VERSION ""

NS_ :

BS_:

BU_: ECM

BO_ 262 ENGINE_FD_2: 64 ECM
 SG_ TxAC_EMCC_rq_W : 189|1@0+ (1,0) [0|1] "-"  Vector__XXX
 SG_ TRANS_CLU_SLIP_MODE_W : 71|3@0+ (1,0) [0|7] "-"  Vector__XXX
 SG_ StartRelayBCMCmd_W : 187|1@0+ (1,0) [0|1] "-"  Vector__XXX
 SG_ PowertrainPrplsnActv : 181|1@0+ (1,0) [0|1] "" Vector__XXX
 SG_ MessageCounter_ENGINE2 : 435|4@0+ (1,0) [0|15] "-"  Vector__XXX
 SG_ LV12PwrFreeRq_W : 176|1@0+ (1,0) [0|1] "-"  Vector__XXX
 SG_ KickDownRequest_W : 182|1@0+ (1,0) [0|1] "-"  Vector__XXX
 SG_ IntakeAirTemperature_W : 151|8@0+ (1,-40) [-40|214] "C"  Vector__XXX
 SG_ GasPedalPositionFailSts_W : 169|1@0+ (1,0) [0|1] "-"  Vector__XXX
 SG_ GasPedalPosition_W : 143|8@0+ (0.392,0) [0|99.568] "%"  Vector__XXX
 SG_ GasPedalGradient_W : 159|8@0+ (0.195,-25) [-25|24.53] "% /10ms"  Vector__XXX
 SG_ FeedbackASR_ESCReq_W : 186|1@0+ (1,0) [0|1] "-"  Vector__XXX
 SG_ EVRDesiredSetpoint : 135|8@0+ (0.0625,0) [0|15.875] "V"  Vector__XXX
 SG_ ESS_RqShftPark_W : 115|1@0+ (1,0) [0|0] "-"  Vector__XXX
 SG_ ESS_ENG_ST_W : 175|4@0+ (1,0) [0|15] "-"  Vector__XXX
 SG_ EngTrq_Enbl_Rq_TCM_W : 178|1@0+ (1,0) [0|1] "-"  Vector__XXX
 SG_ EngRPM_Tach : 7|16@0+ (1,0) [0|65534] "rpm"  Vector__XXX
 SG_ EngineSts_W : 87|2@0+ (1,0) [0|3] "-"  Vector__XXX
 SG_ EngineSpeedFailSts_W : 168|1@0+ (1,0) [0|1] "-"  Vector__XXX
 SG_ EngineSpeed_W : 21|14@0+ (1,0) [0|16382] "1/min"  Vector__XXX
 SG_ EngineIdleRefSpeed : 35|12@0+ (1,0) [0|4094] "1/min"  Vector__XXX
 SG_ EngineFrictionTorque_W : 112|9@0+ (1,0) [0|510] "Nm"  Vector__XXX
 SG_ ECM_LHOM_W : 188|1@0+ (1,0) [0|1] "-"  Vector__XXX
 SG_ ECM_LHOM_Trans_W : 117|2@0+ (1,0) [0|3] "-"  Vector__XXX
 SG_ ECM_IMMO_STAT_CANC_W : 23|2@0+ (1,0) [0|0] "-"  Vector__XXX
 SG_ ECM_AllwEV_W : 170|1@0+ (1,0) [0|0] "-"  Vector__XXX
 SG_ CRC_ENGINE2 : 447|8@0+ (1,0) [0|255] "-"  Vector__XXX
 SG_ CrankHold_W : 179|1@0+ (1,0) [0|1] "-"  Vector__XXX
 SG_ AlternatorFail_W : 114|1@0+ (1,0) [0|1] "-"  Vector__XXX
 SG_ ECM_ParkSL_Status : 437|2@0+ (1,0) [0|2] "-"  Vector__XXX
 SG_ EngTrqTgt_SEM : 276|13@0+ (0.25,-500) [-500|1547.5] "Nm"  Vector__XXX
 SG_ ESS_EBOOST_BRKHLD_STATUS : 279|3@0+ (1,0) [0|6] "-"  Vector__XXX
 SG_ Engine_Stall_Detected : 197|1@0+ (1,0) [0|1] "-"  Vector__XXX
 SG_ FullOFC_Actv : 183|1@0+ (1,0) [0|1] "" Vector__XXX
 SG_ FuelConsumption_GAG_3 : 251|20@0+ (0.0022,0) [0|2306.865] "Liter / hour"  Vector__XXX
 SG_ EngFSO_TCM_Allw : 39|1@0+ (1,0) [0|1] "" Vector__XXX

BO_ 258 BRAKE_FD_2: 64 Vector__XXX
 SG_ VehicleSpeedVSOSig : 4|13@0+ (0.0625,0) [0|511.875] "Km/h"  ECM
 SG_ MessageCounter_BRAKE2 : 435|4@0+ (1,0) [0|15] "-"  ECM
 SG_ LongAccelerationFailSts_BSM : 69|1@0+ (1,0) [0|1] "-"  ECM
 SG_ LongAcceleration_BSM : 35|12@0+ (0.02,-40.96) [-40.96|40.92] "m/s^2"  ECM
 SG_ LatAccelerationFailSts_BSM : 68|1@0+ (1,0) [0|1] "-"  ECM
 SG_ LatAcceleration_BSM : 19|12@0+ (0.02,-40.96) [-40.96|40.92] "m/s^2"  ECM
 SG_ ImpendingSkid : 205|1@0+ (1,0) [0|1] "-"  ECM
 SG_ ESP_Sys_Stat : 71|2@0+ (1,0) [0|3] "-"  ECM
 SG_ CRC_BRAKE2 : 447|8@0+ (1,0) [0|255] "-"  ECM
 SG_ BrakePedalPressure : 386|11@0+ (0.1,0) [0|200] "bar"  ECM
 SG_ BrakeInterventionSts : 103|1@0+ (1,0) [0|1] "-"  ECM
 SG_ BrakeBoostPressure : 370|11@0+ (0.1,0) [0|200] "bar"  ECM
 SG_ Brk_Stat : 343|2@0+ (1,0) [0|2] "-"  ECM
 SG_ TotIntdTotalBrkTorq_FW : 173|14@0+ (0.32,0) [0|5242.24] "Nm"  ECM
 SG_ CmndTotBrkFrictTorq_FW : 253|14@0+ (0.32,0) [0|5242.24] "Nm"  ECM

BO_ 476 AGSM_FD_2: 32 Vector__XXX
 SG_ MessageCounter_AGSM2 : 179|4@0+ (1,0) [0|15] "-"  ECM
 SG_ CRC_AGSM2 : 191|8@0+ (1,0) [0|255] "-"  ECM
 SG_ ShiftLeverPositionReq : 95|4@0+ (1,0) [0|15] "-"  ECM

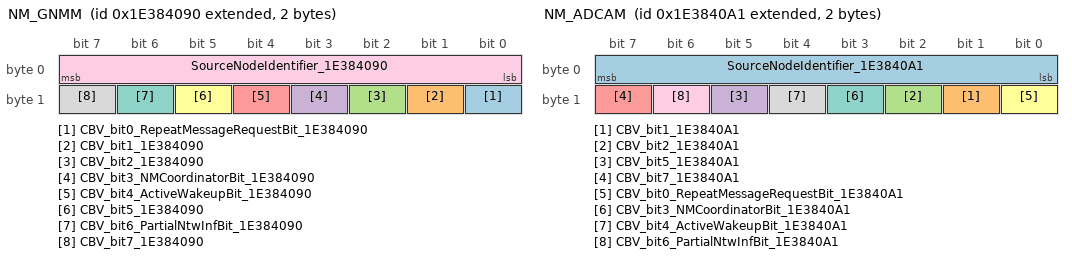
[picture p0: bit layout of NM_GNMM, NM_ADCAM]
BO_ 2654486672 NM_GNMM: 2 Vector__XXX
 SG_ CBV_bit0_RepeatMessageRequestBit_1E384090 : 8|1@0+ (1,0) [0|1] "" ECM
 SG_ CBV_bit1_1E384090 : 9|1@0+ (1,0) [0|1] "" ECM
 SG_ CBV_bit2_1E384090 : 10|1@0+ (1,0) [0|1] "" ECM
 SG_ CBV_bit3_NMCoordinatorBit_1E384090 : 11|1@0+ (1,0) [0|1] "" ECM
 SG_ CBV_bit4_ActiveWakeupBit_1E384090 : 12|1@0+ (1,0) [0|1] "" ECM
 SG_ CBV_bit5_1E384090 : 13|1@0+ (1,0) [0|1] "" ECM
 SG_ CBV_bit6_PartialNtwInfBit_1E384090 : 14|1@0+ (1,0) [0|1] "" ECM
 SG_ CBV_bit7_1E384090 : 15|1@0+ (1,0) [0|1] "" ECM
 SG_ SourceNodeIdentifier_1E384090 : 7|8@0+ (1,0) [0|255] "-"  ECM

BO_ 1460 FOTA_MASTER: 32 Vector__XXX
 SG_ FOTA_Status : 7|4@0+ (1,0) [0|15] "" ECM
 SG_ FOTA_Install_Type : 21|2@0+ (1,0) [0|3] "" ECM

BO_ 99 IMMO_SOP_REQUEST: 32 Vector__XXX
 SG_ IMMO_SOP_REQUEST : 7|1@0+ (1,0) [0|0] "-"  ECM

BO_ 2564486416 DIAGNOSTIC_RESPONSE_FOTA_ECM: 64 ECM
 SG_ N_PDU_18DAF510 : 7|64@0+ (1,0) [0|0] "" Vector__XXX

BO_ 2564428021 DIAGNOSTIC_REQUEST_FOTA_ECM: 64 Vector__XXX
 SG_ N_PDU_18DA10F5 : 7|64@0+ (1,0) [0|0] "" ECM

BO_ 280 ADAS_FD_INFO: 32 Vector__XXX
 SG_ MessageCounter_ADAS_FD_INFO : 179|4@0+ (1,0) [0|15] "-"  ECM
 SG_ CRC_ADAS_FD_INFO : 191|8@0+ (1,0) [0|255] "-"  ECM
 SG_ MRM_STATUS : 23|3@0+ (1,0) [0|6] "" ECM
 SG_ AEB_Systemsts : 99|2@0+ (1,0) [0|2] "-"  ECM
 SG_ ACC_Systemsts : 183|4@0+ (1,0) [0|14] "-"  ECM
 SG_ ACC_StopStart : 97|2@0+ (1,0) [0|2] "-"  ECM

BO_ 2564485597 DIAGNOSTIC_RESPONSE_ISCM: 8 ECM
 SG_ N_PDU_18DAF1DD : 7|64@0+ (1,0) [0|0] "" Vector__XXX

BO_ 2564480497 DIAGNOSTIC_REQUEST_ISCM: 8 Vector__XXX
 SG_ N_PDU_18DADDF1 : 7|64@0+ (1,0) [0|0] "" ECM

BO_ 834 GLIWA_T1_TX: 8 ECM
 SG_ N_PDU_342 : 7|64@0+ (1,0) [0|0] "" Vector__XXX

BO_ 835 GLIWA_T1_RX: 8 Vector__XXX
 SG_ N_PDU_343 : 7|64@0+ (1,0) [0|0] "" ECM

BO_ 2564554485 DIAGNOSTIC_REQUEST_FUNC_FOTA: 64 Vector__XXX
 SG_ N_PDU_18DBFEF5 : 7|64@0+ (1,0) [0|0] "" ECM

BO_ 205 BRAKE_FD_6: 64 Vector__XXX
 SG_ CRC_BRAKE_FD_6 : 447|8@0+ (1,0) [0|255] "-"  ECM
 SG_ MessageCounter_BRAKE_FD_6 : 435|4@0+ (1,0) [0|15] "-"  ECM
 SG_ TotalAxle_Min_Rq_BSM : 50|1@0+ (1,0) [0|1] "" ECM
 SG_ TotalAxle_Max_Rq_BSM : 51|1@0+ (1,0) [0|1] "" ECM
 SG_ DriverReq_AxleTrq_Enabled_BSM : 175|4@0+ (1,0) [0|15] "" ECM
 SG_ TotalAxle_Rq_BSM : 95|16@0+ (2,-65534) [-65534|65536] "Nm"  ECM
 SG_ DriverRequested_AxleTrq_BSM : 159|16@0+ (2,-65534) [-65534|65536] "Nm"  ECM
 SG_ Not_OK_To_Race : 239|3@0+ (1,0) [0|7] "" ECM

BO_ 204 AXLE_TORQUE_FD_1: 48 ECM
 SG_ MessageCounter_AXLE_TORQUE_FD_1 : 307|4@0+ (1,0) [0|15] "-"  Vector__XXX
 SG_ CRC_AXLE_TORQUE_FD_1 : 319|8@0+ (1,0) [0|255] "-"  Vector__XXX
 SG_ Rear_Axle_Regen_Capacity : 197|14@0+ (2,0) [0|32764] "Nm"  Vector__XXX
 SG_ Rear_Axle_Est_Regen_Torq : 181|14@0+ (2,0) [0|32764] "Nm"  Vector__XXX
 SG_ Front_Axle_Regen_Capacity : 165|14@0+ (2,0) [0|32764] "Nm"  Vector__XXX
 SG_ Front_Axle_Est_Regen_Torq : 149|14@0+ (2,0) [0|32764] "Nm"  Vector__XXX
 SG_ Total_AxleTorque_Min : 23|16@0+ (2,-65534) [-65534|65536] "Nm"  Vector__XXX
 SG_ Total_AxleTorque_Max : 7|16@0+ (2,-65534) [-65534|65536] "Nm"  Vector__XXX
 SG_ Axle_TorqueStatic_D_TTC : 39|16@0+ (2,-65534) [-65534|65536] "Nm"  Vector__XXX
 SG_ Axle_Torque_DrvReqMod : 55|16@0+ (2,-65534) [-65534|65536] "Nm"  Vector__XXX
 SG_ Rear_AxleTorque_Min : 119|16@0+ (2,-65534) [-65534|65536] "Nm"  Vector__XXX
 SG_ Rear_AxleTorque_Max : 103|16@0+ (2,-65534) [-65534|65536] "Nm"  Vector__XXX
 SG_ MaxRegen_Diff_Axle_Torq_Active : 135|1@0+ (1,0) [0|1] "" Vector__XXX
 SG_ MaxRegen_Diff_Axle_Torq : 134|15@0+ (2,0) [0|65532] "Nm"  Vector__XXX
 SG_ Front_AxleTorque_Min : 87|16@0+ (2,-65534) [-65534|65536] "Nm"  Vector__XXX
 SG_ Front_AxleTorque_Max : 71|16@0+ (2,-65534) [-65534|65536] "Nm"  Vector__XXX

BO_ 2654486689 NM_ADCAM: 2 Vector__XXX
 SG_ SourceNodeIdentifier_1E3840A1 : 7|8@0+ (1,0) [0|255] "-"  ECM
 SG_ CBV_bit1_1E3840A1 : 9|1@0+ (1,0) [0|1] "" ECM
 SG_ CBV_bit2_1E3840A1 : 10|1@0+ (1,0) [0|1] "" ECM
 SG_ CBV_bit5_1E3840A1 : 13|1@0+ (1,0) [0|1] "" ECM
 SG_ CBV_bit7_1E3840A1 : 15|1@0+ (1,0) [0|1] "" ECM
 SG_ CBV_bit0_RepeatMessageRequestBit_1E3840A1 : 8|1@0+ (1,0) [0|1] "-"  ECM
 SG_ CBV_bit3_NMCoordinatorBit_1E3840A1 : 11|1@0+ (1,0) [0|1] "-"  ECM
 SG_ CBV_bit4_ActiveWakeupBit_1E3840A1 : 12|1@0+ (1,0) [0|1] "-"  ECM
 SG_ CBV_bit6_PartialNtwInfBit_1E3840A1 : 14|1@0+ (1,0) [0|1] "-"  ECM

BO_ 2654339073 PDC_INFO_FD_ECM: 48 ECM
 SG_ GenericFailSts_FD03_ECM : 5|1@0+ (1,0) [0|1] "" Vector__XXX
 SG_ EOL_FD03_ECM : 7|1@0+ (1,0) [0|1] "-"  Vector__XXX
 SG_ CurrentFailSts_FD03_ECM : 6|1@0+ (1,0) [0|1] "" Vector__XXX
 SG_ WakeupSource_FD03_ECM : 23|8@0+ (1,0) [0|255] "" Vector__XXX
 SG_ PreviousCanNMState_FD03_ECM : 11|4@0+ (1,0) [0|15] "" Vector__XXX
 SG_ CurrentCanNMState_FD03_ECM : 15|4@0+ (1,0) [0|15] "" Vector__XXX
 SG_ StayActiveSource_FD03_ECM : 31|64@0+ (1,0) [0|18446744073709600000] "" Vector__XXX
 SG_ WakeupSource_FD16_ECM : 199|8@0+ (1,0) [0|255] "" Vector__XXX
 SG_ StayActiveSource_FD16_ECM : 207|64@0+ (1,0) [0|0] "" Vector__XXX
 SG_ PreviousCanNMState_FD16_ECM : 191|4@0+ (1,0) [0|15] "" Vector__XXX
 SG_ GenericFailSts_FD16_ECM : 184|1@0+ (1,0) [0|1] "" Vector__XXX
 SG_ EOL_FD16_ECM : 1|1@0+ (1,0) [0|1] "-"  Vector__XXX
 SG_ CurrentFailSts_FD16_ECM : 185|1@0+ (1,0) [0|1] "" Vector__XXX
 SG_ CurrentCanNMState_FD16_ECM : 179|4@0+ (1,0) [0|15] "" Vector__XXX
 SG_ DES_FD16_ECM : 187|2@0+ (1,0) [0|3] "" Vector__XXX
 SG_ DES_FD03_ECM : 4|2@0+ (1,0) [0|3] "" Vector__XXX

BO_ 263 PT_SYSTEM_FD_1: 64 Vector__XXX
 SG_ PowertrainPrplsnActv_PT : 146|1@0+ (1,0) [0|1] "" ECM
 SG_ GearEngagedForDisplay_PT : 12|5@0+ (1,0) [0|31] "" ECM
 SG_ MessageCounter_PT_SYSTEM_FD_1 : 435|4@0+ (1,0) [0|15] "-"  ECM
 SG_ CRC_PT_SYSTEM_FD_1 : 447|8@0+ (1,0) [0|255] "-"  ECM

BO_ 2564487440 DIAGNOSTIC_RESPONSE_FOTA_ECM_KWP: 8 ECM
 SG_ N_PDU_18DAF910 : 7|64@0+ (1,0) [0|0] "" Vector__XXX

BO_ 2564554489 DIAGNOSTIC_REQUEST_FUNC_FOTA_KWP: 8 Vector__XXX
 SG_ N_PDU_18DBFEF9 : 7|64@0+ (1,0) [0|0] "" ECM

BO_ 2564428025 DIAGNOSTIC_REQUEST_FOTA_ECM_KWP: 8 Vector__XXX
 SG_ N_PDU_18DA10F9 : 7|64@0+ (1,0) [0|0] "" ECM

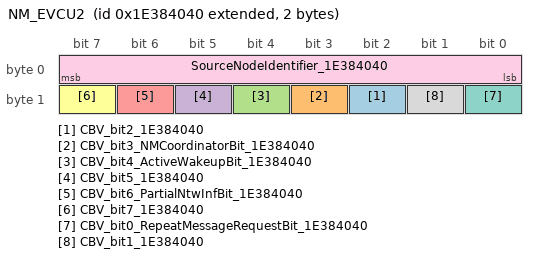
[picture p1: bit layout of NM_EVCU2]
BO_ 2654486592 NM_EVCU2: 2 Vector__XXX
 SG_ CBV_bit2_1E384040 : 10|1@0+ (1,0) [0|1] "" ECM
 SG_ CBV_bit3_NMCoordinatorBit_1E384040 : 11|1@0+ (1,0) [0|1] "" ECM
 SG_ CBV_bit4_ActiveWakeupBit_1E384040 : 12|1@0+ (1,0) [0|1] "" ECM
 SG_ CBV_bit5_1E384040 : 13|1@0+ (1,0) [0|1] "" ECM
 SG_ CBV_bit6_PartialNtwInfBit_1E384040 : 14|1@0+ (1,0) [0|1] "" ECM
 SG_ CBV_bit7_1E384040 : 15|1@0+ (1,0) [0|1] "" ECM
 SG_ CBV_bit0_RepeatMessageRequestBit_1E384040 : 8|1@0+ (1,0) [0|1] "" ECM
 SG_ CBV_bit1_1E384040 : 9|1@0+ (1,0) [0|1] "" ECM
 SG_ SourceNodeIdentifier_1E384040 : 7|8@0+ (1,0) [0|255] "-"  ECM

BO_ 577 SYNCHRO_DC_GLOBAL: 32 ECM
 SG_ QualifyDriveCycle : 7|1@0+ (1,0) [0|1] "" Vector__XXX

CM_ SG_ 263 CRC_PT_SYSTEM_FD_1 "CRC according to SAE J1850 standard at each frame transmission.";
CM_ SG_ 263 MessageCounter_PT_SYSTEM_FD_1 "This signal is a counter used for safety checks strategies. This counter is incremented of 1 (one) unit at each frame transmission.";
CM_ SG_ 263 GearEngagedForDisplay_PT "Transmission Gear Engaged signal for the instrument cluster display";
CM_ SG_ 263 PowertrainPrplsnActv_PT "Powertrain Propulsion System Status";
CM_ SG_ 2654486689 CBV_bit0_RepeatMessageRequestBit_1E3840A1 "Repeat Message Request Bit";
CM_ SG_ 2654486689 CBV_bit3_NMCoordinatorBit_1E3840A1 "NM Coordinator Sleep Bit";
CM_ SG_ 2654486689 CBV_bit4_ActiveWakeupBit_1E3840A1 "Active Wakeup Bit";
CM_ SG_ 2654486689 CBV_bit6_PartialNtwInfBit_1E3840A1 "Partial Network Information Bit (PNI)";
CM_ SG_ 2654486689 SourceNodeIdentifier_1E3840A1 "Source Node Identifier";
CM_ SG_ 835 N_PDU_343 "This signal is used for diagnostic purposes";
CM_ SG_ 2564480497 N_PDU_18DADDF1 "This signal is used for diagnostic purposes";
CM_ SG_ 834 N_PDU_342 "This signal is used for diagnostic purposes";
CM_ SG_ 2564485597 N_PDU_18DAF1DD "This signal is used for diagnostic purposes";
CM_ SG_ 2564428025 N_PDU_18DA10F9 "This signal is used for diagnostic purposes";
CM_ SG_ 2564554489 N_PDU_18DBFEF9 "This signal is used for diagnostic purposes";
CM_ SG_ 205 CRC_BRAKE_FD_6 "CRC according to SAE J1850 standard at each frame transmission.";
CM_ SG_ 205 MessageCounter_BRAKE_FD_6 "This signal is a counter used for safety checks strategies. This counter is incremented of 1 (one) unit at each frame transmission.";
CM_ SG_ 205 Not_OK_To_Race "Not ok to race";
CM_ SG_ 205 DriverRequested_AxleTrq_BSM "Virtual driver torque request from BSM";
CM_ SG_ 205 TotalAxle_Rq_BSM "Combined axle traction torque request";
CM_ SG_ 205 DriverReq_AxleTrq_Enabled_BSM "It indicates the request to enable virtual driver torque interface for BSM driver functions";
CM_ SG_ 205 TotalAxle_Max_Rq_BSM "Combined axle traction torque max limit flag. Active = [1]";
CM_ SG_ 205 TotalAxle_Min_Rq_BSM "Combined axle traction torque min limit flag. Active = [1]";
CM_ SG_ 2564554485 N_PDU_18DBFEF5 "This signal is used for diagnostic purposes";
CM_ SG_ 280 CRC_ADAS_FD_INFO "CRC according to SAE J1850 standard at each frame transmission.";
CM_ SG_ 280 ACC_Systemsts "ACC System Status";
CM_ SG_ 280 MessageCounter_ADAS_FD_INFO "This signal is a counter used for safety checks strategies. This counter is incremented of 1 (one) unit at each frame transmission.";
CM_ SG_ 280 AEB_Systemsts "AEB System Status";
CM_ SG_ 280 ACC_StopStart "Allows StopStart when ACC is engaged";
CM_ SG_ 280 MRM_STATUS "Status of the minimum risk maneuver to handle system faults or driver abuse as understood by primary controller";
CM_ SG_ 2564428021 N_PDU_18DA10F5 "This signal is used for diagnostic purposes";
CM_ SG_ 99 IMMO_SOP_REQUEST "Signals ECM to initiate Immobilizer handshake.";
CM_ SG_ 1460 FOTA_Install_Type "Type of FOTA Installation";
CM_ SG_ 1460 FOTA_Status "FOTA_Status";
CM_ SG_ 2654486672 CBV_bit0_RepeatMessageRequestBit_1E384090 "Repeat Message Request Bit";
CM_ SG_ 2654486672 CBV_bit3_NMCoordinatorBit_1E384090 "NM Coordinator Sleep Bit";
CM_ SG_ 2654486672 CBV_bit4_ActiveWakeupBit_1E384090 "Active Wakeup Bit";
CM_ SG_ 2654486672 CBV_bit6_PartialNtwInfBit_1E384090 "Partial Network Information Bit (PNI)";
CM_ SG_ 2654486672 SourceNodeIdentifier_1E384090 "Source Node Identifier";
CM_ SG_ 476 ShiftLeverPositionReq "This signal describes the shift lever position requested by the driver.";
CM_ SG_ 476 CRC_AGSM2 "CRC according to SAE J1850 standard at each frame transmission.";
CM_ SG_ 476 MessageCounter_AGSM2 "This signal is a counter used for safety checks strategies. This counter is incremented of 1 (one) unit at each frame transmission.";
CM_ SG_ 258 LongAccelerationFailSts_BSM "This signal indicates the status of Longitudinal acceleration signal";
CM_ SG_ 258 LatAccelerationFailSts_BSM "This signal indicates the status of Lateral Acceleration Signal";
CM_ SG_ 258 LongAcceleration_BSM "This signal indicates the Longitudinal Acceleration Value";
CM_ SG_ 258 LatAcceleration_BSM "This signal indicates the Lateral Acceleration Value";
CM_ SG_ 258 ESP_Sys_Stat "0";
CM_ SG_ 258 ImpendingSkid "Impending Skid; impending skid false = [0], impending skid true = [1]";
CM_ SG_ 258 MessageCounter_BRAKE2 "This signal is a counter used for safety checks strategies. This counter is incremented of 1 (one) unit at each frame transmission.";
CM_ SG_ 258 VehicleSpeedVSOSig "It is the average vehicle speed calculated.";
CM_ SG_ 258 Brk_Stat "Brake state";
CM_ SG_ 258 BrakeBoostPressure "Pressure Information from Brake Booster Pressure Sensor";
CM_ SG_ 258 BrakeInterventionSts "This signal is ?active? when the brake intervention is due to BSM events and ?not active? when the brake intervention is due to the driver";
CM_ SG_ 258 BrakePedalPressure "Pressure Information from Brake Pedal Simulator Pressure Sensor";
CM_ SG_ 258 CRC_BRAKE2 "CRC according to SAE J1850 standard at each frame transmission.";
CM_ SG_ 258 CmndTotBrkFrictTorq_FW "Commanded Total Brake Friction torque in Flywheel domain";
CM_ SG_ 258 TotIntdTotalBrkTorq_FW "Total Brake Torque in Flywheel domain";
CM_ SG_ 577 QualifyDriveCycle "Qualified Drive Cycle";
CM_ SG_ 2564487440 N_PDU_18DAF910 "This signal is used for diagnostic purposes";
CM_ SG_ 2654339073 PreviousCanNMState_FD16_ECM "Indicates the last CanNM state that the ECU existed in";
CM_ SG_ 2654339073 StayActiveSource_FD16_ECM "Indicates the source that requests the ECU to stay active";
CM_ SG_ 2654339073 WakeupSource_FD16_ECM "Indicates the reason the ECU was most recently awakened";
CM_ SG_ 2654339073 StayActiveSource_FD03_ECM "Indicates the source that requests the ECU to stay active";
CM_ SG_ 2654339073 CurrentCanNMState_FD03_ECM "Indicates that CanNM state the ECU is currently executing";
CM_ SG_ 2654339073 PreviousCanNMState_FD03_ECM "Indicates the last CanNM state that the ECU existed in";
CM_ SG_ 2654339073 DES_FD03_ECM "Indicates whether the ECU?s CAN cell is in either ErrorActive, or ErrorPassive state OR has just now recovered from a BusOff condition";
CM_ SG_ 2654339073 DES_FD16_ECM "Indicates whether the ECU?s CAN cell is in either ErrorActive, or ErrorPassive state OR has just now recovered from a BusOff condition";
CM_ SG_ 2654339073 CurrentCanNMState_FD16_ECM "Indicates that CanNM state the ECU is currently executing";
CM_ SG_ 2654339073 CurrentFailSts_FD16_ECM "Indicates the presence/absence of at least one DTC with DTCStatus = present in the System Memory";
CM_ SG_ 2654339073 EOL_FD16_ECM "Indicates if the ECU requires configuration data at the assembly plant End Of Line";
CM_ SG_ 2654339073 GenericFailSts_FD16_ECM "Indicates the presence/absent of at least one DTC in the System Memory";
CM_ SG_ 2654339073 WakeupSource_FD03_ECM "Indicates the reason the ECU was most recently awakened";
CM_ SG_ 2654339073 CurrentFailSts_FD03_ECM "Indicates the presence/absence of at least one DTC with DTCStatus = present in the System Memory";
CM_ SG_ 2654339073 EOL_FD03_ECM "Indicates if the ECU requires configuration data at the assembly plant End Of Line";
CM_ SG_ 2654339073 GenericFailSts_FD03_ECM "Indicates the presence/absent of at least one DTC in the System Memory";
CM_ SG_ 204 Rear_Axle_Regen_Capacity "Regenerative Braking rear Axle Torque Capability";
CM_ SG_ 204 Rear_Axle_Est_Regen_Torq "Estimated regen Braking Torque at the Rear axle";
CM_ SG_ 204 Front_Axle_Regen_Capacity "Regenerative Braking front Axle Torque Capability";
CM_ SG_ 204 Front_Axle_Est_Regen_Torq "Estimated regen Braking Torque at the Front axle";
CM_ SG_ 204 MaxRegen_Diff_Axle_Torq_Active "Max Regen torque request; Active = [1]";
CM_ SG_ 204 MaxRegen_Diff_Axle_Torq "Difference between Max Regen and normal coasting torques";
CM_ SG_ 204 Rear_AxleTorque_Min "Minimum rear Axle torque";
CM_ SG_ 204 Rear_AxleTorque_Max "Maximum rear Axle torque";
CM_ SG_ 204 Front_AxleTorque_Min "Minimum front Axle torque";
CM_ SG_ 204 Front_AxleTorque_Max "Maximum front Axle torque";
CM_ SG_ 204 Axle_Torque_DrvReqMod "Driver requested Axle torque raw (no torque shaping)";
CM_ SG_ 204 Axle_TorqueStatic_D_TTC "Driver requested Axle torque (filtered/ torque shaped)";
CM_ SG_ 204 Total_AxleTorque_Max "Maximum total Axle torque";
CM_ SG_ 204 Total_AxleTorque_Min "Minimum total Axle torque";
CM_ SG_ 204 CRC_AXLE_TORQUE_FD_1 "CRC according to SAE J1850 standard at each frame transmission.";
CM_ SG_ 204 MessageCounter_AXLE_TORQUE_FD_1 "This signal is a counter used for safety checks strategies. This counter is incremented of 1 (one) unit at each frame transmission.";
CM_ SG_ 2564486416 N_PDU_18DAF510 "This signal is used for diagnostic purposes";
CM_ SG_ 262 GasPedalPositionFailSts_W "-";
CM_ SG_ 262 KickDownRequest_W "It is set to KD_requested whenever the Kick-Down condition is detected by the ECM.";
CM_ SG_ 262 LV12PwrFreeRq_W "-";
CM_ SG_ 262 MessageCounter_ENGINE2 "This signal is a counter used for safety checks strategies. This counter is incremented of 1 (one) unit at each frame transmission.";
CM_ SG_ 262 PowertrainPrplsnActv "Powertrain Propulsion Status.";
CM_ SG_ 262 ESS_ENG_ST_W "ESS Engine State";
CM_ SG_ 262 ESS_RqShftPark_W "ESS Request shift to Park.  1 = True, 0 = False";
CM_ SG_ 262 EVRDesiredSetpoint "Electronic Voltage Regulator Desired Voltage Set-Point.";
CM_ SG_ 262 FeedbackASR_ESCReq_W "It is set to Not Valid, when the plausibility conditions about ASR / ESC torque request are not fulfilled . Nevertheless, it shall not be set to Not Valid, due to ValidData bits Not Valid transmitted from BSM.";
CM_ SG_ 262 GasPedalGradient_W "-";
CM_ SG_ 262 GasPedalPosition_W "-";
CM_ SG_ 262 EngineIdleRefSpeed "This signal represents target of engine speed for the idle control function, at the end of dynamic transient conditions. It takes into account changes of idle speed due to temperature and auxiliary loads. It is updated even when the engine is ou(...)";
CM_ SG_ 262 EngineSpeed_W "It gives information on C-CAN network about  engine speed";
CM_ SG_ 262 EngineSpeedFailSts_W "Used to indicate if a Fail is present for the engine speed";
CM_ SG_ 262 EngineSts_W "-";
CM_ SG_ 262 EngRPM_Tach "Engine revolutions per minute for indication";
CM_ SG_ 262 EngTrq_Enbl_Rq_TCM_W "Allow TRANS torque request";
CM_ SG_ 262 CRC_ENGINE2 "CRC according to SAE J1850 standard at each frame transmission.";
CM_ SG_ 262 ECM_AllwEV_W "ECM allow EV mode";
CM_ SG_ 262 ECM_IMMO_STAT_CANC_W "ECM immobilizer status";
CM_ SG_ 262 ECM_LHOM_Trans_W "Indicates to the transmission the Limp Home Status of ECM and Torque Accuracy";
CM_ SG_ 262 ECM_LHOM_W "-";
CM_ SG_ 262 EngineFrictionTorque_W "-";
CM_ SG_ 262 FuelConsumption_GAG_3 "Fuel consumption";
CM_ SG_ 262 FullOFC_Actv "Cylinder cut-out";
CM_ SG_ 262 Engine_Stall_Detected "Engine stall detected flag";
CM_ SG_ 262 ECM_ParkSL_Status "ECM command to park pawl hold solenoid (Energize/De-energize).";
CM_ SG_ 262 AlternatorFail_W "Indicates if the alternator is in fail condition";
CM_ SG_ 262 CrankHold_W "Used by ECM to command an action to the BCM cranking relay during cranking phase";
CM_ SG_ 262 EngFSO_TCM_Allw "Engine Fuel Shut Off Allowed";
CM_ SG_ 262 StartRelayBCMCmd_W "Used by ECM to command an action to the BCM cranking relay.";
CM_ SG_ 262 TRANS_CLU_SLIP_MODE_W "-";
CM_ SG_ 262 TxAC_EMCC_rq_W "-";
CM_ SG_ 262 ESS_EBOOST_BRKHLD_STATUS "ESS brake hold release status";
CM_ SG_ 262 EngTrqTgt_SEM "Final Target  torque produced by  combustion engine without Shift Intervention torque requests";
BA_DEF_ SG_ "GenSigTimeoutTime_ADCAM" INT 0 65535;
BA_DEF_ SG_ "GenSigTimeoutTime_EVCU2" INT 0 65535;
BA_DEF_ SG_ "GenSigTimeoutTime_VDCM" INT 0 65535;
BA_DEF_ SG_ "GenSigStartValue" INT 0 2147483647;
BA_DEF_ SG_ "GenSigInactiveValue" INT 0 2147483647;
BA_DEF_ SG_ "GenSigSendType" ENUM "NotUsed","OnWrite","OnWriteWithRepetition","OnChange","OnChangeWithRepetition","IfActive","IfActiveWithRepetition","NoSigSendType";
BA_DEF_ SG_ "SystemSignalLongSymbol" STRING ;
BA_DEF_ SG_ "GenSigTimeoutTime_AGSM" INT 0 65535;
BA_DEF_ SG_ "GenSigTimeoutTime_ASBS" INT 0 65535;
BA_DEF_ SG_ "GenSigTimeoutTime_BCM" INT 0 65535;
BA_DEF_ SG_ "GenSigTimeoutTime_BSM" INT 0 65535;
BA_DEF_ SG_ "GenSigTimeoutTime_CADM" INT 0 65535;
BA_DEF_ SG_ "GenSigTimeoutTime_DMSM" INT 0 65535;
BA_DEF_ SG_ "GenSigTimeoutTime_DTCM" INT 0 65535;
BA_DEF_ SG_ "GenSigTimeoutTime_ECM" INT 0 65535;
BA_DEF_ SG_ "GenSigTimeoutTime_ELSDM" INT 0 65535;
BA_DEF_ SG_ "GenSigTimeoutTime_ESL" INT 0 65535;
BA_DEF_ SG_ "GenSigTimeoutTime_GNMM" INT 0 65535;
BA_DEF_ SG_ "GenSigTimeoutTime_HCP" INT 0 65535;
BA_DEF_ SG_ "GenSigTimeoutTime_IPC" INT 0 65535;
BA_DEF_ SG_ "GenSigTimeoutTime_RFHM" INT 0 65535;
BA_DEF_ SG_ "GenSigTimeoutTime_SGW" INT 0 65535;
BA_DEF_ SG_ "GenSigTimeoutTime_TCM" INT 0 65535;
BA_DEF_ BO_ "DiagRequest" ENUM "No","Yes";
BA_DEF_ BO_ "Type" ENUM "P","C","PE","COC","PE_Cntrl","E","E_Cntrl","OC","S","BAF","DC","EM","MM","ISO-TP","-";
BA_DEF_ BO_ "DiagResponse" ENUM "No","Yes";
BA_DEF_ BO_ "NmMessage" ENUM "No","Yes";
BA_DEF_ BO_ "GenMsgSendType" ENUM "Cyclic","NotUsed","NotUsed","NotUsed","NotUsed","NotUsed","NotUsed","NotUsed","NoMsgSendType";
BA_DEF_ BO_ "GenMsgNrOfRepetition" INT 0 255;
BA_DEF_ BO_ "GenMsgILSupport" ENUM "No","Yes";
BA_DEF_ BO_ "GenMsgStartDelayTime" INT 0 65535;
BA_DEF_ BO_ "GenMsgCycleTimeFast" INT 0 65535;
BA_DEF_ BO_ "GenMsgCycleTime" INT 0 65535;
BA_DEF_ BO_ "GenMsgDelayTime" INT 0 65535;
BA_DEF_ BO_ "NmAsrMessage" ENUM "No","Yes";
BA_DEF_ BO_ "DiagState" ENUM "No","Yes";
BA_DEF_ BO_ "DiagConnection" HEX 0 65535;
BA_DEF_ BO_ "VFrameFormat" ENUM "StandardCAN","ExtendedCAN","reserved","reserved","reserved","reserved","reserved","reserved","reserved","reserved","reserved","reserved","reserved","reserved","StandardCAN_FD","ExtendedCAN_FD";
BA_DEF_ BO_ "CANFD_BRS" ENUM "0","1";
BA_DEF_DEF_ "GenSigTimeoutTime_ADCAM" 2500;
BA_DEF_DEF_ "GenSigTimeoutTime_EVCU2" 2500;
BA_DEF_DEF_ "GenSigTimeoutTime_VDCM" 2500;
BA_DEF_DEF_ "GenSigStartValue" 0;
BA_DEF_DEF_ "GenSigInactiveValue" 0;
BA_DEF_DEF_ "GenSigSendType" "NoSigSendType";
BA_DEF_DEF_ "SystemSignalLongSymbol" "";
BA_DEF_DEF_ "GenSigTimeoutTime_AGSM" 2500;
BA_DEF_DEF_ "GenSigTimeoutTime_ASBS" 2500;
BA_DEF_DEF_ "GenSigTimeoutTime_BCM" 2500;
BA_DEF_DEF_ "GenSigTimeoutTime_BSM" 2500;
BA_DEF_DEF_ "GenSigTimeoutTime_CADM" 2500;
BA_DEF_DEF_ "GenSigTimeoutTime_DMSM" 2500;
BA_DEF_DEF_ "GenSigTimeoutTime_DTCM" 2500;
BA_DEF_DEF_ "GenSigTimeoutTime_ECM" 2500;
BA_DEF_DEF_ "GenSigTimeoutTime_ELSDM" 2500;
BA_DEF_DEF_ "GenSigTimeoutTime_ESL" 2500;
BA_DEF_DEF_ "GenSigTimeoutTime_GNMM" 2500;
BA_DEF_DEF_ "GenSigTimeoutTime_HCP" 2500;
BA_DEF_DEF_ "GenSigTimeoutTime_IPC" 2500;
BA_DEF_DEF_ "GenSigTimeoutTime_RFHM" 2500;
BA_DEF_DEF_ "GenSigTimeoutTime_SGW" 2500;
BA_DEF_DEF_ "GenSigTimeoutTime_TCM" 2500;
BA_DEF_DEF_ "DiagRequest" "No";
BA_DEF_DEF_ "Type" "-";
BA_DEF_DEF_ "DiagResponse" "No";
BA_DEF_DEF_ "NmMessage" "No";
BA_DEF_DEF_ "GenMsgSendType" "NoMsgSendType";
BA_DEF_DEF_ "GenMsgNrOfRepetition" 0;
BA_DEF_DEF_ "GenMsgILSupport" "No";
BA_DEF_DEF_ "GenMsgStartDelayTime" 0;
BA_DEF_DEF_ "GenMsgCycleTimeFast" 0;
BA_DEF_DEF_ "GenMsgCycleTime" 0;
BA_DEF_DEF_ "GenMsgDelayTime" 0;
BA_DEF_DEF_ "NmAsrMessage" "No";
BA_DEF_DEF_ "DiagState" "No";
BA_DEF_DEF_ "DiagConnection" 0;
BA_DEF_DEF_ "VFrameFormat" "StandardCAN_FD";
BA_DEF_DEF_ "CANFD_BRS" "0";
BA_ "Type" BO_ 577 3;
BA_ "GenMsgSendType" BO_ 577 0;
BA_ "GenMsgILSupport" BO_ 577 1;
BA_ "GenMsgCycleTime" BO_ 577 1000;
BA_ "GenMsgDelayTime" BO_ 577 20;
BA_ "CANFD_BRS" BO_ 577 1;
BA_ "Type" BO_ 2564487440 8;
BA_ "DiagResponse" BO_ 2564487440 1;
BA_ "DiagConnection" BO_ 2564487440 63760;
BA_ "VFrameFormat" BO_ 2564487440 1;
BA_ "Type" BO_ 2654339073 1;
BA_ "GenMsgSendType" BO_ 2654339073 0;
BA_ "GenMsgILSupport" BO_ 2654339073 1;
BA_ "GenMsgStartDelayTime" BO_ 2654339073 385;
BA_ "Type" BO_ 2654486592 8;
BA_ "NmMessage" BO_ 2654486592 1;
BA_ "NmAsrMessage" BO_ 2654486592 1;
BA_ "VFrameFormat" BO_ 2654486592 15;
BA_ "CANFD_BRS" BO_ 2654486592 1;
BA_ "Type" BO_ 263 1;
BA_ "GenMsgSendType" BO_ 263 0;
BA_ "GenMsgILSupport" BO_ 263 1;
BA_ "GenMsgStartDelayTime" BO_ 263 45;
BA_ "GenMsgCycleTime" BO_ 263 10;
BA_ "CANFD_BRS" BO_ 263 1;
BA_ "Type" BO_ 2654486689 8;
BA_ "NmMessage" BO_ 2654486689 1;
BA_ "NmAsrMessage" BO_ 2654486689 1;
BA_ "VFrameFormat" BO_ 2654486689 15;
BA_ "CANFD_BRS" BO_ 2654486689 1;
BA_ "Type" BO_ 835 8;
BA_ "GenMsgILSupport" BO_ 835 1;
BA_ "CANFD_BRS" BO_ 835 1;
BA_ "DiagRequest" BO_ 2564480497 1;
BA_ "Type" BO_ 2564480497 8;
BA_ "DiagConnection" BO_ 2564480497 61917;
BA_ "VFrameFormat" BO_ 2564480497 1;
BA_ "Type" BO_ 834 8;
BA_ "GenMsgILSupport" BO_ 834 1;
BA_ "CANFD_BRS" BO_ 834 1;
BA_ "Type" BO_ 2564485597 8;
BA_ "DiagResponse" BO_ 2564485597 1;
BA_ "DiagConnection" BO_ 2564485597 61917;
BA_ "VFrameFormat" BO_ 2564485597 1;
BA_ "DiagRequest" BO_ 2564428025 1;
BA_ "Type" BO_ 2564428025 8;
BA_ "DiagConnection" BO_ 2564428025 63760;
BA_ "VFrameFormat" BO_ 2564428025 1;
BA_ "Type" BO_ 2564554489 8;
BA_ "DiagState" BO_ 2564554489 1;
BA_ "DiagConnection" BO_ 2564554489 63998;
BA_ "VFrameFormat" BO_ 2564554489 1;
BA_ "Type" BO_ 205 1;
BA_ "GenMsgSendType" BO_ 205 0;
BA_ "GenMsgILSupport" BO_ 205 1;
BA_ "GenMsgCycleTime" BO_ 205 10;
BA_ "CANFD_BRS" BO_ 205 1;
BA_ "Type" BO_ 2564554485 8;
BA_ "DiagState" BO_ 2564554485 1;
BA_ "DiagConnection" BO_ 2564554485 62974;
BA_ "VFrameFormat" BO_ 2564554485 15;
BA_ "CANFD_BRS" BO_ 2564554485 1;
BA_ "Type" BO_ 280 1;
BA_ "GenMsgSendType" BO_ 280 0;
BA_ "GenMsgILSupport" BO_ 280 1;
BA_ "GenMsgCycleTime" BO_ 280 10;
BA_ "CANFD_BRS" BO_ 280 1;
BA_ "DiagRequest" BO_ 2564428021 1;
BA_ "Type" BO_ 2564428021 8;
BA_ "DiagConnection" BO_ 2564428021 62736;
BA_ "VFrameFormat" BO_ 2564428021 15;
BA_ "CANFD_BRS" BO_ 2564428021 1;
BA_ "Type" BO_ 99 8;
BA_ "GenMsgNrOfRepetition" BO_ 99 2;
BA_ "GenMsgILSupport" BO_ 99 1;
BA_ "GenMsgCycleTimeFast" BO_ 99 20;
BA_ "GenMsgDelayTime" BO_ 99 20;
BA_ "CANFD_BRS" BO_ 99 1;
BA_ "Type" BO_ 1460 3;
BA_ "GenMsgSendType" BO_ 1460 0;
BA_ "GenMsgILSupport" BO_ 1460 1;
BA_ "GenMsgStartDelayTime" BO_ 1460 155;
BA_ "GenMsgCycleTime" BO_ 1460 1000;
BA_ "GenMsgDelayTime" BO_ 1460 20;
BA_ "CANFD_BRS" BO_ 1460 1;
BA_ "Type" BO_ 2654486672 8;
BA_ "NmMessage" BO_ 2654486672 1;
BA_ "NmAsrMessage" BO_ 2654486672 1;
BA_ "VFrameFormat" BO_ 2654486672 15;
BA_ "CANFD_BRS" BO_ 2654486672 1;
BA_ "Type" BO_ 476 3;
BA_ "GenMsgSendType" BO_ 476 0;
BA_ "GenMsgNrOfRepetition" BO_ 476 2;
BA_ "GenMsgILSupport" BO_ 476 1;
BA_ "GenMsgCycleTimeFast" BO_ 476 20;
BA_ "GenMsgCycleTime" BO_ 476 20;
BA_ "GenMsgDelayTime" BO_ 476 15;
BA_ "CANFD_BRS" BO_ 476 1;
BA_ "Type" BO_ 258 1;
BA_ "GenMsgSendType" BO_ 258 0;
BA_ "GenMsgILSupport" BO_ 258 1;
BA_ "GenMsgCycleTime" BO_ 258 10;
BA_ "CANFD_BRS" BO_ 258 1;
BA_ "GenMsgCycleTime" BO_ 2654339073 1000;
BA_ "VFrameFormat" BO_ 2654339073 15;
BA_ "CANFD_BRS" BO_ 2654339073 1;
BA_ "Type" BO_ 204 1;
BA_ "GenMsgSendType" BO_ 204 0;
BA_ "GenMsgILSupport" BO_ 204 1;
BA_ "GenMsgCycleTime" BO_ 204 10;
BA_ "CANFD_BRS" BO_ 204 1;
BA_ "Type" BO_ 2564486416 8;
BA_ "DiagResponse" BO_ 2564486416 1;
BA_ "DiagConnection" BO_ 2564486416 62736;
BA_ "VFrameFormat" BO_ 2564486416 15;
BA_ "CANFD_BRS" BO_ 2564486416 1;
BA_ "Type" BO_ 262 1;
BA_ "GenMsgSendType" BO_ 262 0;
BA_ "GenMsgILSupport" BO_ 262 1;
BA_ "GenMsgCycleTime" BO_ 262 10;
BA_ "CANFD_BRS" BO_ 262 1;
BA_ "GenSigTimeoutTime_RFHM" SG_ 262 ECM_IMMO_STAT_CANC_W 0;
BA_ "GenSigTimeoutTime_SGW" SG_ 262 ECM_IMMO_STAT_CANC_W 0;
BA_ "GenSigTimeoutTime_TCM" SG_ 262 ECM_IMMO_STAT_CANC_W 0;
BA_ "GenSigTimeoutTime_AGSM" SG_ 262 ECM_LHOM_Trans_W 0;
BA_ "GenSigTimeoutTime_ASBS" SG_ 262 ECM_LHOM_Trans_W 0;
BA_ "GenSigTimeoutTime_BCM" SG_ 262 ECM_LHOM_Trans_W 0;
BA_ "GenSigTimeoutTime_BSM" SG_ 262 ECM_LHOM_Trans_W 0;
BA_ "GenSigTimeoutTime_CADM" SG_ 262 ECM_LHOM_Trans_W 0;
BA_ "GenSigTimeoutTime_DMSM" SG_ 262 ECM_LHOM_Trans_W 0;
BA_ "GenSigTimeoutTime_DTCM" SG_ 262 ECM_LHOM_Trans_W 0;
BA_ "GenSigTimeoutTime_ECM" SG_ 262 ECM_LHOM_Trans_W 0;
BA_ "GenSigTimeoutTime_ELSDM" SG_ 262 ECM_LHOM_Trans_W 0;
BA_ "GenSigTimeoutTime_ESL" SG_ 262 ECM_LHOM_Trans_W 0;
BA_ "GenSigTimeoutTime_GNMM" SG_ 262 ECM_LHOM_Trans_W 0;
BA_ "GenSigTimeoutTime_IPC" SG_ 262 ECM_LHOM_Trans_W 0;
BA_ "GenSigTimeoutTime_RFHM" SG_ 262 ECM_LHOM_Trans_W 0;
BA_ "GenSigTimeoutTime_SGW" SG_ 262 ECM_LHOM_Trans_W 0;
BA_ "GenSigTimeoutTime_TCM" SG_ 262 ECM_LHOM_Trans_W 0;
BA_ "GenSigTimeoutTime_AGSM" SG_ 262 ECM_LHOM_W 0;
BA_ "GenSigTimeoutTime_ASBS" SG_ 262 ECM_LHOM_W 0;
BA_ "GenSigTimeoutTime_BCM" SG_ 262 ECM_LHOM_W 0;
BA_ "GenSigTimeoutTime_BSM" SG_ 262 ECM_LHOM_W 0;
BA_ "GenSigTimeoutTime_CADM" SG_ 262 ECM_LHOM_W 0;
BA_ "GenSigTimeoutTime_DMSM" SG_ 262 ECM_LHOM_W 0;
BA_ "GenSigTimeoutTime_DTCM" SG_ 262 ECM_LHOM_W 0;
BA_ "GenSigTimeoutTime_ECM" SG_ 262 ECM_LHOM_W 0;
BA_ "GenSigTimeoutTime_ELSDM" SG_ 262 ECM_LHOM_W 0;
BA_ "GenSigTimeoutTime_ESL" SG_ 262 ECM_LHOM_W 0;
BA_ "GenSigTimeoutTime_GNMM" SG_ 262 ECM_LHOM_W 0;
BA_ "GenSigTimeoutTime_IPC" SG_ 262 ECM_LHOM_W 0;
BA_ "GenSigTimeoutTime_RFHM" SG_ 262 ECM_LHOM_W 0;
BA_ "GenSigTimeoutTime_SGW" SG_ 262 ECM_LHOM_W 0;
BA_ "GenSigTimeoutTime_TCM" SG_ 262 ECM_LHOM_W 0;
BA_ "GenSigTimeoutTime_AGSM" SG_ 262 EngineFrictionTorque_W 0;
BA_ "GenSigTimeoutTime_ASBS" SG_ 262 EngineFrictionTorque_W 0;
BA_ "GenSigTimeoutTime_BSM" SG_ 262 EngineFrictionTorque_W 0;
BA_ "GenSigTimeoutTime_CADM" SG_ 262 EngineFrictionTorque_W 0;
BA_ "GenSigTimeoutTime_DMSM" SG_ 262 EngineFrictionTorque_W 0;
BA_ "GenSigTimeoutTime_DTCM" SG_ 262 EngineFrictionTorque_W 0;
BA_ "GenSigTimeoutTime_ECM" SG_ 262 EngineFrictionTorque_W 0;
BA_ "GenSigTimeoutTime_ELSDM" SG_ 262 EngineFrictionTorque_W 0;
BA_ "GenSigTimeoutTime_ESL" SG_ 262 EngineFrictionTorque_W 0;
BA_ "GenSigTimeoutTime_GNMM" SG_ 262 EngineFrictionTorque_W 0;
BA_ "GenSigTimeoutTime_HCP" SG_ 262 EngineFrictionTorque_W 0;
BA_ "GenSigTimeoutTime_IPC" SG_ 262 EngineFrictionTorque_W 0;
BA_ "GenSigTimeoutTime_RFHM" SG_ 262 EngineFrictionTorque_W 0;
BA_ "GenSigTimeoutTime_SGW" SG_ 262 EngineFrictionTorque_W 0;
BA_ "GenSigTimeoutTime_TCM" SG_ 262 EngineFrictionTorque_W 0;
BA_ "GenSigTimeoutTime_AGSM" SG_ 262 FuelConsumption_GAG_3 0;
BA_ "GenSigTimeoutTime_ASBS" SG_ 262 FuelConsumption_GAG_3 0;
BA_ "GenSigTimeoutTime_BCM" SG_ 262 FuelConsumption_GAG_3 0;
BA_ "GenSigTimeoutTime_BSM" SG_ 262 FuelConsumption_GAG_3 0;
BA_ "GenSigTimeoutTime_CADM" SG_ 262 FuelConsumption_GAG_3 0;
BA_ "GenSigTimeoutTime_DMSM" SG_ 262 FuelConsumption_GAG_3 0;
BA_ "GenSigTimeoutTime_DTCM" SG_ 262 FuelConsumption_GAG_3 0;
BA_ "GenSigTimeoutTime_ECM" SG_ 262 FuelConsumption_GAG_3 0;
BA_ "GenSigTimeoutTime_ELSDM" SG_ 262 FuelConsumption_GAG_3 0;
BA_ "GenSigTimeoutTime_ESL" SG_ 262 FuelConsumption_GAG_3 0;
BA_ "GenSigTimeoutTime_GNMM" SG_ 262 FuelConsumption_GAG_3 0;
BA_ "GenSigTimeoutTime_HCP" SG_ 262 FuelConsumption_GAG_3 0;
BA_ "GenSigTimeoutTime_RFHM" SG_ 262 FuelConsumption_GAG_3 0;
BA_ "GenSigTimeoutTime_TCM" SG_ 262 FuelConsumption_GAG_3 0;
BA_ "GenSigTimeoutTime_AGSM" SG_ 262 FullOFC_Actv 0;
BA_ "GenSigTimeoutTime_ASBS" SG_ 262 FullOFC_Actv 0;
BA_ "GenSigTimeoutTime_BCM" SG_ 262 FullOFC_Actv 0;
BA_ "GenSigTimeoutTime_BSM" SG_ 262 FullOFC_Actv 0;
BA_ "GenSigTimeoutTime_CADM" SG_ 262 FullOFC_Actv 0;
BA_ "GenSigTimeoutTime_DMSM" SG_ 262 FullOFC_Actv 0;
BA_ "GenSigTimeoutTime_DTCM" SG_ 262 FullOFC_Actv 0;
BA_ "GenSigTimeoutTime_ECM" SG_ 262 FullOFC_Actv 0;
BA_ "GenSigTimeoutTime_ELSDM" SG_ 262 FullOFC_Actv 0;
BA_ "GenSigTimeoutTime_ESL" SG_ 262 FullOFC_Actv 0;
BA_ "GenSigTimeoutTime_GNMM" SG_ 262 FullOFC_Actv 0;
BA_ "GenSigTimeoutTime_HCP" SG_ 262 FullOFC_Actv 0;
BA_ "GenSigTimeoutTime_IPC" SG_ 262 FullOFC_Actv 0;
BA_ "GenSigTimeoutTime_RFHM" SG_ 262 FullOFC_Actv 0;
BA_ "GenSigTimeoutTime_SGW" SG_ 262 FullOFC_Actv 0;
BA_ "GenSigTimeoutTime_TCM" SG_ 262 FullOFC_Actv 0;
BA_ "GenSigTimeoutTime_AGSM" SG_ 262 Engine_Stall_Detected 0;
BA_ "GenSigTimeoutTime_ASBS" SG_ 262 Engine_Stall_Detected 0;
BA_ "GenSigTimeoutTime_BCM" SG_ 262 Engine_Stall_Detected 0;
BA_ "GenSigTimeoutTime_BSM" SG_ 262 Engine_Stall_Detected 0;
BA_ "GenSigTimeoutTime_CADM" SG_ 262 Engine_Stall_Detected 0;
BA_ "GenSigTimeoutTime_DMSM" SG_ 262 Engine_Stall_Detected 0;
BA_ "GenSigTimeoutTime_DTCM" SG_ 262 Engine_Stall_Detected 0;
BA_ "GenSigTimeoutTime_ECM" SG_ 262 Engine_Stall_Detected 0;
BA_ "GenSigTimeoutTime_ELSDM" SG_ 262 Engine_Stall_Detected 0;
BA_ "GenSigTimeoutTime_ESL" SG_ 262 Engine_Stall_Detected 0;
BA_ "GenSigTimeoutTime_GNMM" SG_ 262 Engine_Stall_Detected 0;
BA_ "GenSigTimeoutTime_IPC" SG_ 262 Engine_Stall_Detected 0;
BA_ "GenSigTimeoutTime_RFHM" SG_ 262 Engine_Stall_Detected 0;
BA_ "GenSigTimeoutTime_SGW" SG_ 262 Engine_Stall_Detected 0;
BA_ "GenSigTimeoutTime_TCM" SG_ 262 Engine_Stall_Detected 0;
BA_ "GenSigTimeoutTime_AGSM" SG_ 262 ECM_ParkSL_Status 0;
BA_ "GenSigTimeoutTime_ASBS" SG_ 262 ECM_ParkSL_Status 0;
BA_ "GenSigTimeoutTime_BCM" SG_ 262 ECM_ParkSL_Status 0;
BA_ "GenSigTimeoutTime_BSM" SG_ 262 ECM_ParkSL_Status 0;
BA_ "GenSigTimeoutTime_CADM" SG_ 262 ECM_ParkSL_Status 0;
BA_ "GenSigTimeoutTime_DMSM" SG_ 262 ECM_ParkSL_Status 0;
BA_ "GenSigTimeoutTime_DTCM" SG_ 262 ECM_ParkSL_Status 0;
BA_ "GenSigTimeoutTime_ECM" SG_ 262 ECM_ParkSL_Status 0;
BA_ "GenSigTimeoutTime_ELSDM" SG_ 262 ECM_ParkSL_Status 0;
BA_ "GenSigTimeoutTime_ESL" SG_ 262 ECM_ParkSL_Status 0;
BA_ "GenSigTimeoutTime_GNMM" SG_ 262 ECM_ParkSL_Status 0;
BA_ "GenSigTimeoutTime_HCP" SG_ 262 ECM_ParkSL_Status 0;
BA_ "GenSigTimeoutTime_IPC" SG_ 262 ECM_ParkSL_Status 0;
BA_ "GenSigTimeoutTime_RFHM" SG_ 262 ECM_ParkSL_Status 0;
BA_ "GenSigTimeoutTime_SGW" SG_ 262 ECM_ParkSL_Status 0;
BA_ "GenSigStartValue" SG_ 262 AlternatorFail_W 1;
BA_ "GenSigTimeoutTime_AGSM" SG_ 262 AlternatorFail_W 0;
BA_ "GenSigTimeoutTime_ASBS" SG_ 262 AlternatorFail_W 0;
BA_ "GenSigTimeoutTime_BCM" SG_ 262 AlternatorFail_W 0;
BA_ "GenSigTimeoutTime_BSM" SG_ 262 AlternatorFail_W 0;
BA_ "GenSigTimeoutTime_CADM" SG_ 262 AlternatorFail_W 0;
BA_ "GenSigTimeoutTime_DMSM" SG_ 262 AlternatorFail_W 0;
BA_ "GenSigTimeoutTime_DTCM" SG_ 262 AlternatorFail_W 0;
BA_ "GenSigTimeoutTime_ECM" SG_ 262 AlternatorFail_W 0;
BA_ "GenSigTimeoutTime_ELSDM" SG_ 262 AlternatorFail_W 0;
BA_ "GenSigTimeoutTime_ESL" SG_ 262 AlternatorFail_W 0;
BA_ "GenSigTimeoutTime_GNMM" SG_ 262 AlternatorFail_W 0;
BA_ "GenSigTimeoutTime_HCP" SG_ 262 AlternatorFail_W 0;
BA_ "GenSigTimeoutTime_RFHM" SG_ 262 AlternatorFail_W 0;
BA_ "GenSigTimeoutTime_TCM" SG_ 262 AlternatorFail_W 0;
BA_ "GenSigTimeoutTime_AGSM" SG_ 262 CrankHold_W 0;
BA_ "GenSigTimeoutTime_ASBS" SG_ 262 CrankHold_W 0;
BA_ "GenSigTimeoutTime_BSM" SG_ 262 CrankHold_W 0;
BA_ "GenSigTimeoutTime_CADM" SG_ 262 CrankHold_W 0;
BA_ "GenSigTimeoutTime_DMSM" SG_ 262 CrankHold_W 0;
BA_ "GenSigTimeoutTime_DTCM" SG_ 262 CrankHold_W 0;
BA_ "GenSigTimeoutTime_ECM" SG_ 262 CrankHold_W 0;
BA_ "GenSigTimeoutTime_ELSDM" SG_ 262 CrankHold_W 0;
BA_ "GenSigTimeoutTime_ESL" SG_ 262 CrankHold_W 0;
BA_ "GenSigTimeoutTime_GNMM" SG_ 262 CrankHold_W 0;
BA_ "GenSigTimeoutTime_HCP" SG_ 262 CrankHold_W 0;
BA_ "GenSigTimeoutTime_IPC" SG_ 262 CrankHold_W 0;
BA_ "GenSigTimeoutTime_RFHM" SG_ 262 CrankHold_W 0;
BA_ "GenSigTimeoutTime_TCM" SG_ 262 CrankHold_W 0;
BA_ "GenSigTimeoutTime_AGSM" SG_ 262 EngFSO_TCM_Allw 0;
BA_ "GenSigTimeoutTime_ASBS" SG_ 262 EngFSO_TCM_Allw 0;
BA_ "GenSigTimeoutTime_BCM" SG_ 262 EngFSO_TCM_Allw 0;
BA_ "GenSigTimeoutTime_BSM" SG_ 262 EngFSO_TCM_Allw 0;
BA_ "GenSigTimeoutTime_CADM" SG_ 262 EngFSO_TCM_Allw 0;
BA_ "GenSigTimeoutTime_DMSM" SG_ 262 EngFSO_TCM_Allw 0;
BA_ "GenSigTimeoutTime_DTCM" SG_ 262 EngFSO_TCM_Allw 0;
BA_ "GenSigTimeoutTime_ECM" SG_ 262 EngFSO_TCM_Allw 0;
BA_ "GenSigTimeoutTime_ELSDM" SG_ 262 EngFSO_TCM_Allw 0;
BA_ "GenSigTimeoutTime_ESL" SG_ 262 EngFSO_TCM_Allw 0;
BA_ "GenSigTimeoutTime_GNMM" SG_ 262 EngFSO_TCM_Allw 0;
BA_ "GenSigTimeoutTime_HCP" SG_ 262 EngFSO_TCM_Allw 0;
BA_ "GenSigTimeoutTime_IPC" SG_ 262 EngFSO_TCM_Allw 0;
BA_ "GenSigTimeoutTime_RFHM" SG_ 262 EngFSO_TCM_Allw 0;
BA_ "GenSigTimeoutTime_SGW" SG_ 262 EngFSO_TCM_Allw 0;
BA_ "GenSigTimeoutTime_AGSM" SG_ 262 StartRelayBCMCmd_W 0;
BA_ "GenSigTimeoutTime_ASBS" SG_ 262 StartRelayBCMCmd_W 0;
BA_ "GenSigTimeoutTime_BSM" SG_ 262 StartRelayBCMCmd_W 0;
BA_ "GenSigTimeoutTime_CADM" SG_ 262 StartRelayBCMCmd_W 0;
BA_ "GenSigTimeoutTime_DMSM" SG_ 262 StartRelayBCMCmd_W 0;
BA_ "GenSigTimeoutTime_DTCM" SG_ 262 StartRelayBCMCmd_W 0;
BA_ "GenSigTimeoutTime_ECM" SG_ 262 StartRelayBCMCmd_W 0;
BA_ "GenSigTimeoutTime_ELSDM" SG_ 262 StartRelayBCMCmd_W 0;
BA_ "GenSigTimeoutTime_ESL" SG_ 262 StartRelayBCMCmd_W 0;
BA_ "GenSigTimeoutTime_GNMM" SG_ 262 StartRelayBCMCmd_W 0;
BA_ "GenSigTimeoutTime_HCP" SG_ 262 StartRelayBCMCmd_W 0;
BA_ "GenSigTimeoutTime_IPC" SG_ 262 StartRelayBCMCmd_W 0;
BA_ "GenSigTimeoutTime_RFHM" SG_ 262 StartRelayBCMCmd_W 0;
BA_ "GenSigTimeoutTime_SGW" SG_ 262 StartRelayBCMCmd_W 0;
BA_ "GenSigTimeoutTime_TCM" SG_ 262 StartRelayBCMCmd_W 0;
BA_ "GenSigTimeoutTime_AGSM" SG_ 262 TRANS_CLU_SLIP_MODE_W 0;
BA_ "GenSigTimeoutTime_ASBS" SG_ 262 TRANS_CLU_SLIP_MODE_W 0;
BA_ "GenSigTimeoutTime_BCM" SG_ 262 TRANS_CLU_SLIP_MODE_W 0;
BA_ "GenSigTimeoutTime_BSM" SG_ 262 TRANS_CLU_SLIP_MODE_W 0;
BA_ "GenSigTimeoutTime_CADM" SG_ 262 TRANS_CLU_SLIP_MODE_W 0;
BA_ "GenSigTimeoutTime_DMSM" SG_ 262 TRANS_CLU_SLIP_MODE_W 0;
BA_ "GenSigTimeoutTime_DTCM" SG_ 262 TRANS_CLU_SLIP_MODE_W 0;
BA_ "GenSigTimeoutTime_ECM" SG_ 262 TRANS_CLU_SLIP_MODE_W 0;
BA_ "GenSigTimeoutTime_ELSDM" SG_ 262 TRANS_CLU_SLIP_MODE_W 0;
BA_ "GenSigTimeoutTime_ESL" SG_ 262 TRANS_CLU_SLIP_MODE_W 0;
BA_ "GenSigTimeoutTime_GNMM" SG_ 262 TRANS_CLU_SLIP_MODE_W 0;
BA_ "GenSigTimeoutTime_HCP" SG_ 262 TRANS_CLU_SLIP_MODE_W 0;
BA_ "GenSigTimeoutTime_IPC" SG_ 262 TRANS_CLU_SLIP_MODE_W 0;
BA_ "GenSigTimeoutTime_RFHM" SG_ 262 TRANS_CLU_SLIP_MODE_W 0;
BA_ "GenSigTimeoutTime_SGW" SG_ 262 TRANS_CLU_SLIP_MODE_W 0;
BA_ "GenSigTimeoutTime_TCM" SG_ 262 TRANS_CLU_SLIP_MODE_W 0;
BA_ "GenSigTimeoutTime_AGSM" SG_ 262 TxAC_EMCC_rq_W 0;
BA_ "GenSigTimeoutTime_ASBS" SG_ 262 TxAC_EMCC_rq_W 0;
BA_ "GenSigTimeoutTime_BCM" SG_ 262 TxAC_EMCC_rq_W 0;
BA_ "GenSigTimeoutTime_BSM" SG_ 262 TxAC_EMCC_rq_W 0;
BA_ "GenSigTimeoutTime_CADM" SG_ 262 TxAC_EMCC_rq_W 0;
BA_ "GenSigTimeoutTime_DMSM" SG_ 262 TxAC_EMCC_rq_W 0;
BA_ "GenSigTimeoutTime_DTCM" SG_ 262 TxAC_EMCC_rq_W 0;
BA_ "GenSigTimeoutTime_ECM" SG_ 262 TxAC_EMCC_rq_W 0;
BA_ "GenSigTimeoutTime_ELSDM" SG_ 262 TxAC_EMCC_rq_W 0;
BA_ "GenSigTimeoutTime_ESL" SG_ 262 TxAC_EMCC_rq_W 0;
BA_ "GenSigTimeoutTime_GNMM" SG_ 262 TxAC_EMCC_rq_W 0;
BA_ "GenSigTimeoutTime_HCP" SG_ 262 TxAC_EMCC_rq_W 0;
BA_ "GenSigTimeoutTime_IPC" SG_ 262 TxAC_EMCC_rq_W 0;
BA_ "GenSigTimeoutTime_RFHM" SG_ 262 TxAC_EMCC_rq_W 0;
BA_ "GenSigTimeoutTime_SGW" SG_ 262 TxAC_EMCC_rq_W 0;
BA_ "GenSigTimeoutTime_TCM" SG_ 262 TxAC_EMCC_rq_W 0;
BA_ "GenSigTimeoutTime_AGSM" SG_ 262 ESS_EBOOST_BRKHLD_STATUS 0;
BA_ "GenSigTimeoutTime_ASBS" SG_ 262 ESS_EBOOST_BRKHLD_STATUS 0;
BA_ "GenSigTimeoutTime_BCM" SG_ 262 ESS_EBOOST_BRKHLD_STATUS 0;
BA_ "GenSigTimeoutTime_CADM" SG_ 262 ESS_EBOOST_BRKHLD_STATUS 0;
BA_ "GenSigTimeoutTime_DMSM" SG_ 262 ESS_EBOOST_BRKHLD_STATUS 0;
BA_ "GenSigTimeoutTime_DTCM" SG_ 262 ESS_EBOOST_BRKHLD_STATUS 0;
BA_ "GenSigTimeoutTime_ECM" SG_ 262 ESS_EBOOST_BRKHLD_STATUS 0;
BA_ "GenSigTimeoutTime_ELSDM" SG_ 262 ESS_EBOOST_BRKHLD_STATUS 0;
BA_ "GenSigTimeoutTime_ESL" SG_ 262 ESS_EBOOST_BRKHLD_STATUS 0;
BA_ "GenSigTimeoutTime_GNMM" SG_ 262 ESS_EBOOST_BRKHLD_STATUS 0;
BA_ "GenSigTimeoutTime_HCP" SG_ 262 ESS_EBOOST_BRKHLD_STATUS 0;
BA_ "GenSigTimeoutTime_IPC" SG_ 262 ESS_EBOOST_BRKHLD_STATUS 0;
BA_ "GenSigTimeoutTime_RFHM" SG_ 262 ESS_EBOOST_BRKHLD_STATUS 0;
BA_ "GenSigTimeoutTime_SGW" SG_ 262 ESS_EBOOST_BRKHLD_STATUS 0;
BA_ "GenSigTimeoutTime_TCM" SG_ 262 ESS_EBOOST_BRKHLD_STATUS 0;
BA_ "GenSigStartValue" SG_ 262 EngTrqTgt_SEM 6691;
BA_ "GenSigTimeoutTime_AGSM" SG_ 262 EngTrqTgt_SEM 0;
BA_ "GenSigTimeoutTime_ASBS" SG_ 262 EngTrqTgt_SEM 0;
BA_ "GenSigTimeoutTime_BCM" SG_ 262 EngTrqTgt_SEM 0;
BA_ "GenSigTimeoutTime_BSM" SG_ 262 EngTrqTgt_SEM 0;
BA_ "GenSigTimeoutTime_CADM" SG_ 262 EngTrqTgt_SEM 0;
BA_ "GenSigTimeoutTime_DMSM" SG_ 262 EngTrqTgt_SEM 0;
BA_ "GenSigTimeoutTime_DTCM" SG_ 262 EngTrqTgt_SEM 0;
BA_ "GenSigTimeoutTime_ECM" SG_ 262 EngTrqTgt_SEM 0;
BA_ "GenSigTimeoutTime_ELSDM" SG_ 262 EngTrqTgt_SEM 0;
BA_ "GenSigTimeoutTime_ESL" SG_ 262 EngTrqTgt_SEM 0;
BA_ "GenSigTimeoutTime_GNMM" SG_ 262 EngTrqTgt_SEM 0;
BA_ "GenSigTimeoutTime_IPC" SG_ 262 EngTrqTgt_SEM 0;
BA_ "GenSigTimeoutTime_RFHM" SG_ 262 EngTrqTgt_SEM 0;
BA_ "GenSigTimeoutTime_SGW" SG_ 262 EngTrqTgt_SEM 0;
BA_ "GenSigTimeoutTime_TCM" SG_ 262 EngTrqTgt_SEM 0;
BA_ "GenSigTimeoutTime_RFHM" SG_ 205 TotalAxle_Rq_BSM 0;
BA_ "GenSigTimeoutTime_SGW" SG_ 205 TotalAxle_Rq_BSM 0;
BA_ "GenSigTimeoutTime_AGSM" SG_ 205 DriverReq_AxleTrq_Enabled_BSM 0;
BA_ "GenSigTimeoutTime_ASBS" SG_ 205 DriverReq_AxleTrq_Enabled_BSM 0;
BA_ "GenSigTimeoutTime_BCM" SG_ 205 DriverReq_AxleTrq_Enabled_BSM 0;
BA_ "GenSigTimeoutTime_BSM" SG_ 205 DriverReq_AxleTrq_Enabled_BSM 0;
BA_ "GenSigTimeoutTime_CADM" SG_ 205 DriverReq_AxleTrq_Enabled_BSM 0;
BA_ "GenSigTimeoutTime_DMSM" SG_ 205 DriverReq_AxleTrq_Enabled_BSM 0;
BA_ "GenSigTimeoutTime_DTCM" SG_ 205 DriverReq_AxleTrq_Enabled_BSM 0;
BA_ "GenSigTimeoutTime_ELSDM" SG_ 205 DriverReq_AxleTrq_Enabled_BSM 0;
BA_ "GenSigTimeoutTime_ESL" SG_ 205 DriverReq_AxleTrq_Enabled_BSM 0;
BA_ "GenSigTimeoutTime_GNMM" SG_ 205 DriverReq_AxleTrq_Enabled_BSM 0;
BA_ "GenSigTimeoutTime_HCP" SG_ 205 DriverReq_AxleTrq_Enabled_BSM 0;
BA_ "GenSigTimeoutTime_IPC" SG_ 205 DriverReq_AxleTrq_Enabled_BSM 0;
BA_ "GenSigTimeoutTime_RFHM" SG_ 205 DriverReq_AxleTrq_Enabled_BSM 0;
BA_ "GenSigTimeoutTime_SGW" SG_ 205 DriverReq_AxleTrq_Enabled_BSM 0;
BA_ "GenSigTimeoutTime_TCM" SG_ 205 DriverReq_AxleTrq_Enabled_BSM 0;
BA_ "GenSigTimeoutTime_AGSM" SG_ 205 TotalAxle_Max_Rq_BSM 0;
BA_ "GenSigTimeoutTime_ASBS" SG_ 205 TotalAxle_Max_Rq_BSM 0;
BA_ "GenSigTimeoutTime_BCM" SG_ 205 TotalAxle_Max_Rq_BSM 0;
BA_ "GenSigTimeoutTime_BSM" SG_ 205 TotalAxle_Max_Rq_BSM 0;
BA_ "GenSigTimeoutTime_CADM" SG_ 205 TotalAxle_Max_Rq_BSM 0;
BA_ "GenSigTimeoutTime_DMSM" SG_ 205 TotalAxle_Max_Rq_BSM 0;
BA_ "GenSigTimeoutTime_ELSDM" SG_ 205 TotalAxle_Max_Rq_BSM 0;
BA_ "GenSigTimeoutTime_ESL" SG_ 205 TotalAxle_Max_Rq_BSM 0;
BA_ "GenSigTimeoutTime_GNMM" SG_ 205 TotalAxle_Max_Rq_BSM 0;
BA_ "GenSigTimeoutTime_HCP" SG_ 205 TotalAxle_Max_Rq_BSM 0;
BA_ "GenSigTimeoutTime_IPC" SG_ 205 TotalAxle_Max_Rq_BSM 0;
BA_ "GenSigTimeoutTime_RFHM" SG_ 205 TotalAxle_Max_Rq_BSM 0;
BA_ "GenSigTimeoutTime_SGW" SG_ 205 TotalAxle_Max_Rq_BSM 0;
BA_ "GenSigTimeoutTime_AGSM" SG_ 205 TotalAxle_Min_Rq_BSM 0;
BA_ "GenSigTimeoutTime_ASBS" SG_ 205 TotalAxle_Min_Rq_BSM 0;
BA_ "GenSigTimeoutTime_BCM" SG_ 205 TotalAxle_Min_Rq_BSM 0;
BA_ "GenSigTimeoutTime_BSM" SG_ 205 TotalAxle_Min_Rq_BSM 0;
BA_ "GenSigTimeoutTime_CADM" SG_ 205 TotalAxle_Min_Rq_BSM 0;
BA_ "GenSigTimeoutTime_DMSM" SG_ 205 TotalAxle_Min_Rq_BSM 0;
BA_ "GenSigTimeoutTime_DTCM" SG_ 205 TotalAxle_Min_Rq_BSM 0;
BA_ "GenSigTimeoutTime_ELSDM" SG_ 205 TotalAxle_Min_Rq_BSM 0;
BA_ "GenSigTimeoutTime_ESL" SG_ 205 TotalAxle_Min_Rq_BSM 0;
BA_ "GenSigTimeoutTime_GNMM" SG_ 205 TotalAxle_Min_Rq_BSM 0;
BA_ "GenSigTimeoutTime_HCP" SG_ 205 TotalAxle_Min_Rq_BSM 0;
BA_ "GenSigTimeoutTime_IPC" SG_ 205 TotalAxle_Min_Rq_BSM 0;
BA_ "GenSigTimeoutTime_RFHM" SG_ 205 TotalAxle_Min_Rq_BSM 0;
BA_ "GenSigTimeoutTime_SGW" SG_ 205 TotalAxle_Min_Rq_BSM 0;
BA_ "GenSigTimeoutTime_ADCAM" SG_ 2564554485 N_PDU_18DBFEF5 0;
BA_ "GenSigTimeoutTime_EVCU2" SG_ 2564554485 N_PDU_18DBFEF5 0;
BA_ "GenSigTimeoutTime_VDCM" SG_ 2564554485 N_PDU_18DBFEF5 0;
BA_ "GenSigTimeoutTime_AGSM" SG_ 2564554485 N_PDU_18DBFEF5 0;
BA_ "GenSigTimeoutTime_ASBS" SG_ 2564554485 N_PDU_18DBFEF5 0;
BA_ "GenSigTimeoutTime_BCM" SG_ 2564554485 N_PDU_18DBFEF5 0;
BA_ "GenSigTimeoutTime_BSM" SG_ 2564554485 N_PDU_18DBFEF5 0;
BA_ "GenSigTimeoutTime_CADM" SG_ 2564554485 N_PDU_18DBFEF5 0;
BA_ "GenSigTimeoutTime_DMSM" SG_ 2564554485 N_PDU_18DBFEF5 0;
BA_ "GenSigTimeoutTime_DTCM" SG_ 2564554485 N_PDU_18DBFEF5 0;
BA_ "GenSigTimeoutTime_ECM" SG_ 2564554485 N_PDU_18DBFEF5 0;
BA_ "GenSigTimeoutTime_ELSDM" SG_ 2564554485 N_PDU_18DBFEF5 0;
BA_ "GenSigTimeoutTime_ESL" SG_ 2564554485 N_PDU_18DBFEF5 0;
BA_ "GenSigTimeoutTime_GNMM" SG_ 2564554485 N_PDU_18DBFEF5 0;
BA_ "GenSigTimeoutTime_HCP" SG_ 2564554485 N_PDU_18DBFEF5 0;
BA_ "GenSigTimeoutTime_IPC" SG_ 2564554485 N_PDU_18DBFEF5 0;
BA_ "GenSigTimeoutTime_RFHM" SG_ 2564554485 N_PDU_18DBFEF5 0;
BA_ "GenSigTimeoutTime_SGW" SG_ 2564554485 N_PDU_18DBFEF5 0;
BA_ "GenSigTimeoutTime_TCM" SG_ 2564554485 N_PDU_18DBFEF5 0;
BA_ "GenSigTimeoutTime_ADCAM" SG_ 280 CRC_ADAS_FD_INFO 0;
BA_ "GenSigTimeoutTime_EVCU2" SG_ 280 CRC_ADAS_FD_INFO 0;
BA_ "GenSigTimeoutTime_VDCM" SG_ 280 CRC_ADAS_FD_INFO 0;
BA_ "GenSigTimeoutTime_AGSM" SG_ 280 CRC_ADAS_FD_INFO 0;
BA_ "GenSigTimeoutTime_ESL" SG_ 280 CRC_ADAS_FD_INFO 0;
BA_ "GenSigTimeoutTime_RFHM" SG_ 280 CRC_ADAS_FD_INFO 0;
BA_ "GenSigTimeoutTime_SGW" SG_ 280 CRC_ADAS_FD_INFO 0;
BA_ "GenSigTimeoutTime_ADCAM" SG_ 280 ACC_Systemsts 0;
BA_ "GenSigTimeoutTime_VDCM" SG_ 280 ACC_Systemsts 0;
BA_ "GenSigTimeoutTime_AGSM" SG_ 280 ACC_Systemsts 0;
BA_ "GenSigTimeoutTime_BCM" SG_ 280 ACC_Systemsts 0;
BA_ "GenSigTimeoutTime_DTCM" SG_ 280 ACC_Systemsts 0;
BA_ "GenSigTimeoutTime_ESL" SG_ 280 ACC_Systemsts 0;
BA_ "GenSigTimeoutTime_IPC" SG_ 280 ACC_Systemsts 0;
BA_ "GenSigTimeoutTime_RFHM" SG_ 280 ACC_Systemsts 0;
BA_ "GenSigTimeoutTime_SGW" SG_ 280 ACC_Systemsts 0;
BA_ "GenSigTimeoutTime_ADCAM" SG_ 280 MessageCounter_ADAS_FD_INFO 0;
BA_ "GenSigTimeoutTime_EVCU2" SG_ 280 MessageCounter_ADAS_FD_INFO 0;
BA_ "GenSigTimeoutTime_VDCM" SG_ 280 MessageCounter_ADAS_FD_INFO 0;
BA_ "GenSigTimeoutTime_AGSM" SG_ 280 MessageCounter_ADAS_FD_INFO 0;
BA_ "GenSigTimeoutTime_ESL" SG_ 280 MessageCounter_ADAS_FD_INFO 0;
BA_ "GenSigTimeoutTime_RFHM" SG_ 280 MessageCounter_ADAS_FD_INFO 0;
BA_ "GenSigTimeoutTime_SGW" SG_ 280 MessageCounter_ADAS_FD_INFO 0;
BA_ "GenSigTimeoutTime_ADCAM" SG_ 280 AEB_Systemsts 0;
BA_ "GenSigTimeoutTime_VDCM" SG_ 280 AEB_Systemsts 0;
BA_ "GenSigTimeoutTime_AGSM" SG_ 280 AEB_Systemsts 0;
BA_ "GenSigTimeoutTime_BCM" SG_ 280 AEB_Systemsts 0;
BA_ "GenSigTimeoutTime_BSM" SG_ 280 AEB_Systemsts 0;
BA_ "GenSigTimeoutTime_DTCM" SG_ 280 AEB_Systemsts 0;
BA_ "GenSigTimeoutTime_ESL" SG_ 280 AEB_Systemsts 0;
BA_ "GenSigTimeoutTime_RFHM" SG_ 280 AEB_Systemsts 0;
BA_ "GenSigTimeoutTime_SGW" SG_ 280 AEB_Systemsts 0;
BA_ "GenSigTimeoutTime_TCM" SG_ 280 AEB_Systemsts 0;
BA_ "GenSigTimeoutTime_ADCAM" SG_ 280 ACC_StopStart 0;
BA_ "GenSigTimeoutTime_EVCU2" SG_ 280 ACC_StopStart 0;
BA_ "GenSigTimeoutTime_VDCM" SG_ 280 ACC_StopStart 0;
BA_ "GenSigTimeoutTime_AGSM" SG_ 280 ACC_StopStart 0;
BA_ "GenSigTimeoutTime_ASBS" SG_ 280 ACC_StopStart 0;
BA_ "GenSigTimeoutTime_BCM" SG_ 280 ACC_StopStart 0;
BA_ "GenSigTimeoutTime_BSM" SG_ 280 ACC_StopStart 0;
BA_ "GenSigTimeoutTime_CADM" SG_ 280 ACC_StopStart 0;
BA_ "GenSigTimeoutTime_DMSM" SG_ 280 ACC_StopStart 0;
BA_ "GenSigTimeoutTime_DTCM" SG_ 280 ACC_StopStart 0;
BA_ "GenSigTimeoutTime_ELSDM" SG_ 280 ACC_StopStart 0;
BA_ "GenSigTimeoutTime_ESL" SG_ 280 ACC_StopStart 0;
BA_ "GenSigTimeoutTime_GNMM" SG_ 280 ACC_StopStart 0;
BA_ "GenSigTimeoutTime_HCP" SG_ 280 ACC_StopStart 0;
BA_ "GenSigTimeoutTime_IPC" SG_ 280 ACC_StopStart 0;
BA_ "GenSigTimeoutTime_RFHM" SG_ 280 ACC_StopStart 0;
BA_ "GenSigTimeoutTime_SGW" SG_ 280 ACC_StopStart 0;
BA_ "GenSigTimeoutTime_TCM" SG_ 280 ACC_StopStart 0;
BA_ "GenSigTimeoutTime_AGSM" SG_ 280 MRM_STATUS 0;
BA_ "GenSigTimeoutTime_ASBS" SG_ 280 MRM_STATUS 0;
BA_ "GenSigTimeoutTime_CADM" SG_ 280 MRM_STATUS 0;
BA_ "GenSigTimeoutTime_DMSM" SG_ 280 MRM_STATUS 0;
BA_ "GenSigTimeoutTime_DTCM" SG_ 280 MRM_STATUS 0;
BA_ "GenSigTimeoutTime_ELSDM" SG_ 280 MRM_STATUS 0;
BA_ "GenSigTimeoutTime_ESL" SG_ 280 MRM_STATUS 0;
BA_ "GenSigTimeoutTime_GNMM" SG_ 280 MRM_STATUS 0;
BA_ "GenSigTimeoutTime_HCP" SG_ 280 MRM_STATUS 0;
BA_ "GenSigTimeoutTime_RFHM" SG_ 280 MRM_STATUS 0;
BA_ "GenSigTimeoutTime_ADCAM" SG_ 2564428021 N_PDU_18DA10F5 0;
BA_ "GenSigTimeoutTime_EVCU2" SG_ 2564428021 N_PDU_18DA10F5 0;
BA_ "GenSigTimeoutTime_VDCM" SG_ 2564428021 N_PDU_18DA10F5 0;
BA_ "GenSigTimeoutTime_AGSM" SG_ 2564428021 N_PDU_18DA10F5 0;
BA_ "GenSigTimeoutTime_ASBS" SG_ 2564428021 N_PDU_18DA10F5 0;
BA_ "GenSigTimeoutTime_BCM" SG_ 2564428021 N_PDU_18DA10F5 0;
BA_ "GenSigTimeoutTime_BSM" SG_ 2564428021 N_PDU_18DA10F5 0;
BA_ "GenSigTimeoutTime_CADM" SG_ 2564428021 N_PDU_18DA10F5 0;
BA_ "GenSigTimeoutTime_DMSM" SG_ 2564428021 N_PDU_18DA10F5 0;
BA_ "GenSigTimeoutTime_DTCM" SG_ 2564428021 N_PDU_18DA10F5 0;
BA_ "GenSigTimeoutTime_ECM" SG_ 2564428021 N_PDU_18DA10F5 0;
BA_ "GenSigTimeoutTime_ELSDM" SG_ 2564428021 N_PDU_18DA10F5 0;
BA_ "GenSigTimeoutTime_ESL" SG_ 2564428021 N_PDU_18DA10F5 0;
BA_ "GenSigTimeoutTime_GNMM" SG_ 2564428021 N_PDU_18DA10F5 0;
BA_ "GenSigTimeoutTime_HCP" SG_ 2564428021 N_PDU_18DA10F5 0;
BA_ "GenSigTimeoutTime_IPC" SG_ 2564428021 N_PDU_18DA10F5 0;
BA_ "GenSigTimeoutTime_RFHM" SG_ 2564428021 N_PDU_18DA10F5 0;
BA_ "GenSigTimeoutTime_SGW" SG_ 2564428021 N_PDU_18DA10F5 0;
BA_ "GenSigTimeoutTime_TCM" SG_ 2564428021 N_PDU_18DA10F5 0;
BA_ "GenSigSendType" SG_ 99 IMMO_SOP_REQUEST 1;
BA_ "GenSigTimeoutTime_AGSM" SG_ 99 IMMO_SOP_REQUEST 0;
BA_ "GenSigTimeoutTime_ASBS" SG_ 99 IMMO_SOP_REQUEST 0;
BA_ "GenSigTimeoutTime_BCM" SG_ 99 IMMO_SOP_REQUEST 0;
BA_ "GenSigTimeoutTime_BSM" SG_ 99 IMMO_SOP_REQUEST 0;
BA_ "GenSigTimeoutTime_CADM" SG_ 99 IMMO_SOP_REQUEST 0;
BA_ "GenSigTimeoutTime_DMSM" SG_ 99 IMMO_SOP_REQUEST 0;
BA_ "GenSigTimeoutTime_DTCM" SG_ 99 IMMO_SOP_REQUEST 0;
BA_ "GenSigTimeoutTime_ELSDM" SG_ 99 IMMO_SOP_REQUEST 0;
BA_ "GenSigTimeoutTime_ESL" SG_ 99 IMMO_SOP_REQUEST 0;
BA_ "GenSigTimeoutTime_GNMM" SG_ 99 IMMO_SOP_REQUEST 0;
BA_ "GenSigTimeoutTime_HCP" SG_ 99 IMMO_SOP_REQUEST 0;
BA_ "GenSigTimeoutTime_IPC" SG_ 99 IMMO_SOP_REQUEST 0;
BA_ "GenSigTimeoutTime_RFHM" SG_ 99 IMMO_SOP_REQUEST 0;
BA_ "GenSigTimeoutTime_SGW" SG_ 99 IMMO_SOP_REQUEST 0;
BA_ "GenSigTimeoutTime_TCM" SG_ 99 IMMO_SOP_REQUEST 0;
BA_ "GenSigTimeoutTime_EVCU2" SG_ 1460 FOTA_Status 0;
BA_ "GenSigTimeoutTime_VDCM" SG_ 1460 FOTA_Status 0;
BA_ "GenSigTimeoutTime_TCM" SG_ 1460 FOTA_Status 0;
BA_ "GenSigSendType" SG_ 1460 FOTA_Install_Type 3;
BA_ "GenSigTimeoutTime_AGSM" SG_ 1460 FOTA_Install_Type 0;
BA_ "GenSigTimeoutTime_ASBS" SG_ 1460 FOTA_Install_Type 0;
BA_ "GenSigTimeoutTime_BCM" SG_ 1460 FOTA_Install_Type 0;
BA_ "GenSigTimeoutTime_BSM" SG_ 1460 FOTA_Install_Type 0;
BA_ "GenSigTimeoutTime_CADM" SG_ 1460 FOTA_Install_Type 0;
BA_ "GenSigTimeoutTime_DMSM" SG_ 1460 FOTA_Install_Type 0;
BA_ "GenSigTimeoutTime_DTCM" SG_ 1460 FOTA_Install_Type 0;
BA_ "GenSigTimeoutTime_ELSDM" SG_ 1460 FOTA_Install_Type 0;
BA_ "GenSigTimeoutTime_ESL" SG_ 1460 FOTA_Install_Type 0;
BA_ "GenSigTimeoutTime_GNMM" SG_ 1460 FOTA_Install_Type 0;
BA_ "GenSigTimeoutTime_IPC" SG_ 1460 FOTA_Install_Type 0;
BA_ "GenSigTimeoutTime_RFHM" SG_ 1460 FOTA_Install_Type 0;
BA_ "GenSigTimeoutTime_SGW" SG_ 1460 FOTA_Install_Type 0;
BA_ "GenSigTimeoutTime_TCM" SG_ 1460 FOTA_Install_Type 0;
BA_ "GenSigSendType" SG_ 1460 FOTA_Status 3;
BA_ "GenSigTimeoutTime_AGSM" SG_ 1460 FOTA_Status 0;
BA_ "GenSigTimeoutTime_ASBS" SG_ 1460 FOTA_Status 0;
BA_ "GenSigTimeoutTime_DMSM" SG_ 1460 FOTA_Status 0;
BA_ "GenSigTimeoutTime_DTCM" SG_ 1460 FOTA_Status 0;
BA_ "GenSigTimeoutTime_ELSDM" SG_ 1460 FOTA_Status 0;
BA_ "GenSigTimeoutTime_ESL" SG_ 1460 FOTA_Status 0;
BA_ "GenSigTimeoutTime_GNMM" SG_ 1460 FOTA_Status 0;
BA_ "GenSigTimeoutTime_HCP" SG_ 1460 FOTA_Status 0;
BA_ "GenSigTimeoutTime_RFHM" SG_ 1460 FOTA_Status 0;
BA_ "GenSigTimeoutTime_SGW" SG_ 1460 FOTA_Status 0;
BA_ "GenSigTimeoutTime_AGSM" SG_ 2654486672 CBV_bit0_RepeatMessageRequestBit_1E384090 0;
BA_ "GenSigTimeoutTime_ASBS" SG_ 2654486672 CBV_bit0_RepeatMessageRequestBit_1E384090 0;
BA_ "GenSigTimeoutTime_BCM" SG_ 2654486672 CBV_bit0_RepeatMessageRequestBit_1E384090 0;
BA_ "GenSigTimeoutTime_BSM" SG_ 2654486672 CBV_bit0_RepeatMessageRequestBit_1E384090 0;
BA_ "GenSigTimeoutTime_CADM" SG_ 2654486672 CBV_bit0_RepeatMessageRequestBit_1E384090 0;
BA_ "GenSigTimeoutTime_DMSM" SG_ 2654486672 CBV_bit0_RepeatMessageRequestBit_1E384090 0;
BA_ "GenSigTimeoutTime_DTCM" SG_ 2654486672 CBV_bit0_RepeatMessageRequestBit_1E384090 0;
BA_ "GenSigTimeoutTime_ECM" SG_ 2654486672 CBV_bit0_RepeatMessageRequestBit_1E384090 0;
BA_ "GenSigTimeoutTime_ELSDM" SG_ 2654486672 CBV_bit0_RepeatMessageRequestBit_1E384090 0;
BA_ "GenSigTimeoutTime_ESL" SG_ 2654486672 CBV_bit0_RepeatMessageRequestBit_1E384090 0;
BA_ "GenSigTimeoutTime_GNMM" SG_ 2654486672 CBV_bit0_RepeatMessageRequestBit_1E384090 0;
BA_ "GenSigTimeoutTime_HCP" SG_ 2654486672 CBV_bit0_RepeatMessageRequestBit_1E384090 0;
BA_ "GenSigTimeoutTime_IPC" SG_ 2654486672 CBV_bit0_RepeatMessageRequestBit_1E384090 0;
BA_ "GenSigTimeoutTime_RFHM" SG_ 2654486672 CBV_bit0_RepeatMessageRequestBit_1E384090 0;
BA_ "GenSigTimeoutTime_SGW" SG_ 2654486672 CBV_bit0_RepeatMessageRequestBit_1E384090 0;
BA_ "GenSigTimeoutTime_TCM" SG_ 2654486672 CBV_bit0_RepeatMessageRequestBit_1E384090 0;
BA_ "GenSigTimeoutTime_AGSM" SG_ 2654486672 CBV_bit1_1E384090 0;
BA_ "GenSigTimeoutTime_ASBS" SG_ 2654486672 CBV_bit1_1E384090 0;
BA_ "GenSigTimeoutTime_BCM" SG_ 2654486672 CBV_bit1_1E384090 0;
BA_ "GenSigTimeoutTime_BSM" SG_ 2654486672 CBV_bit1_1E384090 0;
BA_ "GenSigTimeoutTime_CADM" SG_ 2654486672 CBV_bit1_1E384090 0;
BA_ "GenSigTimeoutTime_DMSM" SG_ 2654486672 CBV_bit1_1E384090 0;
BA_ "GenSigTimeoutTime_DTCM" SG_ 2654486672 CBV_bit1_1E384090 0;
BA_ "GenSigTimeoutTime_ECM" SG_ 2654486672 CBV_bit1_1E384090 0;
BA_ "GenSigTimeoutTime_ELSDM" SG_ 2654486672 CBV_bit1_1E384090 0;
BA_ "GenSigTimeoutTime_ESL" SG_ 2654486672 CBV_bit1_1E384090 0;
BA_ "GenSigTimeoutTime_GNMM" SG_ 2654486672 CBV_bit1_1E384090 0;
BA_ "GenSigTimeoutTime_HCP" SG_ 2654486672 CBV_bit1_1E384090 0;
BA_ "GenSigTimeoutTime_IPC" SG_ 2654486672 CBV_bit1_1E384090 0;
BA_ "GenSigTimeoutTime_RFHM" SG_ 2654486672 CBV_bit1_1E384090 0;
BA_ "GenSigTimeoutTime_SGW" SG_ 2654486672 CBV_bit1_1E384090 0;
BA_ "GenSigTimeoutTime_TCM" SG_ 2654486672 CBV_bit1_1E384090 0;
BA_ "GenSigTimeoutTime_AGSM" SG_ 2654486672 CBV_bit2_1E384090 0;
BA_ "GenSigTimeoutTime_ASBS" SG_ 2654486672 CBV_bit2_1E384090 0;
BA_ "GenSigTimeoutTime_BCM" SG_ 2654486672 CBV_bit2_1E384090 0;
BA_ "GenSigTimeoutTime_BSM" SG_ 2654486672 CBV_bit2_1E384090 0;
BA_ "GenSigTimeoutTime_CADM" SG_ 2654486672 CBV_bit2_1E384090 0;
BA_ "GenSigTimeoutTime_DMSM" SG_ 2654486672 CBV_bit2_1E384090 0;
BA_ "GenSigTimeoutTime_DTCM" SG_ 2654486672 CBV_bit2_1E384090 0;
BA_ "GenSigTimeoutTime_ECM" SG_ 2654486672 CBV_bit2_1E384090 0;
BA_ "GenSigTimeoutTime_ELSDM" SG_ 2654486672 CBV_bit2_1E384090 0;
BA_ "GenSigTimeoutTime_ESL" SG_ 2654486672 CBV_bit2_1E384090 0;
BA_ "GenSigTimeoutTime_GNMM" SG_ 2654486672 CBV_bit2_1E384090 0;
BA_ "GenSigTimeoutTime_HCP" SG_ 2654486672 CBV_bit2_1E384090 0;
BA_ "GenSigTimeoutTime_IPC" SG_ 2654486672 CBV_bit2_1E384090 0;
BA_ "GenSigTimeoutTime_RFHM" SG_ 2654486672 CBV_bit2_1E384090 0;
BA_ "GenSigTimeoutTime_SGW" SG_ 2654486672 CBV_bit2_1E384090 0;
BA_ "GenSigTimeoutTime_TCM" SG_ 2654486672 CBV_bit2_1E384090 0;
BA_ "GenSigTimeoutTime_AGSM" SG_ 2654486672 CBV_bit3_NMCoordinatorBit_1E384090 0;
BA_ "GenSigTimeoutTime_ASBS" SG_ 2654486672 CBV_bit3_NMCoordinatorBit_1E384090 0;
BA_ "GenSigTimeoutTime_BCM" SG_ 2654486672 CBV_bit3_NMCoordinatorBit_1E384090 0;
BA_ "GenSigTimeoutTime_BSM" SG_ 2654486672 CBV_bit3_NMCoordinatorBit_1E384090 0;
BA_ "GenSigTimeoutTime_CADM" SG_ 2654486672 CBV_bit3_NMCoordinatorBit_1E384090 0;
BA_ "GenSigTimeoutTime_DMSM" SG_ 2654486672 CBV_bit3_NMCoordinatorBit_1E384090 0;
BA_ "GenSigTimeoutTime_DTCM" SG_ 2654486672 CBV_bit3_NMCoordinatorBit_1E384090 0;
BA_ "GenSigTimeoutTime_ELSDM" SG_ 2654486672 CBV_bit3_NMCoordinatorBit_1E384090 0;
BA_ "GenSigTimeoutTime_BCM" SG_ 2654486672 CBV_bit4_ActiveWakeupBit_1E384090 0;
BA_ "GenSigTimeoutTime_BSM" SG_ 2654486672 CBV_bit4_ActiveWakeupBit_1E384090 0;
BA_ "GenSigTimeoutTime_CADM" SG_ 2654486672 CBV_bit4_ActiveWakeupBit_1E384090 0;
BA_ "GenSigTimeoutTime_DMSM" SG_ 2654486672 CBV_bit4_ActiveWakeupBit_1E384090 0;
BA_ "GenSigTimeoutTime_DTCM" SG_ 2654486672 CBV_bit4_ActiveWakeupBit_1E384090 0;
BA_ "GenSigTimeoutTime_ECM" SG_ 2654486672 CBV_bit4_ActiveWakeupBit_1E384090 0;
BA_ "GenSigTimeoutTime_ELSDM" SG_ 2654486672 CBV_bit4_ActiveWakeupBit_1E384090 0;
BA_ "GenSigTimeoutTime_ESL" SG_ 2654486672 CBV_bit4_ActiveWakeupBit_1E384090 0;
BA_ "GenSigTimeoutTime_GNMM" SG_ 2654486672 CBV_bit4_ActiveWakeupBit_1E384090 0;
BA_ "GenSigTimeoutTime_HCP" SG_ 2654486672 CBV_bit4_ActiveWakeupBit_1E384090 0;
BA_ "GenSigTimeoutTime_IPC" SG_ 2654486672 CBV_bit4_ActiveWakeupBit_1E384090 0;
BA_ "GenSigTimeoutTime_RFHM" SG_ 2654486672 CBV_bit4_ActiveWakeupBit_1E384090 0;
BA_ "GenSigTimeoutTime_SGW" SG_ 2654486672 CBV_bit4_ActiveWakeupBit_1E384090 0;
BA_ "GenSigTimeoutTime_TCM" SG_ 2654486672 CBV_bit4_ActiveWakeupBit_1E384090 0;
BA_ "GenSigTimeoutTime_AGSM" SG_ 2654486672 CBV_bit5_1E384090 0;
BA_ "GenSigTimeoutTime_ASBS" SG_ 2654486672 CBV_bit5_1E384090 0;
BA_ "GenSigTimeoutTime_BCM" SG_ 2654486672 CBV_bit5_1E384090 0;
BA_ "GenSigTimeoutTime_BSM" SG_ 2654486672 CBV_bit5_1E384090 0;
BA_ "GenSigTimeoutTime_CADM" SG_ 2654486672 CBV_bit5_1E384090 0;
BA_ "GenSigTimeoutTime_DMSM" SG_ 2654486672 CBV_bit5_1E384090 0;
BA_ "GenSigTimeoutTime_DTCM" SG_ 2654486672 CBV_bit5_1E384090 0;
BA_ "GenSigTimeoutTime_ECM" SG_ 2654486672 CBV_bit5_1E384090 0;
BA_ "GenSigTimeoutTime_ELSDM" SG_ 2654486672 CBV_bit5_1E384090 0;
BA_ "GenSigTimeoutTime_ESL" SG_ 2654486672 CBV_bit5_1E384090 0;
BA_ "GenSigTimeoutTime_GNMM" SG_ 2654486672 CBV_bit5_1E384090 0;
BA_ "GenSigTimeoutTime_HCP" SG_ 2654486672 CBV_bit5_1E384090 0;
BA_ "GenSigTimeoutTime_IPC" SG_ 2654486672 CBV_bit5_1E384090 0;
BA_ "GenSigTimeoutTime_RFHM" SG_ 2654486672 CBV_bit5_1E384090 0;
BA_ "GenSigTimeoutTime_SGW" SG_ 2654486672 CBV_bit5_1E384090 0;
BA_ "GenSigTimeoutTime_TCM" SG_ 2654486672 CBV_bit5_1E384090 0;
BA_ "GenSigTimeoutTime_AGSM" SG_ 2654486672 CBV_bit6_PartialNtwInfBit_1E384090 0;
BA_ "GenSigTimeoutTime_ASBS" SG_ 2654486672 CBV_bit6_PartialNtwInfBit_1E384090 0;
BA_ "GenSigTimeoutTime_BCM" SG_ 2654486672 CBV_bit6_PartialNtwInfBit_1E384090 0;
BA_ "GenSigTimeoutTime_BSM" SG_ 2654486672 CBV_bit6_PartialNtwInfBit_1E384090 0;
BA_ "GenSigTimeoutTime_CADM" SG_ 2654486672 CBV_bit6_PartialNtwInfBit_1E384090 0;
BA_ "GenSigTimeoutTime_DMSM" SG_ 2654486672 CBV_bit6_PartialNtwInfBit_1E384090 0;
BA_ "GenSigTimeoutTime_DTCM" SG_ 2654486672 CBV_bit6_PartialNtwInfBit_1E384090 0;
BA_ "GenSigTimeoutTime_ECM" SG_ 2654486672 CBV_bit6_PartialNtwInfBit_1E384090 0;
BA_ "GenSigTimeoutTime_ELSDM" SG_ 2654486672 CBV_bit6_PartialNtwInfBit_1E384090 0;
BA_ "GenSigTimeoutTime_ESL" SG_ 2654486672 CBV_bit6_PartialNtwInfBit_1E384090 0;
BA_ "GenSigTimeoutTime_GNMM" SG_ 2654486672 CBV_bit6_PartialNtwInfBit_1E384090 0;
BA_ "GenSigTimeoutTime_HCP" SG_ 2654486672 CBV_bit6_PartialNtwInfBit_1E384090 0;
BA_ "GenSigTimeoutTime_IPC" SG_ 2654486672 CBV_bit6_PartialNtwInfBit_1E384090 0;
BA_ "GenSigTimeoutTime_RFHM" SG_ 2654486672 CBV_bit6_PartialNtwInfBit_1E384090 0;
BA_ "GenSigTimeoutTime_SGW" SG_ 2654486672 CBV_bit6_PartialNtwInfBit_1E384090 0;
BA_ "GenSigTimeoutTime_TCM" SG_ 2654486672 CBV_bit6_PartialNtwInfBit_1E384090 0;
BA_ "GenSigTimeoutTime_AGSM" SG_ 2654486672 CBV_bit7_1E384090 0;
BA_ "GenSigTimeoutTime_ASBS" SG_ 2654486672 CBV_bit7_1E384090 0;
BA_ "GenSigTimeoutTime_BCM" SG_ 2654486672 CBV_bit7_1E384090 0;
BA_ "GenSigTimeoutTime_BSM" SG_ 2654486672 CBV_bit7_1E384090 0;
BA_ "GenSigTimeoutTime_CADM" SG_ 2654486672 CBV_bit7_1E384090 0;
BA_ "GenSigTimeoutTime_DMSM" SG_ 2654486672 CBV_bit7_1E384090 0;
BA_ "GenSigTimeoutTime_DTCM" SG_ 2654486672 CBV_bit7_1E384090 0;
BA_ "GenSigTimeoutTime_ECM" SG_ 2654486672 CBV_bit7_1E384090 0;
BA_ "GenSigTimeoutTime_ELSDM" SG_ 2654486672 CBV_bit7_1E384090 0;
BA_ "GenSigTimeoutTime_ESL" SG_ 2654486672 CBV_bit7_1E384090 0;
BA_ "GenSigTimeoutTime_GNMM" SG_ 2654486672 CBV_bit7_1E384090 0;
BA_ "GenSigTimeoutTime_HCP" SG_ 2654486672 CBV_bit7_1E384090 0;
BA_ "GenSigTimeoutTime_IPC" SG_ 2654486672 CBV_bit7_1E384090 0;
BA_ "GenSigTimeoutTime_RFHM" SG_ 2654486672 CBV_bit7_1E384090 0;
BA_ "GenSigTimeoutTime_SGW" SG_ 2654486672 CBV_bit7_1E384090 0;
BA_ "GenSigTimeoutTime_TCM" SG_ 2654486672 CBV_bit7_1E384090 0;
BA_ "GenSigTimeoutTime_AGSM" SG_ 2654486672 SourceNodeIdentifier_1E384090 0;
BA_ "GenSigTimeoutTime_ASBS" SG_ 2654486672 SourceNodeIdentifier_1E384090 0;
BA_ "GenSigTimeoutTime_BCM" SG_ 2654486672 SourceNodeIdentifier_1E384090 0;
BA_ "GenSigTimeoutTime_BSM" SG_ 2654486672 SourceNodeIdentifier_1E384090 0;
BA_ "GenSigTimeoutTime_CADM" SG_ 2654486672 SourceNodeIdentifier_1E384090 0;
BA_ "GenSigTimeoutTime_DMSM" SG_ 2654486672 SourceNodeIdentifier_1E384090 0;
BA_ "GenSigTimeoutTime_DTCM" SG_ 2654486672 SourceNodeIdentifier_1E384090 0;
BA_ "GenSigTimeoutTime_ECM" SG_ 2654486672 SourceNodeIdentifier_1E384090 0;
BA_ "GenSigTimeoutTime_ELSDM" SG_ 2654486672 SourceNodeIdentifier_1E384090 0;
BA_ "GenSigTimeoutTime_ESL" SG_ 2654486672 SourceNodeIdentifier_1E384090 0;
BA_ "GenSigTimeoutTime_GNMM" SG_ 2654486672 SourceNodeIdentifier_1E384090 0;
BA_ "GenSigTimeoutTime_HCP" SG_ 2654486672 SourceNodeIdentifier_1E384090 0;
BA_ "GenSigTimeoutTime_IPC" SG_ 2654486672 SourceNodeIdentifier_1E384090 0;
BA_ "GenSigTimeoutTime_RFHM" SG_ 2654486672 SourceNodeIdentifier_1E384090 0;
BA_ "GenSigTimeoutTime_SGW" SG_ 2654486672 SourceNodeIdentifier_1E384090 0;
BA_ "GenSigTimeoutTime_TCM" SG_ 2654486672 SourceNodeIdentifier_1E384090 0;
BA_ "GenSigTimeoutTime_ADCAM" SG_ 476 ShiftLeverPositionReq 0;
BA_ "GenSigTimeoutTime_VDCM" SG_ 476 ShiftLeverPositionReq 0;
BA_ "GenSigSendType" SG_ 476 ShiftLeverPositionReq 3;
BA_ "GenSigTimeoutTime_AGSM" SG_ 476 ShiftLeverPositionReq 0;
BA_ "GenSigTimeoutTime_ASBS" SG_ 476 ShiftLeverPositionReq 0;
BA_ "GenSigTimeoutTime_BCM" SG_ 476 ShiftLeverPositionReq 0;
BA_ "GenSigTimeoutTime_BSM" SG_ 476 ShiftLeverPositionReq 0;
BA_ "GenSigTimeoutTime_CADM" SG_ 476 ShiftLeverPositionReq 0;
BA_ "GenSigTimeoutTime_DMSM" SG_ 476 ShiftLeverPositionReq 0;
BA_ "GenSigTimeoutTime_DTCM" SG_ 476 ShiftLeverPositionReq 0;
BA_ "GenSigTimeoutTime_ELSDM" SG_ 476 ShiftLeverPositionReq 0;
BA_ "GenSigTimeoutTime_ESL" SG_ 476 ShiftLeverPositionReq 0;
BA_ "GenSigTimeoutTime_GNMM" SG_ 476 ShiftLeverPositionReq 0;
BA_ "GenSigTimeoutTime_HCP" SG_ 476 ShiftLeverPositionReq 0;
BA_ "GenSigTimeoutTime_AGSM" SG_ 476 CRC_AGSM2 0;
BA_ "GenSigTimeoutTime_ASBS" SG_ 476 CRC_AGSM2 0;
BA_ "GenSigTimeoutTime_BCM" SG_ 476 CRC_AGSM2 0;
BA_ "GenSigTimeoutTime_BSM" SG_ 476 CRC_AGSM2 0;
BA_ "GenSigTimeoutTime_CADM" SG_ 476 CRC_AGSM2 0;
BA_ "GenSigTimeoutTime_DMSM" SG_ 476 CRC_AGSM2 0;
BA_ "GenSigTimeoutTime_DTCM" SG_ 476 CRC_AGSM2 0;
BA_ "GenSigTimeoutTime_ELSDM" SG_ 476 CRC_AGSM2 0;
BA_ "GenSigTimeoutTime_ESL" SG_ 476 CRC_AGSM2 0;
BA_ "GenSigTimeoutTime_GNMM" SG_ 476 CRC_AGSM2 0;
BA_ "GenSigTimeoutTime_HCP" SG_ 476 CRC_AGSM2 0;
BA_ "GenSigTimeoutTime_RFHM" SG_ 476 CRC_AGSM2 0;
BA_ "GenSigTimeoutTime_AGSM" SG_ 476 MessageCounter_AGSM2 0;
BA_ "GenSigTimeoutTime_ASBS" SG_ 476 MessageCounter_AGSM2 0;
BA_ "GenSigTimeoutTime_BCM" SG_ 476 MessageCounter_AGSM2 0;
BA_ "GenSigTimeoutTime_BSM" SG_ 476 MessageCounter_AGSM2 0;
BA_ "GenSigTimeoutTime_CADM" SG_ 476 MessageCounter_AGSM2 0;
BA_ "GenSigTimeoutTime_DMSM" SG_ 476 MessageCounter_AGSM2 0;
BA_ "GenSigTimeoutTime_DTCM" SG_ 476 MessageCounter_AGSM2 0;
BA_ "GenSigTimeoutTime_ELSDM" SG_ 476 MessageCounter_AGSM2 0;
BA_ "GenSigTimeoutTime_ESL" SG_ 476 MessageCounter_AGSM2 0;
BA_ "GenSigTimeoutTime_GNMM" SG_ 476 MessageCounter_AGSM2 0;
BA_ "GenSigTimeoutTime_HCP" SG_ 476 MessageCounter_AGSM2 0;
BA_ "GenSigTimeoutTime_RFHM" SG_ 476 MessageCounter_AGSM2 0;
BA_ "GenSigTimeoutTime_ADCAM" SG_ 258 LongAccelerationFailSts_BSM 0;
BA_ "GenSigTimeoutTime_VDCM" SG_ 258 LongAccelerationFailSts_BSM 0;
BA_ "GenSigTimeoutTime_AGSM" SG_ 258 LongAccelerationFailSts_BSM 0;
BA_ "GenSigTimeoutTime_BSM" SG_ 258 LongAccelerationFailSts_BSM 0;
BA_ "GenSigTimeoutTime_ESL" SG_ 258 LongAccelerationFailSts_BSM 0;
BA_ "GenSigTimeoutTime_RFHM" SG_ 258 LongAccelerationFailSts_BSM 0;
BA_ "GenSigTimeoutTime_TCM" SG_ 258 LongAccelerationFailSts_BSM 0;
BA_ "GenSigTimeoutTime_ADCAM" SG_ 258 LatAccelerationFailSts_BSM 0;
BA_ "GenSigTimeoutTime_VDCM" SG_ 258 LatAccelerationFailSts_BSM 0;
BA_ "GenSigTimeoutTime_AGSM" SG_ 258 LatAccelerationFailSts_BSM 0;
BA_ "GenSigTimeoutTime_BSM" SG_ 258 LatAccelerationFailSts_BSM 0;
BA_ "GenSigTimeoutTime_ESL" SG_ 258 LatAccelerationFailSts_BSM 0;
BA_ "GenSigTimeoutTime_RFHM" SG_ 258 LatAccelerationFailSts_BSM 0;
BA_ "GenSigTimeoutTime_TCM" SG_ 258 LatAccelerationFailSts_BSM 0;
BA_ "GenSigTimeoutTime_ADCAM" SG_ 258 LongAcceleration_BSM 0;
BA_ "GenSigStartValue" SG_ 258 LongAcceleration_BSM 4095;
BA_ "GenSigTimeoutTime_AGSM" SG_ 258 LongAcceleration_BSM 0;
BA_ "GenSigTimeoutTime_BSM" SG_ 258 LongAcceleration_BSM 0;
BA_ "GenSigTimeoutTime_ESL" SG_ 258 LongAcceleration_BSM 0;
BA_ "GenSigTimeoutTime_RFHM" SG_ 258 LongAcceleration_BSM 0;
BA_ "GenSigTimeoutTime_ADCAM" SG_ 258 LatAcceleration_BSM 0;
BA_ "GenSigStartValue" SG_ 258 LatAcceleration_BSM 4095;
BA_ "GenSigTimeoutTime_AGSM" SG_ 258 LatAcceleration_BSM 0;
BA_ "GenSigTimeoutTime_BSM" SG_ 258 LatAcceleration_BSM 0;
BA_ "GenSigTimeoutTime_ESL" SG_ 258 LatAcceleration_BSM 0;
BA_ "GenSigTimeoutTime_RFHM" SG_ 258 LatAcceleration_BSM 0;
BA_ "GenSigTimeoutTime_ESL" SG_ 258 VehicleSpeedVSOSig 0;
BA_ "GenSigTimeoutTime_ADCAM" SG_ 258 Brk_Stat 0;
BA_ "GenSigTimeoutTime_EVCU2" SG_ 258 Brk_Stat 0;
BA_ "GenSigTimeoutTime_ADCAM" SG_ 258 BrakeBoostPressure 0;
BA_ "GenSigTimeoutTime_ADCAM" SG_ 258 BrakeInterventionSts 0;
BA_ "GenSigTimeoutTime_VDCM" SG_ 258 BrakeInterventionSts 0;
BA_ "GenSigTimeoutTime_ADCAM" SG_ 258 BrakePedalPressure 0;
BA_ "GenSigTimeoutTime_VDCM" SG_ 258 BrakePedalPressure 0;
BA_ "GenSigStartValue" SG_ 258 ESP_Sys_Stat 1;
BA_ "GenSigTimeoutTime_AGSM" SG_ 258 ESP_Sys_Stat 0;
BA_ "GenSigTimeoutTime_ASBS" SG_ 258 ESP_Sys_Stat 0;
BA_ "GenSigTimeoutTime_BCM" SG_ 258 ESP_Sys_Stat 0;
BA_ "GenSigTimeoutTime_BSM" SG_ 258 ESP_Sys_Stat 0;
BA_ "GenSigTimeoutTime_CADM" SG_ 258 ESP_Sys_Stat 0;
BA_ "GenSigTimeoutTime_DMSM" SG_ 258 ESP_Sys_Stat 0;
BA_ "GenSigTimeoutTime_DTCM" SG_ 258 ESP_Sys_Stat 0;
BA_ "GenSigTimeoutTime_ELSDM" SG_ 258 ESP_Sys_Stat 0;
BA_ "GenSigTimeoutTime_ESL" SG_ 258 ESP_Sys_Stat 0;
BA_ "GenSigTimeoutTime_GNMM" SG_ 258 ESP_Sys_Stat 0;
BA_ "GenSigTimeoutTime_HCP" SG_ 258 ESP_Sys_Stat 0;
BA_ "GenSigTimeoutTime_IPC" SG_ 258 ESP_Sys_Stat 0;
BA_ "GenSigTimeoutTime_RFHM" SG_ 258 ESP_Sys_Stat 0;
BA_ "GenSigTimeoutTime_SGW" SG_ 258 ESP_Sys_Stat 0;
BA_ "GenSigTimeoutTime_AGSM" SG_ 258 ImpendingSkid 0;
BA_ "GenSigTimeoutTime_ASBS" SG_ 258 ImpendingSkid 0;
BA_ "GenSigTimeoutTime_BCM" SG_ 258 ImpendingSkid 0;
BA_ "GenSigTimeoutTime_BSM" SG_ 258 ImpendingSkid 0;
BA_ "GenSigTimeoutTime_CADM" SG_ 258 ImpendingSkid 0;
BA_ "GenSigTimeoutTime_DMSM" SG_ 258 ImpendingSkid 0;
BA_ "GenSigTimeoutTime_DTCM" SG_ 258 ImpendingSkid 0;
BA_ "GenSigTimeoutTime_ELSDM" SG_ 258 ImpendingSkid 0;
BA_ "GenSigTimeoutTime_ESL" SG_ 258 ImpendingSkid 0;
BA_ "GenSigTimeoutTime_GNMM" SG_ 258 ImpendingSkid 0;
BA_ "GenSigTimeoutTime_IPC" SG_ 258 ImpendingSkid 0;
BA_ "GenSigTimeoutTime_RFHM" SG_ 258 ImpendingSkid 0;
BA_ "GenSigTimeoutTime_SGW" SG_ 258 ImpendingSkid 0;
BA_ "GenSigTimeoutTime_TCM" SG_ 258 ImpendingSkid 0;
BA_ "GenSigTimeoutTime_ASBS" SG_ 258 MessageCounter_BRAKE2 0;
BA_ "GenSigTimeoutTime_BSM" SG_ 258 MessageCounter_BRAKE2 0;
BA_ "GenSigTimeoutTime_ELSDM" SG_ 258 MessageCounter_BRAKE2 0;
BA_ "GenSigTimeoutTime_IPC" SG_ 258 MessageCounter_BRAKE2 0;
BA_ "GenSigTimeoutTime_BSM" SG_ 258 VehicleSpeedVSOSig 0;
BA_ "GenSigTimeoutTime_ELSDM" SG_ 258 VehicleSpeedVSOSig 0;
BA_ "GenSigTimeoutTime_AGSM" SG_ 258 Brk_Stat 0;
BA_ "GenSigTimeoutTime_ASBS" SG_ 258 Brk_Stat 0;
BA_ "GenSigTimeoutTime_BSM" SG_ 258 Brk_Stat 0;
BA_ "GenSigTimeoutTime_CADM" SG_ 258 Brk_Stat 0;
BA_ "GenSigTimeoutTime_DMSM" SG_ 258 Brk_Stat 0;
BA_ "GenSigTimeoutTime_DTCM" SG_ 258 Brk_Stat 0;
BA_ "GenSigTimeoutTime_ELSDM" SG_ 258 Brk_Stat 0;
BA_ "GenSigTimeoutTime_ESL" SG_ 258 Brk_Stat 0;
BA_ "GenSigTimeoutTime_GNMM" SG_ 258 Brk_Stat 0;
BA_ "GenSigTimeoutTime_HCP" SG_ 258 Brk_Stat 0;
BA_ "GenSigTimeoutTime_IPC" SG_ 258 Brk_Stat 0;
BA_ "GenSigTimeoutTime_RFHM" SG_ 258 Brk_Stat 0;
BA_ "GenSigTimeoutTime_TCM" SG_ 258 Brk_Stat 0;
BA_ "GenSigStartValue" SG_ 258 BrakeBoostPressure 2047;
BA_ "GenSigTimeoutTime_AGSM" SG_ 258 BrakeBoostPressure 0;
BA_ "GenSigTimeoutTime_ASBS" SG_ 258 BrakeBoostPressure 0;
BA_ "GenSigTimeoutTime_BSM" SG_ 258 BrakeBoostPressure 0;
BA_ "GenSigTimeoutTime_CADM" SG_ 258 BrakeBoostPressure 0;
BA_ "GenSigTimeoutTime_DMSM" SG_ 258 BrakeBoostPressure 0;
BA_ "GenSigTimeoutTime_DTCM" SG_ 258 BrakeBoostPressure 0;
BA_ "GenSigTimeoutTime_ELSDM" SG_ 258 BrakeBoostPressure 0;
BA_ "GenSigTimeoutTime_ESL" SG_ 258 BrakeBoostPressure 0;
BA_ "GenSigTimeoutTime_GNMM" SG_ 258 BrakeBoostPressure 0;
BA_ "GenSigTimeoutTime_HCP" SG_ 258 BrakeBoostPressure 0;
BA_ "GenSigTimeoutTime_IPC" SG_ 258 BrakeBoostPressure 0;
BA_ "GenSigTimeoutTime_RFHM" SG_ 258 BrakeBoostPressure 0;
BA_ "GenSigTimeoutTime_AGSM" SG_ 258 BrakeInterventionSts 0;
BA_ "GenSigTimeoutTime_ASBS" SG_ 258 BrakeInterventionSts 0;
BA_ "GenSigTimeoutTime_BSM" SG_ 258 BrakeInterventionSts 0;
BA_ "GenSigTimeoutTime_CADM" SG_ 258 BrakeInterventionSts 0;
BA_ "GenSigTimeoutTime_DMSM" SG_ 258 BrakeInterventionSts 0;
BA_ "GenSigTimeoutTime_ELSDM" SG_ 258 BrakeInterventionSts 0;
BA_ "GenSigTimeoutTime_ESL" SG_ 258 BrakeInterventionSts 0;
BA_ "GenSigTimeoutTime_GNMM" SG_ 258 BrakeInterventionSts 0;
BA_ "GenSigTimeoutTime_HCP" SG_ 258 BrakeInterventionSts 0;
BA_ "GenSigTimeoutTime_IPC" SG_ 258 BrakeInterventionSts 0;
BA_ "GenSigTimeoutTime_RFHM" SG_ 258 BrakeInterventionSts 0;
BA_ "GenSigTimeoutTime_SGW" SG_ 258 BrakeInterventionSts 0;
BA_ "GenSigStartValue" SG_ 258 BrakePedalPressure 2047;
BA_ "GenSigTimeoutTime_AGSM" SG_ 258 BrakePedalPressure 0;
BA_ "GenSigTimeoutTime_ASBS" SG_ 258 BrakePedalPressure 0;
BA_ "GenSigTimeoutTime_BSM" SG_ 258 BrakePedalPressure 0;
BA_ "GenSigTimeoutTime_CADM" SG_ 258 BrakePedalPressure 0;
BA_ "GenSigTimeoutTime_DMSM" SG_ 258 BrakePedalPressure 0;
BA_ "GenSigTimeoutTime_DTCM" SG_ 258 BrakePedalPressure 0;
BA_ "GenSigTimeoutTime_ELSDM" SG_ 258 BrakePedalPressure 0;
BA_ "GenSigTimeoutTime_ESL" SG_ 258 BrakePedalPressure 0;
BA_ "GenSigTimeoutTime_GNMM" SG_ 258 BrakePedalPressure 0;
BA_ "GenSigTimeoutTime_AGSM" SG_ 204 Rear_AxleTorque_Max 0;
BA_ "GenSigTimeoutTime_BCM" SG_ 204 Rear_AxleTorque_Max 0;
BA_ "GenSigTimeoutTime_DTCM" SG_ 204 Rear_AxleTorque_Max 0;
BA_ "GenSigTimeoutTime_ECM" SG_ 204 Rear_AxleTorque_Max 0;
BA_ "GenSigTimeoutTime_ESL" SG_ 204 Rear_AxleTorque_Max 0;
BA_ "GenSigTimeoutTime_IPC" SG_ 204 Rear_AxleTorque_Max 0;
BA_ "GenSigTimeoutTime_RFHM" SG_ 204 Rear_AxleTorque_Max 0;
BA_ "GenSigTimeoutTime_TCM" SG_ 204 Rear_AxleTorque_Max 0;
BA_ "GenSigTimeoutTime_ADCAM" SG_ 204 Front_AxleTorque_Min 0;
BA_ "GenSigTimeoutTime_EVCU2" SG_ 204 Front_AxleTorque_Min 0;
BA_ "GenSigTimeoutTime_VDCM" SG_ 204 Front_AxleTorque_Min 0;
BA_ "GenSigStartValue" SG_ 204 Front_AxleTorque_Min 32767;
BA_ "GenSigTimeoutTime_AGSM" SG_ 204 Front_AxleTorque_Min 0;
BA_ "GenSigTimeoutTime_BCM" SG_ 204 Front_AxleTorque_Min 0;
BA_ "GenSigTimeoutTime_DTCM" SG_ 204 Front_AxleTorque_Min 0;
BA_ "GenSigTimeoutTime_ECM" SG_ 204 Front_AxleTorque_Min 0;
BA_ "GenSigTimeoutTime_ESL" SG_ 204 Front_AxleTorque_Min 0;
BA_ "GenSigTimeoutTime_IPC" SG_ 204 Front_AxleTorque_Min 0;
BA_ "GenSigTimeoutTime_RFHM" SG_ 204 Front_AxleTorque_Min 0;
BA_ "GenSigTimeoutTime_TCM" SG_ 204 Front_AxleTorque_Min 0;
BA_ "GenSigTimeoutTime_ADCAM" SG_ 204 Front_AxleTorque_Max 0;
BA_ "GenSigTimeoutTime_EVCU2" SG_ 204 Front_AxleTorque_Max 0;
BA_ "GenSigTimeoutTime_VDCM" SG_ 204 Front_AxleTorque_Max 0;
BA_ "GenSigStartValue" SG_ 204 Front_AxleTorque_Max 32767;
BA_ "GenSigTimeoutTime_AGSM" SG_ 204 Front_AxleTorque_Max 0;
BA_ "GenSigTimeoutTime_BCM" SG_ 204 Front_AxleTorque_Max 0;
BA_ "GenSigTimeoutTime_DTCM" SG_ 204 Front_AxleTorque_Max 0;
BA_ "GenSigTimeoutTime_ECM" SG_ 204 Front_AxleTorque_Max 0;
BA_ "GenSigTimeoutTime_ESL" SG_ 204 Front_AxleTorque_Max 0;
BA_ "GenSigTimeoutTime_IPC" SG_ 204 Front_AxleTorque_Max 0;
BA_ "GenSigTimeoutTime_RFHM" SG_ 204 Front_AxleTorque_Max 0;
BA_ "GenSigTimeoutTime_TCM" SG_ 204 Front_AxleTorque_Max 0;
BA_ "GenSigTimeoutTime_ADCAM" SG_ 204 Axle_Torque_DrvReqMod 0;
BA_ "GenSigTimeoutTime_EVCU2" SG_ 204 Axle_Torque_DrvReqMod 0;
BA_ "GenSigTimeoutTime_VDCM" SG_ 204 Axle_Torque_DrvReqMod 0;
BA_ "GenSigTimeoutTime_ADCAM" SG_ 204 Axle_TorqueStatic_D_TTC 0;
BA_ "GenSigTimeoutTime_EVCU2" SG_ 204 Axle_TorqueStatic_D_TTC 0;
BA_ "GenSigTimeoutTime_VDCM" SG_ 204 Axle_TorqueStatic_D_TTC 0;
BA_ "GenSigTimeoutTime_ADCAM" SG_ 204 Total_AxleTorque_Max 0;
BA_ "GenSigTimeoutTime_EVCU2" SG_ 204 Total_AxleTorque_Max 0;
BA_ "GenSigTimeoutTime_VDCM" SG_ 204 Total_AxleTorque_Max 0;
BA_ "GenSigTimeoutTime_ADCAM" SG_ 204 Total_AxleTorque_Min 0;
BA_ "GenSigTimeoutTime_EVCU2" SG_ 204 Total_AxleTorque_Min 0;
BA_ "GenSigTimeoutTime_VDCM" SG_ 204 Total_AxleTorque_Min 0;
BA_ "GenSigTimeoutTime_ADCAM" SG_ 204 CRC_AXLE_TORQUE_FD_1 0;
BA_ "GenSigTimeoutTime_EVCU2" SG_ 204 CRC_AXLE_TORQUE_FD_1 0;
BA_ "GenSigTimeoutTime_VDCM" SG_ 204 CRC_AXLE_TORQUE_FD_1 0;
BA_ "GenSigTimeoutTime_ADCAM" SG_ 204 MessageCounter_AXLE_TORQUE_FD_1 0;
BA_ "GenSigTimeoutTime_EVCU2" SG_ 204 MessageCounter_AXLE_TORQUE_FD_1 0;
BA_ "GenSigTimeoutTime_VDCM" SG_ 204 MessageCounter_AXLE_TORQUE_FD_1 0;
BA_ "GenSigStartValue" SG_ 204 Axle_Torque_DrvReqMod 32768;
BA_ "GenSigTimeoutTime_AGSM" SG_ 204 Axle_Torque_DrvReqMod 0;
BA_ "GenSigTimeoutTime_ASBS" SG_ 204 Axle_Torque_DrvReqMod 0;
BA_ "GenSigTimeoutTime_BCM" SG_ 204 Axle_Torque_DrvReqMod 0;
BA_ "GenSigTimeoutTime_CADM" SG_ 204 Axle_Torque_DrvReqMod 0;
BA_ "GenSigTimeoutTime_DMSM" SG_ 204 Axle_Torque_DrvReqMod 0;
BA_ "GenSigTimeoutTime_DTCM" SG_ 204 Axle_Torque_DrvReqMod 0;
BA_ "GenSigTimeoutTime_ECM" SG_ 204 Axle_Torque_DrvReqMod 0;
BA_ "GenSigTimeoutTime_ELSDM" SG_ 204 Axle_Torque_DrvReqMod 0;
BA_ "GenSigTimeoutTime_ESL" SG_ 204 Axle_Torque_DrvReqMod 0;
BA_ "GenSigTimeoutTime_GNMM" SG_ 204 Axle_Torque_DrvReqMod 0;
BA_ "GenSigTimeoutTime_HCP" SG_ 204 Axle_Torque_DrvReqMod 0;
BA_ "GenSigTimeoutTime_IPC" SG_ 204 Axle_Torque_DrvReqMod 0;
BA_ "GenSigTimeoutTime_RFHM" SG_ 204 Axle_Torque_DrvReqMod 0;
BA_ "GenSigTimeoutTime_SGW" SG_ 204 Axle_Torque_DrvReqMod 0;
BA_ "GenSigTimeoutTime_TCM" SG_ 204 Axle_Torque_DrvReqMod 0;
BA_ "GenSigStartValue" SG_ 204 Axle_TorqueStatic_D_TTC 32767;
BA_ "GenSigTimeoutTime_AGSM" SG_ 204 Axle_TorqueStatic_D_TTC 0;
BA_ "GenSigTimeoutTime_ASBS" SG_ 204 Axle_TorqueStatic_D_TTC 0;
BA_ "GenSigTimeoutTime_CADM" SG_ 204 Axle_TorqueStatic_D_TTC 0;
BA_ "GenSigTimeoutTime_DMSM" SG_ 204 Axle_TorqueStatic_D_TTC 0;
BA_ "GenSigTimeoutTime_DTCM" SG_ 204 Axle_TorqueStatic_D_TTC 0;
BA_ "GenSigTimeoutTime_ECM" SG_ 204 Axle_TorqueStatic_D_TTC 0;
BA_ "GenSigTimeoutTime_ELSDM" SG_ 204 Axle_TorqueStatic_D_TTC 0;
BA_ "GenSigTimeoutTime_ESL" SG_ 204 Axle_TorqueStatic_D_TTC 0;
BA_ "GenSigTimeoutTime_GNMM" SG_ 204 Axle_TorqueStatic_D_TTC 0;
BA_ "GenSigTimeoutTime_HCP" SG_ 204 Axle_TorqueStatic_D_TTC 0;
BA_ "GenSigTimeoutTime_IPC" SG_ 204 Axle_TorqueStatic_D_TTC 0;
BA_ "GenSigTimeoutTime_RFHM" SG_ 204 Axle_TorqueStatic_D_TTC 0;
BA_ "GenSigTimeoutTime_SGW" SG_ 204 Axle_TorqueStatic_D_TTC 0;
BA_ "GenSigTimeoutTime_TCM" SG_ 204 Axle_TorqueStatic_D_TTC 0;
BA_ "GenSigStartValue" SG_ 204 Total_AxleTorque_Max 32767;
BA_ "GenSigTimeoutTime_AGSM" SG_ 204 Total_AxleTorque_Max 0;
BA_ "GenSigTimeoutTime_ASBS" SG_ 204 Total_AxleTorque_Max 0;
BA_ "GenSigTimeoutTime_BCM" SG_ 204 Total_AxleTorque_Max 0;
BA_ "GenSigTimeoutTime_CADM" SG_ 204 Total_AxleTorque_Max 0;
BA_ "GenSigTimeoutTime_DMSM" SG_ 204 Total_AxleTorque_Max 0;
BA_ "GenSigTimeoutTime_DTCM" SG_ 204 Total_AxleTorque_Max 0;
BA_ "GenSigTimeoutTime_ECM" SG_ 204 Total_AxleTorque_Max 0;
BA_ "GenSigTimeoutTime_ELSDM" SG_ 204 Total_AxleTorque_Max 0;
BA_ "GenSigTimeoutTime_ESL" SG_ 204 Total_AxleTorque_Max 0;
BA_ "GenSigTimeoutTime_GNMM" SG_ 204 Total_AxleTorque_Max 0;
BA_ "GenSigTimeoutTime_HCP" SG_ 204 Total_AxleTorque_Max 0;
BA_ "GenSigTimeoutTime_IPC" SG_ 204 Total_AxleTorque_Max 0;
BA_ "GenSigTimeoutTime_RFHM" SG_ 204 Total_AxleTorque_Max 0;
BA_ "GenSigTimeoutTime_SGW" SG_ 204 Total_AxleTorque_Max 0;
BA_ "GenSigTimeoutTime_TCM" SG_ 204 Total_AxleTorque_Max 0;
BA_ "GenSigStartValue" SG_ 204 Total_AxleTorque_Min 32767;
BA_ "GenSigTimeoutTime_AGSM" SG_ 204 Total_AxleTorque_Min 0;
BA_ "GenSigTimeoutTime_ASBS" SG_ 204 Total_AxleTorque_Min 0;
BA_ "GenSigTimeoutTime_BCM" SG_ 204 Total_AxleTorque_Min 0;
BA_ "GenSigTimeoutTime_CADM" SG_ 204 Total_AxleTorque_Min 0;
BA_ "GenSigTimeoutTime_DMSM" SG_ 204 Total_AxleTorque_Min 0;
BA_ "GenSigTimeoutTime_DTCM" SG_ 204 Total_AxleTorque_Min 0;
BA_ "GenSigTimeoutTime_ECM" SG_ 204 Total_AxleTorque_Min 0;
BA_ "GenSigTimeoutTime_ELSDM" SG_ 204 Total_AxleTorque_Min 0;
BA_ "GenSigTimeoutTime_ESL" SG_ 204 Total_AxleTorque_Min 0;
BA_ "GenSigTimeoutTime_GNMM" SG_ 204 Total_AxleTorque_Min 0;
BA_ "GenSigTimeoutTime_HCP" SG_ 204 Total_AxleTorque_Min 0;
BA_ "GenSigTimeoutTime_IPC" SG_ 204 Total_AxleTorque_Min 0;
BA_ "GenSigTimeoutTime_RFHM" SG_ 204 Total_AxleTorque_Min 0;
BA_ "GenSigTimeoutTime_SGW" SG_ 204 Total_AxleTorque_Min 0;
BA_ "GenSigTimeoutTime_TCM" SG_ 204 Total_AxleTorque_Min 0;
BA_ "GenSigTimeoutTime_AGSM" SG_ 204 CRC_AXLE_TORQUE_FD_1 0;
BA_ "GenSigTimeoutTime_ASBS" SG_ 204 CRC_AXLE_TORQUE_FD_1 0;
BA_ "GenSigTimeoutTime_BCM" SG_ 204 CRC_AXLE_TORQUE_FD_1 0;
BA_ "GenSigTimeoutTime_CADM" SG_ 204 CRC_AXLE_TORQUE_FD_1 0;
BA_ "GenSigTimeoutTime_DMSM" SG_ 204 CRC_AXLE_TORQUE_FD_1 0;
BA_ "GenSigTimeoutTime_DTCM" SG_ 204 CRC_AXLE_TORQUE_FD_1 0;
BA_ "GenSigTimeoutTime_ECM" SG_ 204 CRC_AXLE_TORQUE_FD_1 0;
BA_ "GenSigTimeoutTime_ELSDM" SG_ 204 CRC_AXLE_TORQUE_FD_1 0;
BA_ "GenSigTimeoutTime_ESL" SG_ 204 CRC_AXLE_TORQUE_FD_1 0;
BA_ "GenSigTimeoutTime_GNMM" SG_ 204 CRC_AXLE_TORQUE_FD_1 0;
BA_ "GenSigTimeoutTime_HCP" SG_ 204 CRC_AXLE_TORQUE_FD_1 0;
BA_ "GenSigTimeoutTime_IPC" SG_ 204 CRC_AXLE_TORQUE_FD_1 0;
BA_ "GenSigTimeoutTime_RFHM" SG_ 204 CRC_AXLE_TORQUE_FD_1 0;
BA_ "GenSigTimeoutTime_SGW" SG_ 204 CRC_AXLE_TORQUE_FD_1 0;
BA_ "GenSigTimeoutTime_TCM" SG_ 204 CRC_AXLE_TORQUE_FD_1 0;
BA_ "GenSigTimeoutTime_AGSM" SG_ 204 MessageCounter_AXLE_TORQUE_FD_1 0;
BA_ "GenSigTimeoutTime_ASBS" SG_ 204 MessageCounter_AXLE_TORQUE_FD_1 0;
BA_ "GenSigTimeoutTime_BCM" SG_ 204 MessageCounter_AXLE_TORQUE_FD_1 0;
BA_ "GenSigTimeoutTime_CADM" SG_ 204 MessageCounter_AXLE_TORQUE_FD_1 0;
BA_ "GenSigTimeoutTime_DMSM" SG_ 204 MessageCounter_AXLE_TORQUE_FD_1 0;
BA_ "GenSigTimeoutTime_DTCM" SG_ 204 MessageCounter_AXLE_TORQUE_FD_1 0;
BA_ "GenSigTimeoutTime_ECM" SG_ 204 MessageCounter_AXLE_TORQUE_FD_1 0;
BA_ "GenSigTimeoutTime_ELSDM" SG_ 204 MessageCounter_AXLE_TORQUE_FD_1 0;
BA_ "GenSigTimeoutTime_ESL" SG_ 204 MessageCounter_AXLE_TORQUE_FD_1 0;
BA_ "GenSigTimeoutTime_GNMM" SG_ 204 MessageCounter_AXLE_TORQUE_FD_1 0;
BA_ "GenSigTimeoutTime_HCP" SG_ 204 MessageCounter_AXLE_TORQUE_FD_1 0;
BA_ "GenSigTimeoutTime_IPC" SG_ 204 MessageCounter_AXLE_TORQUE_FD_1 0;
BA_ "GenSigTimeoutTime_RFHM" SG_ 204 MessageCounter_AXLE_TORQUE_FD_1 0;
BA_ "GenSigTimeoutTime_SGW" SG_ 204 MessageCounter_AXLE_TORQUE_FD_1 0;
BA_ "GenSigTimeoutTime_TCM" SG_ 204 MessageCounter_AXLE_TORQUE_FD_1 0;
BA_ "GenSigTimeoutTime_ADCAM" SG_ 2564486416 N_PDU_18DAF510 0;
BA_ "GenSigTimeoutTime_EVCU2" SG_ 2564486416 N_PDU_18DAF510 0;
BA_ "GenSigTimeoutTime_VDCM" SG_ 2564486416 N_PDU_18DAF510 0;
BA_ "GenSigTimeoutTime_AGSM" SG_ 2564486416 N_PDU_18DAF510 0;
BA_ "GenSigTimeoutTime_ASBS" SG_ 2564486416 N_PDU_18DAF510 0;
BA_ "GenSigTimeoutTime_BCM" SG_ 2564486416 N_PDU_18DAF510 0;
BA_ "GenSigTimeoutTime_BSM" SG_ 2564486416 N_PDU_18DAF510 0;
BA_ "GenSigTimeoutTime_CADM" SG_ 2564486416 N_PDU_18DAF510 0;
BA_ "GenSigTimeoutTime_DMSM" SG_ 2564486416 N_PDU_18DAF510 0;
BA_ "GenSigTimeoutTime_DTCM" SG_ 2564486416 N_PDU_18DAF510 0;
BA_ "GenSigTimeoutTime_ECM" SG_ 2564486416 N_PDU_18DAF510 0;
BA_ "GenSigTimeoutTime_ELSDM" SG_ 2564486416 N_PDU_18DAF510 0;
BA_ "GenSigTimeoutTime_ESL" SG_ 2564486416 N_PDU_18DAF510 0;
BA_ "GenSigTimeoutTime_GNMM" SG_ 2564486416 N_PDU_18DAF510 0;
BA_ "GenSigTimeoutTime_HCP" SG_ 2564486416 N_PDU_18DAF510 0;
BA_ "GenSigTimeoutTime_IPC" SG_ 2564486416 N_PDU_18DAF510 0;
BA_ "GenSigTimeoutTime_RFHM" SG_ 2564486416 N_PDU_18DAF510 0;
BA_ "GenSigTimeoutTime_SGW" SG_ 2564486416 N_PDU_18DAF510 0;
BA_ "GenSigTimeoutTime_TCM" SG_ 2564486416 N_PDU_18DAF510 0;
BA_ "GenSigTimeoutTime_ADCAM" SG_ 262 GasPedalPositionFailSts_W 0;
BA_ "GenSigTimeoutTime_EVCU2" SG_ 262 GasPedalPositionFailSts_W 0;
BA_ "GenSigTimeoutTime_VDCM" SG_ 262 GasPedalPositionFailSts_W 0;
BA_ "GenSigTimeoutTime_TCM" SG_ 262 GasPedalPositionFailSts_W 0;
BA_ "GenSigTimeoutTime_ADCAM" SG_ 262 IntakeAirTemperature_W 0;
BA_ "GenSigTimeoutTime_EVCU2" SG_ 262 IntakeAirTemperature_W 0;
BA_ "GenSigTimeoutTime_VDCM" SG_ 262 IntakeAirTemperature_W 0;
BA_ "GenSigTimeoutTime_TCM" SG_ 262 IntakeAirTemperature_W 0;
BA_ "GenSigTimeoutTime_ADCAM" SG_ 262 KickDownRequest_W 0;
BA_ "GenSigTimeoutTime_EVCU2" SG_ 262 KickDownRequest_W 0;
BA_ "GenSigTimeoutTime_VDCM" SG_ 262 KickDownRequest_W 0;
BA_ "GenSigTimeoutTime_ADCAM" SG_ 262 LV12PwrFreeRq_W 0;
BA_ "GenSigTimeoutTime_EVCU2" SG_ 262 LV12PwrFreeRq_W 0;
BA_ "GenSigTimeoutTime_VDCM" SG_ 262 LV12PwrFreeRq_W 0;
BA_ "GenSigTimeoutTime_EVCU2" SG_ 262 MessageCounter_ENGINE2 0;
BA_ "GenSigTimeoutTime_VDCM" SG_ 262 MessageCounter_ENGINE2 0;
BA_ "GenSigTimeoutTime_EVCU2" SG_ 262 PowertrainPrplsnActv 0;
BA_ "GenSigTimeoutTime_VDCM" SG_ 262 PowertrainPrplsnActv 0;
BA_ "GenSigTimeoutTime_ADCAM" SG_ 262 ESS_ENG_ST_W 0;
BA_ "GenSigTimeoutTime_EVCU2" SG_ 262 ESS_ENG_ST_W 0;
BA_ "GenSigTimeoutTime_VDCM" SG_ 262 ESS_ENG_ST_W 0;
BA_ "GenSigTimeoutTime_TCM" SG_ 262 ESS_ENG_ST_W 0;
BA_ "GenSigTimeoutTime_ADCAM" SG_ 262 ESS_RqShftPark_W 0;
BA_ "GenSigTimeoutTime_EVCU2" SG_ 262 ESS_RqShftPark_W 0;
BA_ "GenSigTimeoutTime_VDCM" SG_ 262 ESS_RqShftPark_W 0;
BA_ "GenSigTimeoutTime_ADCAM" SG_ 262 GasPedalGradient_W 0;
BA_ "GenSigTimeoutTime_EVCU2" SG_ 262 GasPedalGradient_W 0;
BA_ "GenSigTimeoutTime_VDCM" SG_ 262 GasPedalGradient_W 0;
BA_ "GenSigTimeoutTime_BCM" SG_ 262 GasPedalGradient_W 0;
BA_ "GenSigTimeoutTime_ADCAM" SG_ 262 GasPedalPosition_W 0;
BA_ "GenSigTimeoutTime_EVCU2" SG_ 262 GasPedalPosition_W 0;
BA_ "GenSigTimeoutTime_VDCM" SG_ 262 GasPedalPosition_W 0;
BA_ "GenSigTimeoutTime_TCM" SG_ 262 GasPedalPosition_W 0;
BA_ "GenSigTimeoutTime_ADCAM" SG_ 262 EngineIdleRefSpeed 0;
BA_ "GenSigTimeoutTime_EVCU2" SG_ 262 EngineIdleRefSpeed 0;
BA_ "GenSigTimeoutTime_VDCM" SG_ 262 EngineIdleRefSpeed 0;
BA_ "GenSigTimeoutTime_VDCM" SG_ 262 EngineSpeed_W 0;
BA_ "GenSigTimeoutTime_ADCAM" SG_ 262 EngineSpeedFailSts_W 0;
BA_ "GenSigTimeoutTime_EVCU2" SG_ 262 EngineSpeedFailSts_W 0;
BA_ "GenSigTimeoutTime_VDCM" SG_ 262 EngineSpeedFailSts_W 0;
BA_ "GenSigTimeoutTime_ADCAM" SG_ 262 EngineSts_W 0;
BA_ "GenSigTimeoutTime_EVCU2" SG_ 262 EngineSts_W 0;
BA_ "GenSigTimeoutTime_VDCM" SG_ 262 EngineSts_W 0;
BA_ "GenSigTimeoutTime_TCM" SG_ 262 EngineSts_W 0;
BA_ "GenSigTimeoutTime_ADCAM" SG_ 262 EngRPM_Tach 0;
BA_ "GenSigTimeoutTime_EVCU2" SG_ 262 EngRPM_Tach 0;
BA_ "GenSigTimeoutTime_VDCM" SG_ 262 EngRPM_Tach 0;
BA_ "GenSigTimeoutTime_ADCAM" SG_ 262 EngTrq_Enbl_Rq_TCM_W 0;
BA_ "GenSigTimeoutTime_EVCU2" SG_ 262 EngTrq_Enbl_Rq_TCM_W 0;
BA_ "GenSigTimeoutTime_VDCM" SG_ 262 EngTrq_Enbl_Rq_TCM_W 0;
BA_ "GenSigTimeoutTime_EVCU2" SG_ 262 CRC_ENGINE2 0;
BA_ "GenSigTimeoutTime_VDCM" SG_ 262 CRC_ENGINE2 0;
BA_ "GenSigTimeoutTime_ADCAM" SG_ 262 ECM_IMMO_STAT_CANC_W 0;
BA_ "GenSigTimeoutTime_EVCU2" SG_ 262 ECM_IMMO_STAT_CANC_W 0;
BA_ "GenSigTimeoutTime_VDCM" SG_ 262 ECM_IMMO_STAT_CANC_W 0;
BA_ "GenSigTimeoutTime_ADCAM" SG_ 262 ECM_LHOM_Trans_W 0;
BA_ "GenSigTimeoutTime_EVCU2" SG_ 262 ECM_LHOM_Trans_W 0;
BA_ "GenSigTimeoutTime_VDCM" SG_ 262 ECM_LHOM_Trans_W 0;
BA_ "GenSigTimeoutTime_ADCAM" SG_ 262 ECM_LHOM_W 0;
BA_ "GenSigTimeoutTime_EVCU2" SG_ 262 ECM_LHOM_W 0;
BA_ "GenSigTimeoutTime_VDCM" SG_ 262 ECM_LHOM_W 0;
BA_ "GenSigTimeoutTime_ADCAM" SG_ 262 EngineFrictionTorque_W 0;
BA_ "GenSigTimeoutTime_EVCU2" SG_ 262 EngineFrictionTorque_W 0;
BA_ "GenSigTimeoutTime_VDCM" SG_ 262 EngineFrictionTorque_W 0;
BA_ "GenSigTimeoutTime_BCM" SG_ 262 EngineFrictionTorque_W 0;
BA_ "GenSigTimeoutTime_ADCAM" SG_ 262 FuelConsumption_GAG_3 0;
BA_ "GenSigTimeoutTime_EVCU2" SG_ 262 FuelConsumption_GAG_3 0;
BA_ "GenSigTimeoutTime_VDCM" SG_ 262 FuelConsumption_GAG_3 0;
BA_ "GenSigTimeoutTime_ADCAM" SG_ 262 FullOFC_Actv 0;
BA_ "GenSigTimeoutTime_EVCU2" SG_ 262 FullOFC_Actv 0;
BA_ "GenSigTimeoutTime_VDCM" SG_ 262 FullOFC_Actv 0;
BA_ "GenSigTimeoutTime_ADCAM" SG_ 262 AlternatorFail_W 0;
BA_ "GenSigTimeoutTime_EVCU2" SG_ 262 AlternatorFail_W 0;
BA_ "GenSigTimeoutTime_VDCM" SG_ 262 AlternatorFail_W 0;
BA_ "GenSigTimeoutTime_ADCAM" SG_ 262 CrankHold_W 0;
BA_ "GenSigTimeoutTime_EVCU2" SG_ 262 CrankHold_W 0;
BA_ "GenSigTimeoutTime_VDCM" SG_ 262 CrankHold_W 0;
BA_ "GenSigTimeoutTime_ADCAM" SG_ 262 EngFSO_TCM_Allw 0;
BA_ "GenSigTimeoutTime_EVCU2" SG_ 262 EngFSO_TCM_Allw 0;
BA_ "GenSigTimeoutTime_VDCM" SG_ 262 EngFSO_TCM_Allw 0;
BA_ "GenSigTimeoutTime_ADCAM" SG_ 262 StartRelayBCMCmd_W 0;
BA_ "GenSigTimeoutTime_EVCU2" SG_ 262 StartRelayBCMCmd_W 0;
BA_ "GenSigTimeoutTime_VDCM" SG_ 262 StartRelayBCMCmd_W 0;
BA_ "GenSigTimeoutTime_ADCAM" SG_ 262 TRANS_CLU_SLIP_MODE_W 0;
BA_ "GenSigTimeoutTime_EVCU2" SG_ 262 TRANS_CLU_SLIP_MODE_W 0;
BA_ "GenSigTimeoutTime_VDCM" SG_ 262 TRANS_CLU_SLIP_MODE_W 0;
BA_ "GenSigTimeoutTime_ADCAM" SG_ 262 TxAC_EMCC_rq_W 0;
BA_ "GenSigTimeoutTime_EVCU2" SG_ 262 TxAC_EMCC_rq_W 0;
BA_ "GenSigTimeoutTime_VDCM" SG_ 262 TxAC_EMCC_rq_W 0;
BA_ "GenSigTimeoutTime_ADCAM" SG_ 262 ESS_EBOOST_BRKHLD_STATUS 0;
BA_ "GenSigTimeoutTime_EVCU2" SG_ 262 ESS_EBOOST_BRKHLD_STATUS 0;
BA_ "GenSigTimeoutTime_VDCM" SG_ 262 ESS_EBOOST_BRKHLD_STATUS 0;
BA_ "GenSigTimeoutTime_AGSM" SG_ 262 GasPedalPositionFailSts_W 0;
BA_ "GenSigTimeoutTime_ASBS" SG_ 262 GasPedalPositionFailSts_W 0;
BA_ "GenSigTimeoutTime_CADM" SG_ 262 GasPedalPositionFailSts_W 0;
BA_ "GenSigTimeoutTime_DMSM" SG_ 262 GasPedalPositionFailSts_W 0;
BA_ "GenSigTimeoutTime_ECM" SG_ 262 GasPedalPositionFailSts_W 0;
BA_ "GenSigTimeoutTime_ELSDM" SG_ 262 GasPedalPositionFailSts_W 0;
BA_ "GenSigTimeoutTime_ESL" SG_ 262 GasPedalPositionFailSts_W 0;
BA_ "GenSigTimeoutTime_GNMM" SG_ 262 GasPedalPositionFailSts_W 0;
BA_ "GenSigTimeoutTime_IPC" SG_ 262 GasPedalPositionFailSts_W 0;
BA_ "GenSigTimeoutTime_RFHM" SG_ 262 GasPedalPositionFailSts_W 0;
BA_ "GenSigStartValue" SG_ 262 IntakeAirTemperature_W 65;
BA_ "GenSigTimeoutTime_AGSM" SG_ 262 IntakeAirTemperature_W 0;
BA_ "GenSigTimeoutTime_ASBS" SG_ 262 IntakeAirTemperature_W 0;
BA_ "GenSigTimeoutTime_BCM" SG_ 262 IntakeAirTemperature_W 0;
BA_ "GenSigTimeoutTime_BSM" SG_ 262 IntakeAirTemperature_W 0;
BA_ "GenSigTimeoutTime_ADCAM" SG_ 577 QualifyDriveCycle 0;
BA_ "GenSigTimeoutTime_EVCU2" SG_ 577 QualifyDriveCycle 0;
BA_ "GenSigTimeoutTime_VDCM" SG_ 577 QualifyDriveCycle 0;
BA_ "GenSigSendType" SG_ 577 QualifyDriveCycle 3;
BA_ "GenSigTimeoutTime_AGSM" SG_ 577 QualifyDriveCycle 0;
BA_ "GenSigTimeoutTime_ASBS" SG_ 577 QualifyDriveCycle 0;
BA_ "GenSigTimeoutTime_BCM" SG_ 577 QualifyDriveCycle 0;
BA_ "GenSigTimeoutTime_CADM" SG_ 577 QualifyDriveCycle 0;
BA_ "GenSigTimeoutTime_DMSM" SG_ 577 QualifyDriveCycle 0;
BA_ "GenSigTimeoutTime_DTCM" SG_ 577 QualifyDriveCycle 0;
BA_ "GenSigTimeoutTime_ECM" SG_ 577 QualifyDriveCycle 0;
BA_ "GenSigTimeoutTime_ELSDM" SG_ 577 QualifyDriveCycle 0;
BA_ "GenSigTimeoutTime_ESL" SG_ 577 QualifyDriveCycle 0;
BA_ "GenSigTimeoutTime_GNMM" SG_ 577 QualifyDriveCycle 0;
BA_ "GenSigTimeoutTime_IPC" SG_ 577 QualifyDriveCycle 0;
BA_ "GenSigTimeoutTime_RFHM" SG_ 577 QualifyDriveCycle 0;
BA_ "GenSigTimeoutTime_SGW" SG_ 577 QualifyDriveCycle 0;
BA_ "GenSigTimeoutTime_AGSM" SG_ 2564487440 N_PDU_18DAF910 0;
BA_ "GenSigTimeoutTime_ASBS" SG_ 2564487440 N_PDU_18DAF910 0;
BA_ "GenSigTimeoutTime_BCM" SG_ 2564487440 N_PDU_18DAF910 0;
BA_ "GenSigTimeoutTime_BSM" SG_ 2564487440 N_PDU_18DAF910 0;
BA_ "GenSigTimeoutTime_CADM" SG_ 2564487440 N_PDU_18DAF910 0;
BA_ "GenSigTimeoutTime_DMSM" SG_ 2564487440 N_PDU_18DAF910 0;
BA_ "GenSigTimeoutTime_DTCM" SG_ 2564487440 N_PDU_18DAF910 0;
BA_ "GenSigTimeoutTime_ECM" SG_ 2564487440 N_PDU_18DAF910 0;
BA_ "GenSigTimeoutTime_ELSDM" SG_ 2564487440 N_PDU_18DAF910 0;
BA_ "GenSigTimeoutTime_ESL" SG_ 2564487440 N_PDU_18DAF910 0;
BA_ "GenSigTimeoutTime_GNMM" SG_ 2564487440 N_PDU_18DAF910 0;
BA_ "GenSigTimeoutTime_HCP" SG_ 2564487440 N_PDU_18DAF910 0;
BA_ "GenSigTimeoutTime_IPC" SG_ 2564487440 N_PDU_18DAF910 0;
BA_ "GenSigTimeoutTime_RFHM" SG_ 2564487440 N_PDU_18DAF910 0;
BA_ "GenSigTimeoutTime_SGW" SG_ 2564487440 N_PDU_18DAF910 0;
BA_ "GenSigTimeoutTime_TCM" SG_ 2564487440 N_PDU_18DAF910 0;
BA_ "GenSigTimeoutTime_ADCAM" SG_ 2654339073 PreviousCanNMState_FD16_ECM 0;
BA_ "GenSigTimeoutTime_EVCU2" SG_ 2654339073 PreviousCanNMState_FD16_ECM 0;
BA_ "GenSigTimeoutTime_VDCM" SG_ 2654339073 PreviousCanNMState_FD16_ECM 0;
BA_ "GenSigTimeoutTime_ADCAM" SG_ 2654339073 StayActiveSource_FD16_ECM 0;
BA_ "GenSigTimeoutTime_EVCU2" SG_ 2654339073 StayActiveSource_FD16_ECM 0;
BA_ "GenSigTimeoutTime_VDCM" SG_ 2654339073 StayActiveSource_FD16_ECM 0;
BA_ "GenSigTimeoutTime_ADCAM" SG_ 2654339073 WakeupSource_FD16_ECM 0;
BA_ "GenSigTimeoutTime_EVCU2" SG_ 2654339073 WakeupSource_FD16_ECM 0;
BA_ "GenSigTimeoutTime_VDCM" SG_ 2654339073 WakeupSource_FD16_ECM 0;
BA_ "GenSigTimeoutTime_ADCAM" SG_ 2654339073 StayActiveSource_FD03_ECM 0;
BA_ "GenSigTimeoutTime_EVCU2" SG_ 2654339073 StayActiveSource_FD03_ECM 0;
BA_ "GenSigTimeoutTime_VDCM" SG_ 2654339073 StayActiveSource_FD03_ECM 0;
BA_ "GenSigTimeoutTime_ADCAM" SG_ 2654339073 CurrentCanNMState_FD03_ECM 0;
BA_ "GenSigTimeoutTime_EVCU2" SG_ 2654339073 CurrentCanNMState_FD03_ECM 0;
BA_ "GenSigTimeoutTime_VDCM" SG_ 2654339073 CurrentCanNMState_FD03_ECM 0;
BA_ "GenSigTimeoutTime_ADCAM" SG_ 2654339073 PreviousCanNMState_FD03_ECM 0;
BA_ "GenSigTimeoutTime_EVCU2" SG_ 2654339073 PreviousCanNMState_FD03_ECM 0;
BA_ "GenSigTimeoutTime_VDCM" SG_ 2654339073 PreviousCanNMState_FD03_ECM 0;
BA_ "GenSigTimeoutTime_ADCAM" SG_ 2654339073 DES_FD03_ECM 0;
BA_ "GenSigTimeoutTime_EVCU2" SG_ 2654339073 DES_FD03_ECM 0;
BA_ "GenSigTimeoutTime_VDCM" SG_ 2654339073 DES_FD03_ECM 0;
BA_ "GenSigTimeoutTime_ADCAM" SG_ 2654339073 DES_FD16_ECM 0;
BA_ "GenSigTimeoutTime_EVCU2" SG_ 2654339073 DES_FD16_ECM 0;
BA_ "GenSigTimeoutTime_VDCM" SG_ 2654339073 DES_FD16_ECM 0;
BA_ "GenSigTimeoutTime_ADCAM" SG_ 2654339073 CurrentCanNMState_FD16_ECM 0;
BA_ "GenSigTimeoutTime_EVCU2" SG_ 2654339073 CurrentCanNMState_FD16_ECM 0;
BA_ "GenSigTimeoutTime_VDCM" SG_ 2654339073 CurrentCanNMState_FD16_ECM 0;
BA_ "GenSigTimeoutTime_ADCAM" SG_ 2654339073 CurrentFailSts_FD16_ECM 0;
BA_ "GenSigTimeoutTime_EVCU2" SG_ 2654339073 CurrentFailSts_FD16_ECM 0;
BA_ "GenSigTimeoutTime_VDCM" SG_ 2654339073 CurrentFailSts_FD16_ECM 0;
BA_ "GenSigTimeoutTime_ADCAM" SG_ 2654339073 EOL_FD16_ECM 0;
BA_ "GenSigTimeoutTime_EVCU2" SG_ 2654339073 EOL_FD16_ECM 0;
BA_ "GenSigTimeoutTime_VDCM" SG_ 2654339073 EOL_FD16_ECM 0;
BA_ "GenSigTimeoutTime_ADCAM" SG_ 2654339073 GenericFailSts_FD16_ECM 0;
BA_ "GenSigTimeoutTime_EVCU2" SG_ 2654339073 GenericFailSts_FD16_ECM 0;
BA_ "GenSigTimeoutTime_VDCM" SG_ 2654339073 GenericFailSts_FD16_ECM 0;
BA_ "GenSigTimeoutTime_ADCAM" SG_ 2654339073 WakeupSource_FD03_ECM 0;
BA_ "GenSigTimeoutTime_EVCU2" SG_ 2654339073 WakeupSource_FD03_ECM 0;
BA_ "GenSigTimeoutTime_VDCM" SG_ 2654339073 WakeupSource_FD03_ECM 0;
BA_ "GenSigTimeoutTime_ADCAM" SG_ 2654339073 CurrentFailSts_FD03_ECM 0;
BA_ "GenSigTimeoutTime_EVCU2" SG_ 2654339073 CurrentFailSts_FD03_ECM 0;
BA_ "GenSigTimeoutTime_VDCM" SG_ 2654339073 CurrentFailSts_FD03_ECM 0;
BA_ "GenSigTimeoutTime_ADCAM" SG_ 2654339073 EOL_FD03_ECM 0;
BA_ "GenSigTimeoutTime_EVCU2" SG_ 2654339073 EOL_FD03_ECM 0;
BA_ "GenSigTimeoutTime_VDCM" SG_ 2654339073 EOL_FD03_ECM 0;
BA_ "GenSigTimeoutTime_ADCAM" SG_ 2654339073 GenericFailSts_FD03_ECM 0;
BA_ "GenSigTimeoutTime_EVCU2" SG_ 2654339073 GenericFailSts_FD03_ECM 0;
BA_ "GenSigTimeoutTime_VDCM" SG_ 2654339073 GenericFailSts_FD03_ECM 0;
BA_ "GenSigTimeoutTime_AGSM" SG_ 2654339073 PreviousCanNMState_FD16_ECM 0;
BA_ "GenSigTimeoutTime_ASBS" SG_ 2654339073 PreviousCanNMState_FD16_ECM 0;
BA_ "GenSigTimeoutTime_BCM" SG_ 2654339073 PreviousCanNMState_FD16_ECM 0;
BA_ "GenSigTimeoutTime_BSM" SG_ 2654339073 PreviousCanNMState_FD16_ECM 0;
BA_ "GenSigTimeoutTime_CADM" SG_ 2654339073 PreviousCanNMState_FD16_ECM 0;
BA_ "GenSigTimeoutTime_DMSM" SG_ 2654339073 PreviousCanNMState_FD16_ECM 0;
BA_ "GenSigTimeoutTime_DTCM" SG_ 2654339073 PreviousCanNMState_FD16_ECM 0;
BA_ "GenSigTimeoutTime_ECM" SG_ 2654339073 PreviousCanNMState_FD16_ECM 0;
BA_ "GenSigTimeoutTime_ELSDM" SG_ 2654339073 PreviousCanNMState_FD16_ECM 0;
BA_ "GenSigTimeoutTime_ESL" SG_ 2654339073 PreviousCanNMState_FD16_ECM 0;
BA_ "GenSigTimeoutTime_GNMM" SG_ 2654339073 PreviousCanNMState_FD16_ECM 0;
BA_ "GenSigTimeoutTime_HCP" SG_ 2654339073 PreviousCanNMState_FD16_ECM 0;
BA_ "GenSigTimeoutTime_IPC" SG_ 2654339073 PreviousCanNMState_FD16_ECM 0;
BA_ "GenSigTimeoutTime_RFHM" SG_ 2654339073 PreviousCanNMState_FD16_ECM 0;
BA_ "GenSigTimeoutTime_TCM" SG_ 2654339073 PreviousCanNMState_FD16_ECM 0;
BA_ "GenSigTimeoutTime_AGSM" SG_ 2654339073 StayActiveSource_FD16_ECM 0;
BA_ "GenSigTimeoutTime_ASBS" SG_ 2654339073 StayActiveSource_FD16_ECM 0;
BA_ "GenSigTimeoutTime_BCM" SG_ 2654339073 StayActiveSource_FD16_ECM 0;
BA_ "GenSigTimeoutTime_BSM" SG_ 2654339073 StayActiveSource_FD16_ECM 0;
BA_ "GenSigTimeoutTime_CADM" SG_ 2654339073 StayActiveSource_FD16_ECM 0;
BA_ "GenSigTimeoutTime_DMSM" SG_ 2654339073 StayActiveSource_FD16_ECM 0;
BA_ "GenSigTimeoutTime_DTCM" SG_ 2654339073 StayActiveSource_FD16_ECM 0;
BA_ "GenSigTimeoutTime_ECM" SG_ 2654339073 StayActiveSource_FD16_ECM 0;
BA_ "GenSigTimeoutTime_ELSDM" SG_ 2654339073 StayActiveSource_FD16_ECM 0;
BA_ "GenSigTimeoutTime_ESL" SG_ 2654339073 StayActiveSource_FD16_ECM 0;
BA_ "GenSigTimeoutTime_GNMM" SG_ 2654339073 StayActiveSource_FD16_ECM 0;
BA_ "GenSigTimeoutTime_HCP" SG_ 2654339073 StayActiveSource_FD16_ECM 0;
BA_ "GenSigTimeoutTime_IPC" SG_ 2654339073 StayActiveSource_FD16_ECM 0;
BA_ "GenSigTimeoutTime_RFHM" SG_ 2654339073 StayActiveSource_FD16_ECM 0;
BA_ "GenSigTimeoutTime_TCM" SG_ 2654339073 StayActiveSource_FD16_ECM 0;
BA_ "GenSigTimeoutTime_AGSM" SG_ 2654339073 WakeupSource_FD16_ECM 0;
BA_ "GenSigTimeoutTime_ASBS" SG_ 2654339073 WakeupSource_FD16_ECM 0;
BA_ "GenSigTimeoutTime_BCM" SG_ 2654339073 WakeupSource_FD16_ECM 0;
BA_ "GenSigTimeoutTime_BSM" SG_ 2654339073 WakeupSource_FD16_ECM 0;
BA_ "GenSigTimeoutTime_CADM" SG_ 2654339073 WakeupSource_FD16_ECM 0;
BA_ "GenSigTimeoutTime_DMSM" SG_ 2654339073 WakeupSource_FD16_ECM 0;
BA_ "GenSigTimeoutTime_DTCM" SG_ 2654339073 WakeupSource_FD16_ECM 0;
BA_ "GenSigTimeoutTime_ECM" SG_ 2654339073 WakeupSource_FD16_ECM 0;
BA_ "GenSigTimeoutTime_ELSDM" SG_ 2654339073 WakeupSource_FD16_ECM 0;
BA_ "GenSigTimeoutTime_ESL" SG_ 2654339073 WakeupSource_FD16_ECM 0;
BA_ "GenSigTimeoutTime_GNMM" SG_ 2654339073 WakeupSource_FD16_ECM 0;
BA_ "GenSigTimeoutTime_HCP" SG_ 2654339073 WakeupSource_FD16_ECM 0;
BA_ "GenSigTimeoutTime_IPC" SG_ 2654339073 WakeupSource_FD16_ECM 0;
BA_ "GenSigTimeoutTime_RFHM" SG_ 2654339073 WakeupSource_FD16_ECM 0;
BA_ "GenSigTimeoutTime_TCM" SG_ 2654339073 WakeupSource_FD16_ECM 0;
BA_ "GenSigTimeoutTime_AGSM" SG_ 2654339073 StayActiveSource_FD03_ECM 0;
BA_ "GenSigTimeoutTime_ASBS" SG_ 2654339073 StayActiveSource_FD03_ECM 0;
BA_ "GenSigTimeoutTime_BCM" SG_ 2654339073 StayActiveSource_FD03_ECM 0;
BA_ "GenSigTimeoutTime_BSM" SG_ 2654339073 StayActiveSource_FD03_ECM 0;
BA_ "GenSigTimeoutTime_CADM" SG_ 2654339073 StayActiveSource_FD03_ECM 0;
BA_ "GenSigTimeoutTime_DMSM" SG_ 2654339073 StayActiveSource_FD03_ECM 0;
BA_ "GenSigTimeoutTime_DTCM" SG_ 2654339073 StayActiveSource_FD03_ECM 0;
BA_ "GenSigTimeoutTime_ECM" SG_ 2654339073 StayActiveSource_FD03_ECM 0;
BA_ "GenSigTimeoutTime_ELSDM" SG_ 2654339073 StayActiveSource_FD03_ECM 0;
BA_ "GenSigTimeoutTime_ESL" SG_ 2654339073 StayActiveSource_FD03_ECM 0;
BA_ "GenSigTimeoutTime_GNMM" SG_ 2654339073 StayActiveSource_FD03_ECM 0;
BA_ "GenSigTimeoutTime_HCP" SG_ 2654339073 StayActiveSource_FD03_ECM 0;
BA_ "GenSigTimeoutTime_IPC" SG_ 2654339073 StayActiveSource_FD03_ECM 0;
BA_ "GenSigTimeoutTime_RFHM" SG_ 2654339073 StayActiveSource_FD03_ECM 0;
BA_ "GenSigTimeoutTime_TCM" SG_ 2654339073 StayActiveSource_FD03_ECM 0;
BA_ "GenSigTimeoutTime_AGSM" SG_ 2654339073 CurrentCanNMState_FD03_ECM 0;
BA_ "GenSigTimeoutTime_ASBS" SG_ 2654339073 CurrentCanNMState_FD03_ECM 0;
BA_ "GenSigTimeoutTime_BCM" SG_ 2654339073 CurrentCanNMState_FD03_ECM 0;
BA_ "GenSigTimeoutTime_BSM" SG_ 2654339073 CurrentCanNMState_FD03_ECM 0;
BA_ "GenSigTimeoutTime_CADM" SG_ 2654339073 CurrentCanNMState_FD03_ECM 0;
BA_ "GenSigTimeoutTime_DMSM" SG_ 2654339073 CurrentCanNMState_FD03_ECM 0;
BA_ "GenSigTimeoutTime_DTCM" SG_ 2654339073 CurrentCanNMState_FD03_ECM 0;
BA_ "GenSigTimeoutTime_ECM" SG_ 2654339073 CurrentCanNMState_FD03_ECM 0;
BA_ "GenSigTimeoutTime_ELSDM" SG_ 2654339073 CurrentCanNMState_FD03_ECM 0;
BA_ "GenSigTimeoutTime_ESL" SG_ 2654339073 CurrentCanNMState_FD03_ECM 0;
BA_ "GenSigTimeoutTime_GNMM" SG_ 2654339073 CurrentCanNMState_FD03_ECM 0;
BA_ "GenSigTimeoutTime_HCP" SG_ 2654339073 CurrentCanNMState_FD03_ECM 0;
BA_ "GenSigTimeoutTime_IPC" SG_ 2654339073 CurrentCanNMState_FD03_ECM 0;
BA_ "GenSigTimeoutTime_RFHM" SG_ 2654339073 CurrentCanNMState_FD03_ECM 0;
BA_ "GenSigTimeoutTime_TCM" SG_ 2654339073 CurrentCanNMState_FD03_ECM 0;
BA_ "GenSigTimeoutTime_AGSM" SG_ 2654339073 PreviousCanNMState_FD03_ECM 0;
BA_ "GenSigTimeoutTime_ASBS" SG_ 2654339073 PreviousCanNMState_FD03_ECM 0;
BA_ "GenSigTimeoutTime_BCM" SG_ 2654339073 PreviousCanNMState_FD03_ECM 0;
BA_ "GenSigTimeoutTime_BSM" SG_ 2654339073 PreviousCanNMState_FD03_ECM 0;
BA_ "GenSigTimeoutTime_CADM" SG_ 2654339073 PreviousCanNMState_FD03_ECM 0;
BA_ "GenSigTimeoutTime_DMSM" SG_ 2654339073 PreviousCanNMState_FD03_ECM 0;
BA_ "GenSigTimeoutTime_HCP" SG_ 258 BrakePedalPressure 0;
BA_ "GenSigTimeoutTime_ADCAM" SG_ 2654486592 CBV_bit0_RepeatMessageRequestBit_1E384040 0;
BA_ "GenSigTimeoutTime_EVCU2" SG_ 2654486592 CBV_bit0_RepeatMessageRequestBit_1E384040 0;
BA_ "GenSigTimeoutTime_VDCM" SG_ 2654486592 CBV_bit0_RepeatMessageRequestBit_1E384040 0;
BA_ "GenSigTimeoutTime_AGSM" SG_ 2654486592 CBV_bit0_RepeatMessageRequestBit_1E384040 0;
BA_ "GenSigTimeoutTime_BCM" SG_ 2654486592 CBV_bit0_RepeatMessageRequestBit_1E384040 0;
BA_ "GenSigTimeoutTime_BSM" SG_ 2654486592 CBV_bit0_RepeatMessageRequestBit_1E384040 0;
BA_ "GenSigTimeoutTime_DTCM" SG_ 2654486592 CBV_bit0_RepeatMessageRequestBit_1E384040 0;
BA_ "GenSigTimeoutTime_ECM" SG_ 2654486592 CBV_bit0_RepeatMessageRequestBit_1E384040 0;
BA_ "GenSigTimeoutTime_ESL" SG_ 2654486592 CBV_bit0_RepeatMessageRequestBit_1E384040 0;
BA_ "GenSigTimeoutTime_IPC" SG_ 2654486592 CBV_bit0_RepeatMessageRequestBit_1E384040 0;
BA_ "GenSigTimeoutTime_RFHM" SG_ 2654486592 CBV_bit0_RepeatMessageRequestBit_1E384040 0;
BA_ "GenSigTimeoutTime_SGW" SG_ 2654486592 CBV_bit0_RepeatMessageRequestBit_1E384040 0;
BA_ "GenSigTimeoutTime_TCM" SG_ 2654486592 CBV_bit0_RepeatMessageRequestBit_1E384040 0;
BA_ "GenSigTimeoutTime_ADCAM" SG_ 2654486592 CBV_bit1_1E384040 0;
BA_ "GenSigTimeoutTime_EVCU2" SG_ 2654486592 CBV_bit1_1E384040 0;
BA_ "GenSigTimeoutTime_VDCM" SG_ 2654486592 CBV_bit1_1E384040 0;
BA_ "GenSigTimeoutTime_AGSM" SG_ 2654486592 CBV_bit1_1E384040 0;
BA_ "GenSigTimeoutTime_BCM" SG_ 2654486592 CBV_bit1_1E384040 0;
BA_ "GenSigTimeoutTime_BSM" SG_ 2654486592 CBV_bit1_1E384040 0;
BA_ "GenSigTimeoutTime_DTCM" SG_ 2654486592 CBV_bit1_1E384040 0;
BA_ "GenSigTimeoutTime_ECM" SG_ 2654486592 CBV_bit1_1E384040 0;
BA_ "GenSigTimeoutTime_ESL" SG_ 2654486592 CBV_bit1_1E384040 0;
BA_ "GenSigTimeoutTime_IPC" SG_ 2654486592 CBV_bit1_1E384040 0;
BA_ "GenSigTimeoutTime_RFHM" SG_ 2654486592 CBV_bit1_1E384040 0;
BA_ "GenSigTimeoutTime_SGW" SG_ 2654486592 CBV_bit1_1E384040 0;
BA_ "GenSigTimeoutTime_TCM" SG_ 2654486592 CBV_bit1_1E384040 0;
BA_ "GenSigTimeoutTime_ADCAM" SG_ 2654486592 CBV_bit2_1E384040 0;
BA_ "GenSigTimeoutTime_EVCU2" SG_ 2654486592 CBV_bit2_1E384040 0;
BA_ "GenSigTimeoutTime_VDCM" SG_ 2654486592 CBV_bit2_1E384040 0;
BA_ "GenSigTimeoutTime_AGSM" SG_ 2654486592 CBV_bit2_1E384040 0;
BA_ "GenSigTimeoutTime_BCM" SG_ 2654486592 CBV_bit2_1E384040 0;
BA_ "GenSigTimeoutTime_BSM" SG_ 2654486592 CBV_bit2_1E384040 0;
BA_ "GenSigTimeoutTime_DTCM" SG_ 2654486592 CBV_bit2_1E384040 0;
BA_ "GenSigTimeoutTime_ECM" SG_ 2654486592 CBV_bit2_1E384040 0;
BA_ "GenSigTimeoutTime_ESL" SG_ 2654486592 CBV_bit2_1E384040 0;
BA_ "GenSigTimeoutTime_IPC" SG_ 2654486592 CBV_bit2_1E384040 0;
BA_ "GenSigTimeoutTime_RFHM" SG_ 2654486592 CBV_bit2_1E384040 0;
BA_ "GenSigTimeoutTime_SGW" SG_ 2654486592 CBV_bit2_1E384040 0;
BA_ "GenSigTimeoutTime_TCM" SG_ 2654486592 CBV_bit2_1E384040 0;
BA_ "GenSigTimeoutTime_ADCAM" SG_ 2654486592 CBV_bit3_NMCoordinatorBit_1E384040 0;
BA_ "GenSigTimeoutTime_EVCU2" SG_ 2654486592 CBV_bit3_NMCoordinatorBit_1E384040 0;
BA_ "GenSigTimeoutTime_VDCM" SG_ 2654486592 CBV_bit3_NMCoordinatorBit_1E384040 0;
BA_ "GenSigTimeoutTime_AGSM" SG_ 2654486592 CBV_bit3_NMCoordinatorBit_1E384040 0;
BA_ "GenSigTimeoutTime_BCM" SG_ 2654486592 CBV_bit3_NMCoordinatorBit_1E384040 0;
BA_ "GenSigTimeoutTime_BSM" SG_ 2654486592 CBV_bit3_NMCoordinatorBit_1E384040 0;
BA_ "GenSigTimeoutTime_DTCM" SG_ 2654486592 CBV_bit3_NMCoordinatorBit_1E384040 0;
BA_ "GenSigTimeoutTime_ECM" SG_ 2654486592 CBV_bit3_NMCoordinatorBit_1E384040 0;
BA_ "GenSigTimeoutTime_ESL" SG_ 2654486592 CBV_bit3_NMCoordinatorBit_1E384040 0;
BA_ "GenSigTimeoutTime_IPC" SG_ 2654486592 CBV_bit3_NMCoordinatorBit_1E384040 0;
BA_ "GenSigTimeoutTime_RFHM" SG_ 2654486592 CBV_bit3_NMCoordinatorBit_1E384040 0;
BA_ "GenSigTimeoutTime_SGW" SG_ 2654486592 CBV_bit3_NMCoordinatorBit_1E384040 0;
BA_ "GenSigTimeoutTime_TCM" SG_ 2654486592 CBV_bit3_NMCoordinatorBit_1E384040 0;
BA_ "GenSigTimeoutTime_ADCAM" SG_ 2654486592 CBV_bit4_ActiveWakeupBit_1E384040 0;
BA_ "GenSigTimeoutTime_EVCU2" SG_ 2654486592 CBV_bit4_ActiveWakeupBit_1E384040 0;
BA_ "GenSigTimeoutTime_VDCM" SG_ 2654486592 CBV_bit4_ActiveWakeupBit_1E384040 0;
BA_ "GenSigTimeoutTime_AGSM" SG_ 2654486592 CBV_bit4_ActiveWakeupBit_1E384040 0;
BA_ "GenSigTimeoutTime_BCM" SG_ 2654486592 CBV_bit4_ActiveWakeupBit_1E384040 0;
BA_ "GenSigTimeoutTime_BSM" SG_ 2654486592 CBV_bit4_ActiveWakeupBit_1E384040 0;
BA_ "GenSigTimeoutTime_DTCM" SG_ 2654486592 CBV_bit4_ActiveWakeupBit_1E384040 0;
BA_ "GenSigTimeoutTime_ECM" SG_ 2654486592 CBV_bit4_ActiveWakeupBit_1E384040 0;
BA_ "GenSigTimeoutTime_ESL" SG_ 2654486592 CBV_bit4_ActiveWakeupBit_1E384040 0;
BA_ "GenSigTimeoutTime_IPC" SG_ 2654486592 CBV_bit4_ActiveWakeupBit_1E384040 0;
BA_ "GenSigTimeoutTime_RFHM" SG_ 2654486592 CBV_bit4_ActiveWakeupBit_1E384040 0;
BA_ "GenSigTimeoutTime_SGW" SG_ 2654486592 CBV_bit4_ActiveWakeupBit_1E384040 0;
BA_ "GenSigTimeoutTime_TCM" SG_ 2654486592 CBV_bit4_ActiveWakeupBit_1E384040 0;
BA_ "GenSigTimeoutTime_ADCAM" SG_ 2654486592 CBV_bit5_1E384040 0;
BA_ "GenSigTimeoutTime_EVCU2" SG_ 2654486592 CBV_bit5_1E384040 0;
BA_ "GenSigTimeoutTime_VDCM" SG_ 2654486592 CBV_bit5_1E384040 0;
BA_ "GenSigTimeoutTime_AGSM" SG_ 2654486592 CBV_bit5_1E384040 0;
BA_ "GenSigTimeoutTime_BCM" SG_ 2654486592 CBV_bit5_1E384040 0;
BA_ "GenSigTimeoutTime_BSM" SG_ 2654486592 CBV_bit5_1E384040 0;
BA_ "GenSigTimeoutTime_DTCM" SG_ 2654486592 CBV_bit5_1E384040 0;
BA_ "GenSigTimeoutTime_ECM" SG_ 2654486592 CBV_bit5_1E384040 0;
BA_ "GenSigTimeoutTime_ESL" SG_ 2654486592 CBV_bit5_1E384040 0;
BA_ "GenSigTimeoutTime_IPC" SG_ 2654486592 CBV_bit5_1E384040 0;
BA_ "GenSigTimeoutTime_RFHM" SG_ 2654486592 CBV_bit5_1E384040 0;
BA_ "GenSigTimeoutTime_SGW" SG_ 2654486592 CBV_bit5_1E384040 0;
BA_ "GenSigTimeoutTime_TCM" SG_ 2654486592 CBV_bit5_1E384040 0;
BA_ "GenSigTimeoutTime_ADCAM" SG_ 2654486592 CBV_bit6_PartialNtwInfBit_1E384040 0;
BA_ "GenSigTimeoutTime_EVCU2" SG_ 2654486592 CBV_bit6_PartialNtwInfBit_1E384040 0;
BA_ "GenSigTimeoutTime_VDCM" SG_ 2654486592 CBV_bit6_PartialNtwInfBit_1E384040 0;
BA_ "GenSigTimeoutTime_AGSM" SG_ 2654486592 CBV_bit6_PartialNtwInfBit_1E384040 0;
BA_ "GenSigTimeoutTime_BCM" SG_ 2654486592 CBV_bit6_PartialNtwInfBit_1E384040 0;
BA_ "GenSigTimeoutTime_BSM" SG_ 2654486592 CBV_bit6_PartialNtwInfBit_1E384040 0;
BA_ "GenSigTimeoutTime_DTCM" SG_ 2654486592 CBV_bit6_PartialNtwInfBit_1E384040 0;
BA_ "GenSigTimeoutTime_ECM" SG_ 2654486592 CBV_bit6_PartialNtwInfBit_1E384040 0;
BA_ "GenSigTimeoutTime_ESL" SG_ 2654486592 CBV_bit6_PartialNtwInfBit_1E384040 0;
BA_ "GenSigTimeoutTime_IPC" SG_ 2654486592 CBV_bit6_PartialNtwInfBit_1E384040 0;
BA_ "GenSigTimeoutTime_RFHM" SG_ 2654486592 CBV_bit6_PartialNtwInfBit_1E384040 0;
BA_ "GenSigTimeoutTime_SGW" SG_ 2654486592 CBV_bit6_PartialNtwInfBit_1E384040 0;
BA_ "GenSigTimeoutTime_TCM" SG_ 2654486592 CBV_bit6_PartialNtwInfBit_1E384040 0;
BA_ "GenSigTimeoutTime_ADCAM" SG_ 2654486592 CBV_bit7_1E384040 0;
BA_ "GenSigTimeoutTime_EVCU2" SG_ 2654486592 CBV_bit7_1E384040 0;
BA_ "GenSigTimeoutTime_VDCM" SG_ 2654486592 CBV_bit7_1E384040 0;
BA_ "GenSigTimeoutTime_AGSM" SG_ 2654486592 CBV_bit7_1E384040 0;
BA_ "GenSigTimeoutTime_BCM" SG_ 2654486592 CBV_bit7_1E384040 0;
BA_ "GenSigTimeoutTime_BSM" SG_ 2654486592 CBV_bit7_1E384040 0;
BA_ "GenSigTimeoutTime_DTCM" SG_ 2654486592 CBV_bit7_1E384040 0;
BA_ "GenSigTimeoutTime_ECM" SG_ 2654486592 CBV_bit7_1E384040 0;
BA_ "GenSigTimeoutTime_ESL" SG_ 2654486592 CBV_bit7_1E384040 0;
BA_ "GenSigTimeoutTime_IPC" SG_ 2654486592 CBV_bit7_1E384040 0;
BA_ "GenSigTimeoutTime_RFHM" SG_ 2654486592 CBV_bit7_1E384040 0;
BA_ "GenSigTimeoutTime_SGW" SG_ 2654486592 CBV_bit7_1E384040 0;
BA_ "GenSigTimeoutTime_TCM" SG_ 2654486592 CBV_bit7_1E384040 0;
BA_ "GenSigTimeoutTime_ADCAM" SG_ 2654486592 SourceNodeIdentifier_1E384040 0;
BA_ "GenSigTimeoutTime_EVCU2" SG_ 2654486592 SourceNodeIdentifier_1E384040 0;
BA_ "GenSigTimeoutTime_VDCM" SG_ 2654486592 SourceNodeIdentifier_1E384040 0;
BA_ "GenSigTimeoutTime_AGSM" SG_ 2654486592 SourceNodeIdentifier_1E384040 0;
BA_ "GenSigTimeoutTime_BCM" SG_ 2654486592 SourceNodeIdentifier_1E384040 0;
BA_ "GenSigTimeoutTime_BSM" SG_ 2654486592 SourceNodeIdentifier_1E384040 0;
BA_ "GenSigTimeoutTime_DTCM" SG_ 2654486592 SourceNodeIdentifier_1E384040 0;
BA_ "GenSigTimeoutTime_ECM" SG_ 2654486592 SourceNodeIdentifier_1E384040 0;
BA_ "GenSigTimeoutTime_ESL" SG_ 2654486592 SourceNodeIdentifier_1E384040 0;
BA_ "GenSigTimeoutTime_IPC" SG_ 2654486592 SourceNodeIdentifier_1E384040 0;
BA_ "GenSigTimeoutTime_RFHM" SG_ 2654486592 SourceNodeIdentifier_1E384040 0;
BA_ "GenSigTimeoutTime_SGW" SG_ 2654486592 SourceNodeIdentifier_1E384040 0;
BA_ "GenSigTimeoutTime_TCM" SG_ 2654486592 SourceNodeIdentifier_1E384040 0;
BA_ "GenSigTimeoutTime_EVCU2" SG_ 263 CRC_PT_SYSTEM_FD_1 0;
BA_ "GenSigTimeoutTime_VDCM" SG_ 263 CRC_PT_SYSTEM_FD_1 0;
BA_ "GenSigTimeoutTime_BCM" SG_ 263 CRC_PT_SYSTEM_FD_1 0;
BA_ "GenSigTimeoutTime_DTCM" SG_ 263 CRC_PT_SYSTEM_FD_1 0;
BA_ "GenSigTimeoutTime_ESL" SG_ 263 CRC_PT_SYSTEM_FD_1 0;
BA_ "GenSigTimeoutTime_RFHM" SG_ 263 CRC_PT_SYSTEM_FD_1 0;
BA_ "GenSigTimeoutTime_TCM" SG_ 263 CRC_PT_SYSTEM_FD_1 0;
BA_ "GenSigTimeoutTime_EVCU2" SG_ 263 MessageCounter_PT_SYSTEM_FD_1 0;
BA_ "GenSigTimeoutTime_VDCM" SG_ 263 MessageCounter_PT_SYSTEM_FD_1 0;
BA_ "GenSigTimeoutTime_BCM" SG_ 263 MessageCounter_PT_SYSTEM_FD_1 0;
BA_ "GenSigTimeoutTime_DTCM" SG_ 263 MessageCounter_PT_SYSTEM_FD_1 0;
BA_ "GenSigTimeoutTime_ESL" SG_ 263 MessageCounter_PT_SYSTEM_FD_1 0;
BA_ "GenSigTimeoutTime_RFHM" SG_ 263 MessageCounter_PT_SYSTEM_FD_1 0;
BA_ "GenSigTimeoutTime_TCM" SG_ 263 MessageCounter_PT_SYSTEM_FD_1 0;
BA_ "GenSigTimeoutTime_EVCU2" SG_ 263 GearEngagedForDisplay_PT 0;
BA_ "GenSigTimeoutTime_VDCM" SG_ 263 GearEngagedForDisplay_PT 0;
BA_ "GenSigTimeoutTime_DTCM" SG_ 263 GearEngagedForDisplay_PT 0;
BA_ "GenSigTimeoutTime_ESL" SG_ 263 GearEngagedForDisplay_PT 0;
BA_ "GenSigTimeoutTime_TCM" SG_ 263 GearEngagedForDisplay_PT 0;
BA_ "GenSigTimeoutTime_EVCU2" SG_ 263 PowertrainPrplsnActv_PT 0;
BA_ "GenSigTimeoutTime_AGSM" SG_ 263 PowertrainPrplsnActv_PT 0;
BA_ "GenSigTimeoutTime_DTCM" SG_ 263 PowertrainPrplsnActv_PT 0;
BA_ "GenSigTimeoutTime_ESL" SG_ 263 PowertrainPrplsnActv_PT 0;
BA_ "GenSigTimeoutTime_TCM" SG_ 263 PowertrainPrplsnActv_PT 0;
BA_ "GenSigTimeoutTime_ADCAM" SG_ 2654486689 CBV_bit0_RepeatMessageRequestBit_1E3840A1 0;
BA_ "GenSigTimeoutTime_EVCU2" SG_ 2654486689 CBV_bit0_RepeatMessageRequestBit_1E3840A1 0;
BA_ "GenSigTimeoutTime_VDCM" SG_ 2654486689 CBV_bit0_RepeatMessageRequestBit_1E3840A1 0;
BA_ "GenSigTimeoutTime_AGSM" SG_ 2654486689 CBV_bit0_RepeatMessageRequestBit_1E3840A1 0;
BA_ "GenSigTimeoutTime_BCM" SG_ 2654486689 CBV_bit0_RepeatMessageRequestBit_1E3840A1 0;
BA_ "GenSigTimeoutTime_BSM" SG_ 2654486689 CBV_bit0_RepeatMessageRequestBit_1E3840A1 0;
BA_ "GenSigTimeoutTime_DTCM" SG_ 2654486689 CBV_bit0_RepeatMessageRequestBit_1E3840A1 0;
BA_ "GenSigTimeoutTime_ECM" SG_ 2654486689 CBV_bit0_RepeatMessageRequestBit_1E3840A1 0;
BA_ "GenSigTimeoutTime_ESL" SG_ 2654486689 CBV_bit0_RepeatMessageRequestBit_1E3840A1 0;
BA_ "GenSigTimeoutTime_IPC" SG_ 2654486689 CBV_bit0_RepeatMessageRequestBit_1E3840A1 0;
BA_ "GenSigTimeoutTime_RFHM" SG_ 2654486689 CBV_bit0_RepeatMessageRequestBit_1E3840A1 0;
BA_ "GenSigTimeoutTime_SGW" SG_ 2654486689 CBV_bit0_RepeatMessageRequestBit_1E3840A1 0;
BA_ "GenSigTimeoutTime_TCM" SG_ 2654486689 CBV_bit0_RepeatMessageRequestBit_1E3840A1 0;
BA_ "GenSigTimeoutTime_ADCAM" SG_ 2654486689 CBV_bit3_NMCoordinatorBit_1E3840A1 0;
BA_ "GenSigTimeoutTime_EVCU2" SG_ 2654486689 CBV_bit3_NMCoordinatorBit_1E3840A1 0;
BA_ "GenSigTimeoutTime_VDCM" SG_ 2654486689 CBV_bit3_NMCoordinatorBit_1E3840A1 0;
BA_ "GenSigTimeoutTime_AGSM" SG_ 2654486689 CBV_bit3_NMCoordinatorBit_1E3840A1 0;
BA_ "GenSigTimeoutTime_BCM" SG_ 2654486689 CBV_bit3_NMCoordinatorBit_1E3840A1 0;
BA_ "GenSigTimeoutTime_BSM" SG_ 2654486689 CBV_bit3_NMCoordinatorBit_1E3840A1 0;
BA_ "GenSigTimeoutTime_DTCM" SG_ 2654486689 CBV_bit3_NMCoordinatorBit_1E3840A1 0;
BA_ "GenSigTimeoutTime_ECM" SG_ 2654486689 CBV_bit3_NMCoordinatorBit_1E3840A1 0;
BA_ "GenSigTimeoutTime_ESL" SG_ 2654486689 CBV_bit3_NMCoordinatorBit_1E3840A1 0;
BA_ "GenSigTimeoutTime_IPC" SG_ 2654486689 CBV_bit3_NMCoordinatorBit_1E3840A1 0;
BA_ "GenSigTimeoutTime_RFHM" SG_ 2654486689 CBV_bit3_NMCoordinatorBit_1E3840A1 0;
BA_ "GenSigTimeoutTime_SGW" SG_ 2654486689 CBV_bit3_NMCoordinatorBit_1E3840A1 0;
BA_ "GenSigTimeoutTime_TCM" SG_ 2654486689 CBV_bit3_NMCoordinatorBit_1E3840A1 0;
BA_ "GenSigTimeoutTime_ADCAM" SG_ 2654486689 CBV_bit4_ActiveWakeupBit_1E3840A1 0;
BA_ "GenSigTimeoutTime_EVCU2" SG_ 2654486689 CBV_bit4_ActiveWakeupBit_1E3840A1 0;
BA_ "GenSigTimeoutTime_VDCM" SG_ 2654486689 CBV_bit4_ActiveWakeupBit_1E3840A1 0;
BA_ "GenSigTimeoutTime_AGSM" SG_ 2654486689 CBV_bit4_ActiveWakeupBit_1E3840A1 0;
BA_ "GenSigTimeoutTime_BCM" SG_ 2654486689 CBV_bit4_ActiveWakeupBit_1E3840A1 0;
BA_ "GenSigTimeoutTime_BSM" SG_ 2654486689 CBV_bit4_ActiveWakeupBit_1E3840A1 0;
BA_ "GenSigTimeoutTime_DTCM" SG_ 2654486689 CBV_bit4_ActiveWakeupBit_1E3840A1 0;
BA_ "GenSigTimeoutTime_ECM" SG_ 2654486689 CBV_bit4_ActiveWakeupBit_1E3840A1 0;
BA_ "GenSigTimeoutTime_ESL" SG_ 2654486689 CBV_bit4_ActiveWakeupBit_1E3840A1 0;
BA_ "GenSigTimeoutTime_IPC" SG_ 2654486689 CBV_bit4_ActiveWakeupBit_1E3840A1 0;
BA_ "GenSigTimeoutTime_RFHM" SG_ 2654486689 CBV_bit4_ActiveWakeupBit_1E3840A1 0;
BA_ "GenSigTimeoutTime_SGW" SG_ 2654486689 CBV_bit4_ActiveWakeupBit_1E3840A1 0;
BA_ "GenSigTimeoutTime_TCM" SG_ 2654486689 CBV_bit4_ActiveWakeupBit_1E3840A1 0;
BA_ "GenSigTimeoutTime_ADCAM" SG_ 2654486689 CBV_bit6_PartialNtwInfBit_1E3840A1 0;
BA_ "GenSigTimeoutTime_EVCU2" SG_ 2654486689 CBV_bit6_PartialNtwInfBit_1E3840A1 0;
BA_ "GenSigTimeoutTime_VDCM" SG_ 2654486689 CBV_bit6_PartialNtwInfBit_1E3840A1 0;
BA_ "GenSigTimeoutTime_AGSM" SG_ 2654486689 CBV_bit6_PartialNtwInfBit_1E3840A1 0;
BA_ "GenSigTimeoutTime_BCM" SG_ 2654486689 CBV_bit6_PartialNtwInfBit_1E3840A1 0;
BA_ "GenSigTimeoutTime_BSM" SG_ 2654486689 CBV_bit6_PartialNtwInfBit_1E3840A1 0;
BA_ "GenSigTimeoutTime_DTCM" SG_ 2654486689 CBV_bit6_PartialNtwInfBit_1E3840A1 0;
BA_ "GenSigTimeoutTime_ECM" SG_ 2654486689 CBV_bit6_PartialNtwInfBit_1E3840A1 0;
BA_ "GenSigTimeoutTime_ESL" SG_ 2654486689 CBV_bit6_PartialNtwInfBit_1E3840A1 0;
BA_ "GenSigTimeoutTime_IPC" SG_ 2654486689 CBV_bit6_PartialNtwInfBit_1E3840A1 0;
BA_ "GenSigTimeoutTime_RFHM" SG_ 2654486689 CBV_bit6_PartialNtwInfBit_1E3840A1 0;
BA_ "GenSigTimeoutTime_SGW" SG_ 2654486689 CBV_bit6_PartialNtwInfBit_1E3840A1 0;
BA_ "GenSigTimeoutTime_TCM" SG_ 2654486689 CBV_bit6_PartialNtwInfBit_1E3840A1 0;
BA_ "GenSigTimeoutTime_ADCAM" SG_ 2654486689 CBV_bit1_1E3840A1 0;
BA_ "GenSigTimeoutTime_EVCU2" SG_ 2654486689 CBV_bit1_1E3840A1 0;
BA_ "GenSigTimeoutTime_VDCM" SG_ 2654486689 CBV_bit1_1E3840A1 0;
BA_ "GenSigTimeoutTime_AGSM" SG_ 2654486689 CBV_bit1_1E3840A1 0;
BA_ "GenSigTimeoutTime_BCM" SG_ 2654486689 CBV_bit1_1E3840A1 0;
BA_ "GenSigTimeoutTime_BSM" SG_ 2654486689 CBV_bit1_1E3840A1 0;
BA_ "GenSigTimeoutTime_DTCM" SG_ 2654486689 CBV_bit1_1E3840A1 0;
BA_ "GenSigTimeoutTime_ECM" SG_ 2654486689 CBV_bit1_1E3840A1 0;
BA_ "GenSigTimeoutTime_ESL" SG_ 2654486689 CBV_bit1_1E3840A1 0;
BA_ "GenSigTimeoutTime_BCM" SG_ 205 CRC_BRAKE_FD_6 0;
BA_ "GenSigTimeoutTime_BSM" SG_ 205 CRC_BRAKE_FD_6 0;
BA_ "GenSigTimeoutTime_DTCM" SG_ 205 CRC_BRAKE_FD_6 0;
BA_ "GenSigTimeoutTime_ESL" SG_ 205 CRC_BRAKE_FD_6 0;
BA_ "GenSigTimeoutTime_IPC" SG_ 205 CRC_BRAKE_FD_6 0;
BA_ "GenSigTimeoutTime_RFHM" SG_ 205 CRC_BRAKE_FD_6 0;
BA_ "GenSigTimeoutTime_SGW" SG_ 205 CRC_BRAKE_FD_6 0;
BA_ "GenSigTimeoutTime_ADCAM" SG_ 205 MessageCounter_BRAKE_FD_6 0;
BA_ "GenSigTimeoutTime_VDCM" SG_ 205 MessageCounter_BRAKE_FD_6 0;
BA_ "GenSigTimeoutTime_AGSM" SG_ 205 MessageCounter_BRAKE_FD_6 0;
BA_ "GenSigTimeoutTime_BCM" SG_ 205 MessageCounter_BRAKE_FD_6 0;
BA_ "GenSigTimeoutTime_BSM" SG_ 205 MessageCounter_BRAKE_FD_6 0;
BA_ "GenSigTimeoutTime_DTCM" SG_ 205 MessageCounter_BRAKE_FD_6 0;
BA_ "GenSigTimeoutTime_ESL" SG_ 205 MessageCounter_BRAKE_FD_6 0;
BA_ "GenSigTimeoutTime_IPC" SG_ 205 MessageCounter_BRAKE_FD_6 0;
BA_ "GenSigTimeoutTime_RFHM" SG_ 205 MessageCounter_BRAKE_FD_6 0;
BA_ "GenSigTimeoutTime_SGW" SG_ 205 MessageCounter_BRAKE_FD_6 0;
BA_ "GenSigTimeoutTime_ADCAM" SG_ 205 Not_OK_To_Race 0;
BA_ "GenSigTimeoutTime_VDCM" SG_ 205 Not_OK_To_Race 0;
BA_ "GenSigTimeoutTime_AGSM" SG_ 205 Not_OK_To_Race 0;
BA_ "GenSigTimeoutTime_BCM" SG_ 205 Not_OK_To_Race 0;
BA_ "GenSigTimeoutTime_BSM" SG_ 205 Not_OK_To_Race 0;
BA_ "GenSigTimeoutTime_DTCM" SG_ 205 Not_OK_To_Race 0;
BA_ "GenSigTimeoutTime_ESL" SG_ 205 Not_OK_To_Race 0;
BA_ "GenSigTimeoutTime_IPC" SG_ 205 Not_OK_To_Race 0;
BA_ "GenSigTimeoutTime_RFHM" SG_ 205 Not_OK_To_Race 0;
BA_ "GenSigTimeoutTime_SGW" SG_ 205 Not_OK_To_Race 0;
BA_ "GenSigTimeoutTime_TCM" SG_ 205 Not_OK_To_Race 0;
BA_ "GenSigTimeoutTime_ADCAM" SG_ 205 DriverRequested_AxleTrq_BSM 0;
BA_ "GenSigTimeoutTime_VDCM" SG_ 205 DriverRequested_AxleTrq_BSM 0;
BA_ "GenSigTimeoutTime_ADCAM" SG_ 205 TotalAxle_Rq_BSM 0;
BA_ "GenSigTimeoutTime_EVCU2" SG_ 205 TotalAxle_Rq_BSM 0;
BA_ "GenSigTimeoutTime_VDCM" SG_ 205 TotalAxle_Rq_BSM 0;
BA_ "GenSigTimeoutTime_ADCAM" SG_ 205 DriverReq_AxleTrq_Enabled_BSM 0;
BA_ "GenSigTimeoutTime_VDCM" SG_ 205 DriverReq_AxleTrq_Enabled_BSM 0;
BA_ "GenSigTimeoutTime_ADCAM" SG_ 205 TotalAxle_Max_Rq_BSM 0;
BA_ "GenSigTimeoutTime_EVCU2" SG_ 205 TotalAxle_Max_Rq_BSM 0;
BA_ "GenSigTimeoutTime_VDCM" SG_ 205 TotalAxle_Max_Rq_BSM 0;
BA_ "GenSigTimeoutTime_ADCAM" SG_ 205 TotalAxle_Min_Rq_BSM 0;
BA_ "GenSigTimeoutTime_EVCU2" SG_ 205 TotalAxle_Min_Rq_BSM 0;
BA_ "GenSigTimeoutTime_VDCM" SG_ 205 TotalAxle_Min_Rq_BSM 0;
BA_ "GenSigStartValue" SG_ 205 DriverRequested_AxleTrq_BSM 32767;
BA_ "GenSigTimeoutTime_AGSM" SG_ 205 DriverRequested_AxleTrq_BSM 0;
BA_ "GenSigTimeoutTime_ASBS" SG_ 205 DriverRequested_AxleTrq_BSM 0;
BA_ "GenSigTimeoutTime_BCM" SG_ 205 DriverRequested_AxleTrq_BSM 0;
BA_ "GenSigTimeoutTime_BSM" SG_ 205 DriverRequested_AxleTrq_BSM 0;
BA_ "GenSigTimeoutTime_CADM" SG_ 205 DriverRequested_AxleTrq_BSM 0;
BA_ "GenSigTimeoutTime_DMSM" SG_ 205 DriverRequested_AxleTrq_BSM 0;
BA_ "GenSigTimeoutTime_DTCM" SG_ 205 DriverRequested_AxleTrq_BSM 0;
BA_ "GenSigTimeoutTime_ELSDM" SG_ 205 DriverRequested_AxleTrq_BSM 0;
BA_ "GenSigTimeoutTime_ESL" SG_ 205 DriverRequested_AxleTrq_BSM 0;
BA_ "GenSigTimeoutTime_GNMM" SG_ 205 DriverRequested_AxleTrq_BSM 0;
BA_ "GenSigTimeoutTime_HCP" SG_ 205 DriverRequested_AxleTrq_BSM 0;
BA_ "GenSigTimeoutTime_IPC" SG_ 205 DriverRequested_AxleTrq_BSM 0;
BA_ "GenSigTimeoutTime_RFHM" SG_ 205 DriverRequested_AxleTrq_BSM 0;
BA_ "GenSigTimeoutTime_SGW" SG_ 205 DriverRequested_AxleTrq_BSM 0;
BA_ "GenSigTimeoutTime_TCM" SG_ 205 DriverRequested_AxleTrq_BSM 0;
BA_ "GenSigStartValue" SG_ 205 TotalAxle_Rq_BSM 32767;
BA_ "GenSigTimeoutTime_AGSM" SG_ 205 TotalAxle_Rq_BSM 0;
BA_ "GenSigTimeoutTime_ASBS" SG_ 205 TotalAxle_Rq_BSM 0;
BA_ "GenSigTimeoutTime_BCM" SG_ 205 TotalAxle_Rq_BSM 0;
BA_ "GenSigTimeoutTime_BSM" SG_ 205 TotalAxle_Rq_BSM 0;
BA_ "GenSigTimeoutTime_CADM" SG_ 205 TotalAxle_Rq_BSM 0;
BA_ "GenSigTimeoutTime_DMSM" SG_ 205 TotalAxle_Rq_BSM 0;
BA_ "GenSigTimeoutTime_ELSDM" SG_ 205 TotalAxle_Rq_BSM 0;
BA_ "GenSigTimeoutTime_ESL" SG_ 205 TotalAxle_Rq_BSM 0;
BA_ "GenSigTimeoutTime_GNMM" SG_ 205 TotalAxle_Rq_BSM 0;
BA_ "GenSigTimeoutTime_HCP" SG_ 205 TotalAxle_Rq_BSM 0;
BA_ "GenSigTimeoutTime_IPC" SG_ 205 TotalAxle_Rq_BSM 0;
BA_ "GenSigTimeoutTime_ECM" SG_ 2654486672 CBV_bit3_NMCoordinatorBit_1E384090 0;
BA_ "GenSigTimeoutTime_IPC" SG_ 258 BrakePedalPressure 0;
BA_ "GenSigTimeoutTime_RFHM" SG_ 258 BrakePedalPressure 0;
BA_ "GenSigTimeoutTime_ASBS" SG_ 258 CRC_BRAKE2 0;
BA_ "GenSigTimeoutTime_BSM" SG_ 258 CRC_BRAKE2 0;
BA_ "GenSigTimeoutTime_ELSDM" SG_ 258 CRC_BRAKE2 0;
BA_ "GenSigTimeoutTime_IPC" SG_ 258 CRC_BRAKE2 0;
BA_ "GenSigTimeoutTime_AGSM" SG_ 258 CmndTotBrkFrictTorq_FW 0;
BA_ "GenSigTimeoutTime_ASBS" SG_ 258 CmndTotBrkFrictTorq_FW 0;
BA_ "GenSigTimeoutTime_BCM" SG_ 258 CmndTotBrkFrictTorq_FW 0;
BA_ "GenSigTimeoutTime_BSM" SG_ 258 CmndTotBrkFrictTorq_FW 0;
BA_ "GenSigTimeoutTime_CADM" SG_ 258 CmndTotBrkFrictTorq_FW 0;
BA_ "GenSigTimeoutTime_DMSM" SG_ 258 CmndTotBrkFrictTorq_FW 0;
BA_ "GenSigTimeoutTime_DTCM" SG_ 258 CmndTotBrkFrictTorq_FW 0;
BA_ "GenSigTimeoutTime_ELSDM" SG_ 258 CmndTotBrkFrictTorq_FW 0;
BA_ "GenSigTimeoutTime_ESL" SG_ 258 CmndTotBrkFrictTorq_FW 0;
BA_ "GenSigTimeoutTime_GNMM" SG_ 258 CmndTotBrkFrictTorq_FW 0;
BA_ "GenSigTimeoutTime_IPC" SG_ 258 CmndTotBrkFrictTorq_FW 0;
BA_ "GenSigTimeoutTime_RFHM" SG_ 258 CmndTotBrkFrictTorq_FW 0;
BA_ "GenSigTimeoutTime_SGW" SG_ 258 CmndTotBrkFrictTorq_FW 0;
BA_ "GenSigTimeoutTime_AGSM" SG_ 258 TotIntdTotalBrkTorq_FW 0;
BA_ "GenSigTimeoutTime_ASBS" SG_ 258 TotIntdTotalBrkTorq_FW 0;
BA_ "GenSigTimeoutTime_BCM" SG_ 258 TotIntdTotalBrkTorq_FW 0;
BA_ "GenSigTimeoutTime_BSM" SG_ 258 TotIntdTotalBrkTorq_FW 0;
BA_ "GenSigTimeoutTime_CADM" SG_ 258 TotIntdTotalBrkTorq_FW 0;
BA_ "GenSigTimeoutTime_DMSM" SG_ 258 TotIntdTotalBrkTorq_FW 0;
BA_ "GenSigTimeoutTime_DTCM" SG_ 258 TotIntdTotalBrkTorq_FW 0;
BA_ "GenSigTimeoutTime_ELSDM" SG_ 258 TotIntdTotalBrkTorq_FW 0;
BA_ "GenSigTimeoutTime_ESL" SG_ 258 TotIntdTotalBrkTorq_FW 0;
BA_ "GenSigTimeoutTime_GNMM" SG_ 258 TotIntdTotalBrkTorq_FW 0;
BA_ "GenSigTimeoutTime_IPC" SG_ 258 TotIntdTotalBrkTorq_FW 0;
BA_ "GenSigTimeoutTime_RFHM" SG_ 258 TotIntdTotalBrkTorq_FW 0;
BA_ "GenSigTimeoutTime_SGW" SG_ 258 TotIntdTotalBrkTorq_FW 0;
BA_ "GenSigTimeoutTime_IPC" SG_ 2654486689 CBV_bit1_1E3840A1 0;
BA_ "GenSigTimeoutTime_RFHM" SG_ 2654486689 CBV_bit1_1E3840A1 0;
BA_ "GenSigTimeoutTime_SGW" SG_ 2654486689 CBV_bit1_1E3840A1 0;
BA_ "GenSigTimeoutTime_TCM" SG_ 2654486689 CBV_bit1_1E3840A1 0;
BA_ "GenSigTimeoutTime_ADCAM" SG_ 2654486689 CBV_bit2_1E3840A1 0;
BA_ "GenSigTimeoutTime_EVCU2" SG_ 2654486689 CBV_bit2_1E3840A1 0;
BA_ "GenSigTimeoutTime_VDCM" SG_ 2654486689 CBV_bit2_1E3840A1 0;
BA_ "GenSigTimeoutTime_AGSM" SG_ 2654486689 CBV_bit2_1E3840A1 0;
BA_ "GenSigTimeoutTime_BCM" SG_ 2654486689 CBV_bit2_1E3840A1 0;
BA_ "GenSigTimeoutTime_BSM" SG_ 2654486689 CBV_bit2_1E3840A1 0;
BA_ "GenSigTimeoutTime_DTCM" SG_ 2654486689 CBV_bit2_1E3840A1 0;
BA_ "GenSigTimeoutTime_ECM" SG_ 2654486689 CBV_bit2_1E3840A1 0;
BA_ "GenSigTimeoutTime_ESL" SG_ 2654486689 CBV_bit2_1E3840A1 0;
BA_ "GenSigTimeoutTime_IPC" SG_ 2654486689 CBV_bit2_1E3840A1 0;
BA_ "GenSigTimeoutTime_RFHM" SG_ 2654486689 CBV_bit2_1E3840A1 0;
BA_ "GenSigTimeoutTime_SGW" SG_ 2654486689 CBV_bit2_1E3840A1 0;
BA_ "GenSigTimeoutTime_TCM" SG_ 2654486689 CBV_bit2_1E3840A1 0;
BA_ "GenSigTimeoutTime_ADCAM" SG_ 2654486689 CBV_bit5_1E3840A1 0;
BA_ "GenSigTimeoutTime_EVCU2" SG_ 2654486689 CBV_bit5_1E3840A1 0;
BA_ "GenSigTimeoutTime_VDCM" SG_ 2654486689 CBV_bit5_1E3840A1 0;
BA_ "GenSigTimeoutTime_AGSM" SG_ 2654486689 CBV_bit5_1E3840A1 0;
BA_ "GenSigTimeoutTime_BCM" SG_ 2654486689 CBV_bit5_1E3840A1 0;
BA_ "GenSigTimeoutTime_BSM" SG_ 2654486689 CBV_bit5_1E3840A1 0;
BA_ "GenSigTimeoutTime_DTCM" SG_ 2654486689 CBV_bit5_1E3840A1 0;
BA_ "GenSigTimeoutTime_ECM" SG_ 2654486689 CBV_bit5_1E3840A1 0;
BA_ "GenSigTimeoutTime_ESL" SG_ 2654486689 CBV_bit5_1E3840A1 0;
BA_ "GenSigTimeoutTime_IPC" SG_ 2654486689 CBV_bit5_1E3840A1 0;
BA_ "GenSigTimeoutTime_RFHM" SG_ 2654486689 CBV_bit5_1E3840A1 0;
BA_ "GenSigTimeoutTime_SGW" SG_ 2654486689 CBV_bit5_1E3840A1 0;
BA_ "GenSigTimeoutTime_TCM" SG_ 2654486689 CBV_bit5_1E3840A1 0;
BA_ "GenSigTimeoutTime_ADCAM" SG_ 2654486689 CBV_bit7_1E3840A1 0;
BA_ "GenSigTimeoutTime_EVCU2" SG_ 2654486689 CBV_bit7_1E3840A1 0;
BA_ "GenSigTimeoutTime_VDCM" SG_ 2654486689 CBV_bit7_1E3840A1 0;
BA_ "GenSigTimeoutTime_AGSM" SG_ 2654486689 CBV_bit7_1E3840A1 0;
BA_ "GenSigTimeoutTime_BCM" SG_ 2654486689 CBV_bit7_1E3840A1 0;
BA_ "GenSigTimeoutTime_BSM" SG_ 2654486689 CBV_bit7_1E3840A1 0;
BA_ "GenSigTimeoutTime_DTCM" SG_ 2654486689 CBV_bit7_1E3840A1 0;
BA_ "GenSigTimeoutTime_ECM" SG_ 2654486689 CBV_bit7_1E3840A1 0;
BA_ "GenSigTimeoutTime_ESL" SG_ 2654486689 CBV_bit7_1E3840A1 0;
BA_ "GenSigTimeoutTime_IPC" SG_ 2654486689 CBV_bit7_1E3840A1 0;
BA_ "GenSigTimeoutTime_RFHM" SG_ 2654486689 CBV_bit7_1E3840A1 0;
BA_ "GenSigTimeoutTime_SGW" SG_ 2654486689 CBV_bit7_1E3840A1 0;
BA_ "GenSigTimeoutTime_TCM" SG_ 2654486689 CBV_bit7_1E3840A1 0;
BA_ "GenSigTimeoutTime_ADCAM" SG_ 2654486689 SourceNodeIdentifier_1E3840A1 0;
BA_ "GenSigTimeoutTime_EVCU2" SG_ 2654486689 SourceNodeIdentifier_1E3840A1 0;
BA_ "GenSigTimeoutTime_VDCM" SG_ 2654486689 SourceNodeIdentifier_1E3840A1 0;
BA_ "GenSigTimeoutTime_AGSM" SG_ 2654486689 SourceNodeIdentifier_1E3840A1 0;
BA_ "GenSigTimeoutTime_BCM" SG_ 2654486689 SourceNodeIdentifier_1E3840A1 0;
BA_ "GenSigTimeoutTime_BSM" SG_ 2654486689 SourceNodeIdentifier_1E3840A1 0;
BA_ "GenSigTimeoutTime_DTCM" SG_ 2654486689 SourceNodeIdentifier_1E3840A1 0;
BA_ "GenSigTimeoutTime_ECM" SG_ 2654486689 SourceNodeIdentifier_1E3840A1 0;
BA_ "GenSigTimeoutTime_ESL" SG_ 2654486689 SourceNodeIdentifier_1E3840A1 0;
BA_ "GenSigTimeoutTime_IPC" SG_ 2654486689 SourceNodeIdentifier_1E3840A1 0;
BA_ "GenSigTimeoutTime_RFHM" SG_ 2654486689 SourceNodeIdentifier_1E3840A1 0;
BA_ "GenSigTimeoutTime_SGW" SG_ 2654486689 SourceNodeIdentifier_1E3840A1 0;
BA_ "GenSigTimeoutTime_TCM" SG_ 2654486689 SourceNodeIdentifier_1E3840A1 0;
BA_ "GenSigTimeoutTime_ADCAM" SG_ 835 N_PDU_343 0;
BA_ "GenSigTimeoutTime_EVCU2" SG_ 835 N_PDU_343 0;
BA_ "GenSigTimeoutTime_VDCM" SG_ 835 N_PDU_343 0;
BA_ "GenSigTimeoutTime_AGSM" SG_ 835 N_PDU_343 0;
BA_ "GenSigTimeoutTime_BCM" SG_ 835 N_PDU_343 0;
BA_ "GenSigTimeoutTime_BSM" SG_ 835 N_PDU_343 0;
BA_ "GenSigTimeoutTime_DTCM" SG_ 835 N_PDU_343 0;
BA_ "GenSigTimeoutTime_ESL" SG_ 835 N_PDU_343 0;
BA_ "GenSigTimeoutTime_IPC" SG_ 835 N_PDU_343 0;
BA_ "GenSigTimeoutTime_RFHM" SG_ 835 N_PDU_343 0;
BA_ "GenSigTimeoutTime_SGW" SG_ 835 N_PDU_343 0;
BA_ "GenSigTimeoutTime_TCM" SG_ 835 N_PDU_343 0;
BA_ "GenSigTimeoutTime_ADCAM" SG_ 2564480497 N_PDU_18DADDF1 0;
BA_ "GenSigTimeoutTime_EVCU2" SG_ 2564480497 N_PDU_18DADDF1 0;
BA_ "GenSigTimeoutTime_VDCM" SG_ 2564480497 N_PDU_18DADDF1 0;
BA_ "GenSigTimeoutTime_AGSM" SG_ 2564480497 N_PDU_18DADDF1 0;
BA_ "GenSigTimeoutTime_BCM" SG_ 2564480497 N_PDU_18DADDF1 0;
BA_ "GenSigTimeoutTime_BSM" SG_ 2564480497 N_PDU_18DADDF1 0;
BA_ "GenSigTimeoutTime_DTCM" SG_ 2564480497 N_PDU_18DADDF1 0;
BA_ "GenSigTimeoutTime_ECM" SG_ 2564480497 N_PDU_18DADDF1 0;
BA_ "GenSigTimeoutTime_ESL" SG_ 2564480497 N_PDU_18DADDF1 0;
BA_ "GenSigTimeoutTime_IPC" SG_ 2564480497 N_PDU_18DADDF1 0;
BA_ "GenSigTimeoutTime_RFHM" SG_ 2564480497 N_PDU_18DADDF1 0;
BA_ "GenSigTimeoutTime_SGW" SG_ 2564480497 N_PDU_18DADDF1 0;
BA_ "GenSigTimeoutTime_TCM" SG_ 2564480497 N_PDU_18DADDF1 0;
BA_ "GenSigTimeoutTime_ADCAM" SG_ 834 N_PDU_342 0;
BA_ "GenSigTimeoutTime_EVCU2" SG_ 834 N_PDU_342 0;
BA_ "GenSigTimeoutTime_VDCM" SG_ 834 N_PDU_342 0;
BA_ "GenSigTimeoutTime_AGSM" SG_ 834 N_PDU_342 0;
BA_ "GenSigTimeoutTime_BCM" SG_ 834 N_PDU_342 0;
BA_ "GenSigTimeoutTime_BSM" SG_ 834 N_PDU_342 0;
BA_ "GenSigTimeoutTime_DTCM" SG_ 834 N_PDU_342 0;
BA_ "GenSigTimeoutTime_ECM" SG_ 834 N_PDU_342 0;
BA_ "GenSigTimeoutTime_ESL" SG_ 834 N_PDU_342 0;
BA_ "GenSigTimeoutTime_IPC" SG_ 834 N_PDU_342 0;
BA_ "GenSigTimeoutTime_RFHM" SG_ 834 N_PDU_342 0;
BA_ "GenSigTimeoutTime_TCM" SG_ 834 N_PDU_342 0;
BA_ "GenSigTimeoutTime_ADCAM" SG_ 2564485597 N_PDU_18DAF1DD 0;
BA_ "GenSigTimeoutTime_EVCU2" SG_ 2564485597 N_PDU_18DAF1DD 0;
BA_ "GenSigTimeoutTime_VDCM" SG_ 2564485597 N_PDU_18DAF1DD 0;
BA_ "GenSigTimeoutTime_AGSM" SG_ 2564485597 N_PDU_18DAF1DD 0;
BA_ "GenSigTimeoutTime_BCM" SG_ 2564485597 N_PDU_18DAF1DD 0;
BA_ "GenSigTimeoutTime_BSM" SG_ 2564485597 N_PDU_18DAF1DD 0;
BA_ "GenSigTimeoutTime_DTCM" SG_ 2564485597 N_PDU_18DAF1DD 0;
BA_ "GenSigTimeoutTime_ECM" SG_ 2564485597 N_PDU_18DAF1DD 0;
BA_ "GenSigTimeoutTime_ESL" SG_ 2564485597 N_PDU_18DAF1DD 0;
BA_ "GenSigTimeoutTime_IPC" SG_ 2564485597 N_PDU_18DAF1DD 0;
BA_ "GenSigTimeoutTime_RFHM" SG_ 2564485597 N_PDU_18DAF1DD 0;
BA_ "GenSigTimeoutTime_SGW" SG_ 2564485597 N_PDU_18DAF1DD 0;
BA_ "GenSigTimeoutTime_TCM" SG_ 2564485597 N_PDU_18DAF1DD 0;
BA_ "GenSigTimeoutTime_AGSM" SG_ 2564428025 N_PDU_18DA10F9 0;
BA_ "GenSigTimeoutTime_ASBS" SG_ 2564428025 N_PDU_18DA10F9 0;
BA_ "GenSigTimeoutTime_BCM" SG_ 2564428025 N_PDU_18DA10F9 0;
BA_ "GenSigTimeoutTime_BSM" SG_ 2564428025 N_PDU_18DA10F9 0;
BA_ "GenSigTimeoutTime_CADM" SG_ 2564428025 N_PDU_18DA10F9 0;
BA_ "GenSigTimeoutTime_DMSM" SG_ 2564428025 N_PDU_18DA10F9 0;
BA_ "GenSigTimeoutTime_DTCM" SG_ 2564428025 N_PDU_18DA10F9 0;
BA_ "GenSigTimeoutTime_ECM" SG_ 2564428025 N_PDU_18DA10F9 0;
BA_ "GenSigTimeoutTime_ELSDM" SG_ 2564428025 N_PDU_18DA10F9 0;
BA_ "GenSigTimeoutTime_ESL" SG_ 2564428025 N_PDU_18DA10F9 0;
BA_ "GenSigTimeoutTime_GNMM" SG_ 2564428025 N_PDU_18DA10F9 0;
BA_ "GenSigTimeoutTime_HCP" SG_ 2564428025 N_PDU_18DA10F9 0;
BA_ "GenSigTimeoutTime_IPC" SG_ 2564428025 N_PDU_18DA10F9 0;
BA_ "GenSigTimeoutTime_RFHM" SG_ 2564428025 N_PDU_18DA10F9 0;
BA_ "GenSigTimeoutTime_SGW" SG_ 2564428025 N_PDU_18DA10F9 0;
BA_ "GenSigTimeoutTime_TCM" SG_ 2564428025 N_PDU_18DA10F9 0;
BA_ "GenSigTimeoutTime_AGSM" SG_ 2564554489 N_PDU_18DBFEF9 0;
BA_ "GenSigTimeoutTime_ASBS" SG_ 2564554489 N_PDU_18DBFEF9 0;
BA_ "GenSigTimeoutTime_BCM" SG_ 2564554489 N_PDU_18DBFEF9 0;
BA_ "GenSigTimeoutTime_BSM" SG_ 2564554489 N_PDU_18DBFEF9 0;
BA_ "GenSigTimeoutTime_CADM" SG_ 2564554489 N_PDU_18DBFEF9 0;
BA_ "GenSigTimeoutTime_DMSM" SG_ 2564554489 N_PDU_18DBFEF9 0;
BA_ "GenSigTimeoutTime_DTCM" SG_ 2564554489 N_PDU_18DBFEF9 0;
BA_ "GenSigTimeoutTime_ECM" SG_ 2564554489 N_PDU_18DBFEF9 0;
BA_ "GenSigTimeoutTime_ELSDM" SG_ 2564554489 N_PDU_18DBFEF9 0;
BA_ "GenSigTimeoutTime_ESL" SG_ 2564554489 N_PDU_18DBFEF9 0;
BA_ "GenSigTimeoutTime_GNMM" SG_ 2564554489 N_PDU_18DBFEF9 0;
BA_ "GenSigTimeoutTime_HCP" SG_ 2564554489 N_PDU_18DBFEF9 0;
BA_ "GenSigTimeoutTime_IPC" SG_ 2564554489 N_PDU_18DBFEF9 0;
BA_ "GenSigTimeoutTime_RFHM" SG_ 2564554489 N_PDU_18DBFEF9 0;
BA_ "GenSigTimeoutTime_SGW" SG_ 2564554489 N_PDU_18DBFEF9 0;
BA_ "GenSigTimeoutTime_TCM" SG_ 2564554489 N_PDU_18DBFEF9 0;
BA_ "GenSigTimeoutTime_ADCAM" SG_ 205 CRC_BRAKE_FD_6 0;
BA_ "GenSigTimeoutTime_VDCM" SG_ 205 CRC_BRAKE_FD_6 0;
BA_ "GenSigTimeoutTime_AGSM" SG_ 205 CRC_BRAKE_FD_6 0;
BA_ "GenSigTimeoutTime_CADM" SG_ 262 IntakeAirTemperature_W 0;
BA_ "GenSigTimeoutTime_DMSM" SG_ 262 IntakeAirTemperature_W 0;
BA_ "GenSigTimeoutTime_DTCM" SG_ 262 IntakeAirTemperature_W 0;
BA_ "GenSigTimeoutTime_ECM" SG_ 262 IntakeAirTemperature_W 0;
BA_ "GenSigTimeoutTime_ELSDM" SG_ 262 IntakeAirTemperature_W 0;
BA_ "GenSigTimeoutTime_ESL" SG_ 262 IntakeAirTemperature_W 0;
BA_ "GenSigTimeoutTime_GNMM" SG_ 262 IntakeAirTemperature_W 0;
BA_ "GenSigTimeoutTime_HCP" SG_ 262 IntakeAirTemperature_W 0;
BA_ "GenSigTimeoutTime_IPC" SG_ 262 IntakeAirTemperature_W 0;
BA_ "GenSigTimeoutTime_RFHM" SG_ 262 IntakeAirTemperature_W 0;
BA_ "GenSigTimeoutTime_AGSM" SG_ 262 KickDownRequest_W 0;
BA_ "GenSigTimeoutTime_ASBS" SG_ 262 KickDownRequest_W 0;
BA_ "GenSigTimeoutTime_BCM" SG_ 262 KickDownRequest_W 0;
BA_ "GenSigTimeoutTime_BSM" SG_ 262 KickDownRequest_W 0;
BA_ "GenSigTimeoutTime_CADM" SG_ 262 KickDownRequest_W 0;
BA_ "GenSigTimeoutTime_DMSM" SG_ 262 KickDownRequest_W 0;
BA_ "GenSigTimeoutTime_DTCM" SG_ 262 KickDownRequest_W 0;
BA_ "GenSigTimeoutTime_ECM" SG_ 262 KickDownRequest_W 0;
BA_ "GenSigTimeoutTime_ELSDM" SG_ 262 KickDownRequest_W 0;
BA_ "GenSigTimeoutTime_ESL" SG_ 262 KickDownRequest_W 0;
BA_ "GenSigTimeoutTime_GNMM" SG_ 262 KickDownRequest_W 0;
BA_ "GenSigTimeoutTime_IPC" SG_ 262 KickDownRequest_W 0;
BA_ "GenSigTimeoutTime_RFHM" SG_ 262 KickDownRequest_W 0;
BA_ "GenSigTimeoutTime_SGW" SG_ 262 KickDownRequest_W 0;
BA_ "GenSigTimeoutTime_AGSM" SG_ 262 LV12PwrFreeRq_W 0;
BA_ "GenSigTimeoutTime_ASBS" SG_ 262 LV12PwrFreeRq_W 0;
BA_ "GenSigTimeoutTime_BCM" SG_ 262 LV12PwrFreeRq_W 0;
BA_ "GenSigTimeoutTime_BSM" SG_ 262 LV12PwrFreeRq_W 0;
BA_ "GenSigTimeoutTime_CADM" SG_ 262 LV12PwrFreeRq_W 0;
BA_ "GenSigTimeoutTime_DMSM" SG_ 262 LV12PwrFreeRq_W 0;
BA_ "GenSigTimeoutTime_DTCM" SG_ 262 LV12PwrFreeRq_W 0;
BA_ "GenSigTimeoutTime_ECM" SG_ 262 LV12PwrFreeRq_W 0;
BA_ "GenSigTimeoutTime_ELSDM" SG_ 262 LV12PwrFreeRq_W 0;
BA_ "GenSigTimeoutTime_ESL" SG_ 262 LV12PwrFreeRq_W 0;
BA_ "GenSigTimeoutTime_GNMM" SG_ 262 LV12PwrFreeRq_W 0;
BA_ "GenSigTimeoutTime_IPC" SG_ 262 LV12PwrFreeRq_W 0;
BA_ "GenSigTimeoutTime_RFHM" SG_ 262 LV12PwrFreeRq_W 0;
BA_ "GenSigTimeoutTime_SGW" SG_ 262 LV12PwrFreeRq_W 0;
BA_ "GenSigTimeoutTime_TCM" SG_ 262 LV12PwrFreeRq_W 0;
BA_ "GenSigTimeoutTime_AGSM" SG_ 262 MessageCounter_ENGINE2 0;
BA_ "GenSigTimeoutTime_ASBS" SG_ 262 MessageCounter_ENGINE2 0;
BA_ "GenSigTimeoutTime_ECM" SG_ 262 MessageCounter_ENGINE2 0;
BA_ "GenSigTimeoutTime_ELSDM" SG_ 262 MessageCounter_ENGINE2 0;
BA_ "GenSigTimeoutTime_ESL" SG_ 262 MessageCounter_ENGINE2 0;
BA_ "GenSigTimeoutTime_GNMM" SG_ 262 MessageCounter_ENGINE2 0;
BA_ "GenSigTimeoutTime_IPC" SG_ 262 MessageCounter_ENGINE2 0;
BA_ "GenSigTimeoutTime_RFHM" SG_ 262 MessageCounter_ENGINE2 0;
BA_ "GenSigTimeoutTime_SGW" SG_ 262 MessageCounter_ENGINE2 0;
BA_ "GenSigTimeoutTime_AGSM" SG_ 262 PowertrainPrplsnActv 0;
BA_ "GenSigTimeoutTime_ASBS" SG_ 262 PowertrainPrplsnActv 0;
BA_ "GenSigTimeoutTime_DMSM" SG_ 262 PowertrainPrplsnActv 0;
BA_ "GenSigTimeoutTime_DTCM" SG_ 262 PowertrainPrplsnActv 0;
BA_ "GenSigTimeoutTime_ECM" SG_ 262 PowertrainPrplsnActv 0;
BA_ "GenSigTimeoutTime_ELSDM" SG_ 262 PowertrainPrplsnActv 0;
BA_ "GenSigTimeoutTime_ESL" SG_ 262 PowertrainPrplsnActv 0;
BA_ "GenSigTimeoutTime_GNMM" SG_ 262 PowertrainPrplsnActv 0;
BA_ "GenSigStartValue" SG_ 262 ESS_ENG_ST_W 15;
BA_ "GenSigSendType" SG_ 262 ESS_ENG_ST_W 3;
BA_ "GenSigTimeoutTime_AGSM" SG_ 262 ESS_ENG_ST_W 0;
BA_ "GenSigTimeoutTime_ASBS" SG_ 262 ESS_ENG_ST_W 0;
BA_ "GenSigTimeoutTime_CADM" SG_ 262 ESS_ENG_ST_W 0;
BA_ "GenSigTimeoutTime_ECM" SG_ 262 ESS_ENG_ST_W 0;
BA_ "GenSigTimeoutTime_ELSDM" SG_ 262 ESS_ENG_ST_W 0;
BA_ "GenSigTimeoutTime_ESL" SG_ 262 ESS_ENG_ST_W 0;
BA_ "GenSigTimeoutTime_GNMM" SG_ 262 ESS_ENG_ST_W 0;
BA_ "GenSigTimeoutTime_HCP" SG_ 262 ESS_ENG_ST_W 0;
BA_ "GenSigTimeoutTime_RFHM" SG_ 262 ESS_ENG_ST_W 0;
BA_ "GenSigTimeoutTime_AGSM" SG_ 262 ESS_RqShftPark_W 0;
BA_ "GenSigTimeoutTime_ASBS" SG_ 262 ESS_RqShftPark_W 0;
BA_ "GenSigTimeoutTime_CADM" SG_ 262 ESS_RqShftPark_W 0;
BA_ "GenSigTimeoutTime_DMSM" SG_ 262 ESS_RqShftPark_W 0;
BA_ "GenSigTimeoutTime_DTCM" SG_ 262 ESS_RqShftPark_W 0;
BA_ "GenSigTimeoutTime_ECM" SG_ 262 ESS_RqShftPark_W 0;
BA_ "GenSigTimeoutTime_ELSDM" SG_ 262 ESS_RqShftPark_W 0;
BA_ "GenSigTimeoutTime_ESL" SG_ 262 ESS_RqShftPark_W 0;
BA_ "GenSigTimeoutTime_GNMM" SG_ 262 ESS_RqShftPark_W 0;
BA_ "GenSigTimeoutTime_HCP" SG_ 262 ESS_RqShftPark_W 0;
BA_ "GenSigTimeoutTime_IPC" SG_ 262 ESS_RqShftPark_W 0;
BA_ "GenSigTimeoutTime_RFHM" SG_ 262 ESS_RqShftPark_W 0;
BA_ "GenSigTimeoutTime_SGW" SG_ 262 ESS_RqShftPark_W 0;
BA_ "GenSigTimeoutTime_AGSM" SG_ 262 EVRDesiredSetpoint 0;
BA_ "GenSigTimeoutTime_ASBS" SG_ 262 EVRDesiredSetpoint 0;
BA_ "GenSigTimeoutTime_BCM" SG_ 262 EVRDesiredSetpoint 0;
BA_ "GenSigTimeoutTime_BSM" SG_ 262 EVRDesiredSetpoint 0;
BA_ "GenSigTimeoutTime_CADM" SG_ 262 EVRDesiredSetpoint 0;
BA_ "GenSigTimeoutTime_DMSM" SG_ 262 EVRDesiredSetpoint 0;
BA_ "GenSigTimeoutTime_DTCM" SG_ 262 EVRDesiredSetpoint 0;
BA_ "GenSigTimeoutTime_ECM" SG_ 262 EVRDesiredSetpoint 0;
BA_ "GenSigTimeoutTime_ELSDM" SG_ 262 EVRDesiredSetpoint 0;
BA_ "GenSigTimeoutTime_ESL" SG_ 262 EVRDesiredSetpoint 0;
BA_ "GenSigTimeoutTime_GNMM" SG_ 262 EVRDesiredSetpoint 0;
BA_ "GenSigTimeoutTime_IPC" SG_ 262 EVRDesiredSetpoint 0;
BA_ "GenSigTimeoutTime_RFHM" SG_ 262 EVRDesiredSetpoint 0;
BA_ "GenSigTimeoutTime_SGW" SG_ 262 EVRDesiredSetpoint 0;
BA_ "GenSigTimeoutTime_TCM" SG_ 262 EVRDesiredSetpoint 0;
BA_ "GenSigTimeoutTime_AGSM" SG_ 262 FeedbackASR_ESCReq_W 0;
BA_ "GenSigTimeoutTime_ASBS" SG_ 262 FeedbackASR_ESCReq_W 0;
BA_ "GenSigTimeoutTime_BCM" SG_ 262 FeedbackASR_ESCReq_W 0;
BA_ "GenSigTimeoutTime_CADM" SG_ 262 FeedbackASR_ESCReq_W 0;
BA_ "GenSigTimeoutTime_DMSM" SG_ 262 FeedbackASR_ESCReq_W 0;
BA_ "GenSigTimeoutTime_DTCM" SG_ 262 FeedbackASR_ESCReq_W 0;
BA_ "GenSigTimeoutTime_ECM" SG_ 262 FeedbackASR_ESCReq_W 0;
BA_ "GenSigTimeoutTime_ELSDM" SG_ 262 FeedbackASR_ESCReq_W 0;
BA_ "GenSigTimeoutTime_ESL" SG_ 262 FeedbackASR_ESCReq_W 0;
BA_ "GenSigTimeoutTime_GNMM" SG_ 262 FeedbackASR_ESCReq_W 0;
BA_ "GenSigTimeoutTime_HCP" SG_ 262 FeedbackASR_ESCReq_W 0;
BA_ "GenSigTimeoutTime_IPC" SG_ 262 FeedbackASR_ESCReq_W 0;
BA_ "GenSigTimeoutTime_RFHM" SG_ 262 FeedbackASR_ESCReq_W 0;
BA_ "GenSigTimeoutTime_SGW" SG_ 262 FeedbackASR_ESCReq_W 0;
BA_ "GenSigTimeoutTime_TCM" SG_ 262 FeedbackASR_ESCReq_W 0;
BA_ "GenSigTimeoutTime_AGSM" SG_ 262 GasPedalGradient_W 0;
BA_ "GenSigTimeoutTime_ASBS" SG_ 262 GasPedalGradient_W 0;
BA_ "GenSigTimeoutTime_BSM" SG_ 262 GasPedalGradient_W 0;
BA_ "GenSigTimeoutTime_CADM" SG_ 262 GasPedalGradient_W 0;
BA_ "GenSigTimeoutTime_DMSM" SG_ 262 GasPedalGradient_W 0;
BA_ "GenSigTimeoutTime_DTCM" SG_ 262 GasPedalGradient_W 0;
BA_ "GenSigTimeoutTime_ECM" SG_ 262 GasPedalGradient_W 0;
BA_ "GenSigTimeoutTime_ELSDM" SG_ 262 GasPedalGradient_W 0;
BA_ "GenSigTimeoutTime_ESL" SG_ 262 GasPedalGradient_W 0;
BA_ "GenSigTimeoutTime_GNMM" SG_ 262 GasPedalGradient_W 0;
BA_ "GenSigTimeoutTime_HCP" SG_ 262 GasPedalGradient_W 0;
BA_ "GenSigTimeoutTime_IPC" SG_ 262 GasPedalGradient_W 0;
BA_ "GenSigTimeoutTime_RFHM" SG_ 262 GasPedalGradient_W 0;
BA_ "GenSigTimeoutTime_SGW" SG_ 262 GasPedalGradient_W 0;
BA_ "GenSigTimeoutTime_TCM" SG_ 262 GasPedalGradient_W 0;
BA_ "GenSigTimeoutTime_AGSM" SG_ 262 GasPedalPosition_W 0;
BA_ "GenSigTimeoutTime_ASBS" SG_ 262 GasPedalPosition_W 0;
BA_ "GenSigTimeoutTime_CADM" SG_ 262 GasPedalPosition_W 0;
BA_ "GenSigTimeoutTime_DMSM" SG_ 262 GasPedalPosition_W 0;
BA_ "GenSigTimeoutTime_ECM" SG_ 262 GasPedalPosition_W 0;
BA_ "GenSigTimeoutTime_ELSDM" SG_ 262 GasPedalPosition_W 0;
BA_ "GenSigTimeoutTime_ESL" SG_ 262 GasPedalPosition_W 0;
BA_ "GenSigTimeoutTime_GNMM" SG_ 262 GasPedalPosition_W 0;
BA_ "GenSigTimeoutTime_HCP" SG_ 262 GasPedalPosition_W 0;
BA_ "GenSigTimeoutTime_IPC" SG_ 262 GasPedalPosition_W 0;
BA_ "GenSigTimeoutTime_RFHM" SG_ 262 GasPedalPosition_W 0;
BA_ "GenSigTimeoutTime_AGSM" SG_ 262 EngineIdleRefSpeed 0;
BA_ "GenSigTimeoutTime_ASBS" SG_ 262 EngineIdleRefSpeed 0;
BA_ "GenSigTimeoutTime_BCM" SG_ 262 EngineIdleRefSpeed 0;
BA_ "GenSigTimeoutTime_CADM" SG_ 262 EngineIdleRefSpeed 0;
BA_ "GenSigTimeoutTime_DMSM" SG_ 262 EngineIdleRefSpeed 0;
BA_ "GenSigTimeoutTime_DTCM" SG_ 262 EngineIdleRefSpeed 0;
BA_ "GenSigTimeoutTime_ECM" SG_ 262 EngineIdleRefSpeed 0;
BA_ "GenSigTimeoutTime_ELSDM" SG_ 262 EngineIdleRefSpeed 0;
BA_ "GenSigTimeoutTime_ESL" SG_ 262 EngineIdleRefSpeed 0;
BA_ "GenSigTimeoutTime_GNMM" SG_ 262 EngineIdleRefSpeed 0;
BA_ "GenSigTimeoutTime_IPC" SG_ 262 EngineIdleRefSpeed 0;
BA_ "GenSigTimeoutTime_RFHM" SG_ 262 EngineIdleRefSpeed 0;
BA_ "GenSigTimeoutTime_SGW" SG_ 262 EngineIdleRefSpeed 0;
BA_ "GenSigTimeoutTime_TCM" SG_ 262 EngineIdleRefSpeed 0;
BA_ "GenSigTimeoutTime_AGSM" SG_ 262 EngineSpeed_W 0;
BA_ "GenSigTimeoutTime_ASBS" SG_ 262 EngineSpeed_W 0;
BA_ "GenSigTimeoutTime_DMSM" SG_ 262 EngineSpeed_W 0;
BA_ "GenSigTimeoutTime_ECM" SG_ 262 EngineSpeed_W 0;
BA_ "GenSigTimeoutTime_ESL" SG_ 262 EngineSpeed_W 0;
BA_ "GenSigTimeoutTime_GNMM" SG_ 262 EngineSpeed_W 0;
BA_ "GenSigTimeoutTime_RFHM" SG_ 262 EngineSpeed_W 0;
BA_ "GenSigTimeoutTime_AGSM" SG_ 262 EngineSpeedFailSts_W 0;
BA_ "GenSigTimeoutTime_ASBS" SG_ 262 EngineSpeedFailSts_W 0;
BA_ "GenSigTimeoutTime_BSM" SG_ 262 EngineSpeedFailSts_W 0;
BA_ "GenSigTimeoutTime_CADM" SG_ 262 EngineSpeedFailSts_W 0;
BA_ "GenSigTimeoutTime_DMSM" SG_ 262 EngineSpeedFailSts_W 0;
BA_ "GenSigTimeoutTime_ECM" SG_ 262 EngineSpeedFailSts_W 0;
BA_ "GenSigTimeoutTime_ESL" SG_ 262 EngineSpeedFailSts_W 0;
BA_ "GenSigTimeoutTime_GNMM" SG_ 262 EngineSpeedFailSts_W 0;
BA_ "GenSigTimeoutTime_RFHM" SG_ 262 EngineSpeedFailSts_W 0;
BA_ "GenSigTimeoutTime_TCM" SG_ 262 EngineSpeedFailSts_W 0;
BA_ "GenSigStartValue" SG_ 262 EngineSts_W 3;
BA_ "GenSigTimeoutTime_AGSM" SG_ 262 EngineSts_W 0;
BA_ "GenSigTimeoutTime_ASBS" SG_ 262 EngineSts_W 0;
BA_ "GenSigTimeoutTime_CADM" SG_ 262 EngineSts_W 0;
BA_ "GenSigTimeoutTime_DMSM" SG_ 262 EngineSts_W 0;
BA_ "GenSigTimeoutTime_DTCM" SG_ 262 EngineSts_W 0;
BA_ "GenSigTimeoutTime_ECM" SG_ 262 EngineSts_W 0;
BA_ "GenSigTimeoutTime_ELSDM" SG_ 262 EngineSts_W 0;
BA_ "GenSigTimeoutTime_ESL" SG_ 262 EngineSts_W 0;
BA_ "GenSigTimeoutTime_DTCM" SG_ 2654339073 PreviousCanNMState_FD03_ECM 0;
BA_ "GenSigTimeoutTime_ECM" SG_ 2654339073 PreviousCanNMState_FD03_ECM 0;
BA_ "GenSigTimeoutTime_ELSDM" SG_ 2654339073 PreviousCanNMState_FD03_ECM 0;
BA_ "GenSigTimeoutTime_ESL" SG_ 2654339073 PreviousCanNMState_FD03_ECM 0;
BA_ "GenSigTimeoutTime_GNMM" SG_ 2654339073 PreviousCanNMState_FD03_ECM 0;
BA_ "GenSigTimeoutTime_HCP" SG_ 2654339073 PreviousCanNMState_FD03_ECM 0;
BA_ "GenSigTimeoutTime_IPC" SG_ 2654339073 PreviousCanNMState_FD03_ECM 0;
BA_ "GenSigTimeoutTime_RFHM" SG_ 2654339073 PreviousCanNMState_FD03_ECM 0;
BA_ "GenSigTimeoutTime_TCM" SG_ 2654339073 PreviousCanNMState_FD03_ECM 0;
BA_ "GenSigTimeoutTime_AGSM" SG_ 2654339073 DES_FD03_ECM 0;
BA_ "GenSigTimeoutTime_ASBS" SG_ 2654339073 DES_FD03_ECM 0;
BA_ "GenSigTimeoutTime_BCM" SG_ 2654339073 DES_FD03_ECM 0;
BA_ "GenSigTimeoutTime_BSM" SG_ 2654339073 DES_FD03_ECM 0;
BA_ "GenSigTimeoutTime_CADM" SG_ 2654339073 DES_FD03_ECM 0;
BA_ "GenSigTimeoutTime_DMSM" SG_ 2654339073 DES_FD03_ECM 0;
BA_ "GenSigTimeoutTime_DTCM" SG_ 2654339073 DES_FD03_ECM 0;
BA_ "GenSigTimeoutTime_ECM" SG_ 2654339073 DES_FD03_ECM 0;
BA_ "GenSigTimeoutTime_ELSDM" SG_ 2654339073 DES_FD03_ECM 0;
BA_ "GenSigTimeoutTime_ESL" SG_ 2654339073 DES_FD03_ECM 0;
BA_ "GenSigTimeoutTime_GNMM" SG_ 2654339073 DES_FD03_ECM 0;
BA_ "GenSigTimeoutTime_HCP" SG_ 2654339073 DES_FD03_ECM 0;
BA_ "GenSigTimeoutTime_IPC" SG_ 2654339073 DES_FD03_ECM 0;
BA_ "GenSigTimeoutTime_RFHM" SG_ 2654339073 DES_FD03_ECM 0;
BA_ "GenSigTimeoutTime_TCM" SG_ 2654339073 DES_FD03_ECM 0;
BA_ "GenSigTimeoutTime_AGSM" SG_ 2654339073 DES_FD16_ECM 0;
BA_ "GenSigTimeoutTime_ASBS" SG_ 2654339073 DES_FD16_ECM 0;
BA_ "GenSigTimeoutTime_BCM" SG_ 2654339073 DES_FD16_ECM 0;
BA_ "GenSigTimeoutTime_BSM" SG_ 2654339073 DES_FD16_ECM 0;
BA_ "GenSigTimeoutTime_CADM" SG_ 2654339073 DES_FD16_ECM 0;
BA_ "GenSigTimeoutTime_DMSM" SG_ 2654339073 DES_FD16_ECM 0;
BA_ "GenSigTimeoutTime_DTCM" SG_ 2654339073 DES_FD16_ECM 0;
BA_ "GenSigTimeoutTime_ECM" SG_ 2654339073 DES_FD16_ECM 0;
BA_ "GenSigTimeoutTime_ELSDM" SG_ 2654339073 DES_FD16_ECM 0;
BA_ "GenSigTimeoutTime_ESL" SG_ 2654339073 DES_FD16_ECM 0;
BA_ "GenSigTimeoutTime_GNMM" SG_ 2654339073 DES_FD16_ECM 0;
BA_ "GenSigTimeoutTime_HCP" SG_ 2654339073 DES_FD16_ECM 0;
BA_ "GenSigTimeoutTime_IPC" SG_ 2654339073 DES_FD16_ECM 0;
BA_ "GenSigTimeoutTime_RFHM" SG_ 2654339073 DES_FD16_ECM 0;
BA_ "GenSigTimeoutTime_TCM" SG_ 2654339073 DES_FD16_ECM 0;
BA_ "GenSigTimeoutTime_AGSM" SG_ 2654339073 CurrentCanNMState_FD16_ECM 0;
BA_ "GenSigTimeoutTime_ASBS" SG_ 2654339073 CurrentCanNMState_FD16_ECM 0;
BA_ "GenSigTimeoutTime_BCM" SG_ 2654339073 CurrentCanNMState_FD16_ECM 0;
BA_ "GenSigTimeoutTime_BSM" SG_ 2654339073 CurrentCanNMState_FD16_ECM 0;
BA_ "GenSigTimeoutTime_CADM" SG_ 2654339073 CurrentCanNMState_FD16_ECM 0;
BA_ "GenSigTimeoutTime_DMSM" SG_ 2654339073 CurrentCanNMState_FD16_ECM 0;
BA_ "GenSigTimeoutTime_DTCM" SG_ 2654339073 CurrentCanNMState_FD16_ECM 0;
BA_ "GenSigTimeoutTime_ECM" SG_ 2654339073 CurrentCanNMState_FD16_ECM 0;
BA_ "GenSigTimeoutTime_ELSDM" SG_ 2654339073 CurrentCanNMState_FD16_ECM 0;
BA_ "GenSigTimeoutTime_ESL" SG_ 2654339073 CurrentCanNMState_FD16_ECM 0;
BA_ "GenSigTimeoutTime_GNMM" SG_ 2654339073 CurrentCanNMState_FD16_ECM 0;
BA_ "GenSigTimeoutTime_HCP" SG_ 2654339073 CurrentCanNMState_FD16_ECM 0;
BA_ "GenSigTimeoutTime_IPC" SG_ 2654339073 CurrentCanNMState_FD16_ECM 0;
BA_ "GenSigTimeoutTime_RFHM" SG_ 2654339073 CurrentCanNMState_FD16_ECM 0;
BA_ "GenSigTimeoutTime_TCM" SG_ 2654339073 CurrentCanNMState_FD16_ECM 0;
BA_ "GenSigTimeoutTime_AGSM" SG_ 2654339073 CurrentFailSts_FD16_ECM 0;
BA_ "GenSigTimeoutTime_ASBS" SG_ 2654339073 CurrentFailSts_FD16_ECM 0;
BA_ "GenSigTimeoutTime_BCM" SG_ 2654339073 CurrentFailSts_FD16_ECM 0;
BA_ "GenSigTimeoutTime_BSM" SG_ 2654339073 CurrentFailSts_FD16_ECM 0;
BA_ "GenSigTimeoutTime_CADM" SG_ 2654339073 CurrentFailSts_FD16_ECM 0;
BA_ "GenSigTimeoutTime_DMSM" SG_ 2654339073 CurrentFailSts_FD16_ECM 0;
BA_ "GenSigTimeoutTime_DTCM" SG_ 2654339073 CurrentFailSts_FD16_ECM 0;
BA_ "GenSigTimeoutTime_ECM" SG_ 2654339073 CurrentFailSts_FD16_ECM 0;
BA_ "GenSigTimeoutTime_ELSDM" SG_ 2654339073 CurrentFailSts_FD16_ECM 0;
BA_ "GenSigTimeoutTime_ESL" SG_ 2654339073 CurrentFailSts_FD16_ECM 0;
BA_ "GenSigTimeoutTime_GNMM" SG_ 2654339073 CurrentFailSts_FD16_ECM 0;
BA_ "GenSigTimeoutTime_HCP" SG_ 2654339073 CurrentFailSts_FD16_ECM 0;
BA_ "GenSigTimeoutTime_IPC" SG_ 2654339073 CurrentFailSts_FD16_ECM 0;
BA_ "GenSigTimeoutTime_RFHM" SG_ 2654339073 CurrentFailSts_FD16_ECM 0;
BA_ "GenSigTimeoutTime_TCM" SG_ 2654339073 CurrentFailSts_FD16_ECM 0;
BA_ "GenSigTimeoutTime_AGSM" SG_ 2654339073 EOL_FD16_ECM 0;
BA_ "GenSigTimeoutTime_ASBS" SG_ 2654339073 EOL_FD16_ECM 0;
BA_ "GenSigTimeoutTime_BCM" SG_ 2654339073 EOL_FD16_ECM 0;
BA_ "GenSigTimeoutTime_BSM" SG_ 2654339073 EOL_FD16_ECM 0;
BA_ "GenSigTimeoutTime_CADM" SG_ 2654339073 EOL_FD16_ECM 0;
BA_ "GenSigTimeoutTime_DMSM" SG_ 2654339073 EOL_FD16_ECM 0;
BA_ "GenSigTimeoutTime_DTCM" SG_ 2654339073 EOL_FD16_ECM 0;
BA_ "GenSigTimeoutTime_ECM" SG_ 2654339073 EOL_FD16_ECM 0;
BA_ "GenSigTimeoutTime_ELSDM" SG_ 2654339073 EOL_FD16_ECM 0;
BA_ "GenSigTimeoutTime_ESL" SG_ 2654339073 EOL_FD16_ECM 0;
BA_ "GenSigTimeoutTime_GNMM" SG_ 2654339073 EOL_FD16_ECM 0;
BA_ "GenSigTimeoutTime_HCP" SG_ 2654339073 EOL_FD16_ECM 0;
BA_ "GenSigTimeoutTime_IPC" SG_ 2654339073 EOL_FD16_ECM 0;
BA_ "GenSigTimeoutTime_RFHM" SG_ 2654339073 EOL_FD16_ECM 0;
BA_ "GenSigTimeoutTime_TCM" SG_ 2654339073 EOL_FD16_ECM 0;
BA_ "GenSigTimeoutTime_AGSM" SG_ 2654339073 GenericFailSts_FD16_ECM 0;
BA_ "GenSigTimeoutTime_ASBS" SG_ 2654339073 GenericFailSts_FD16_ECM 0;
BA_ "GenSigTimeoutTime_BCM" SG_ 2654339073 GenericFailSts_FD16_ECM 0;
BA_ "GenSigTimeoutTime_BSM" SG_ 2654339073 GenericFailSts_FD16_ECM 0;
BA_ "GenSigTimeoutTime_CADM" SG_ 2654339073 GenericFailSts_FD16_ECM 0;
BA_ "GenSigTimeoutTime_DMSM" SG_ 2654339073 GenericFailSts_FD16_ECM 0;
BA_ "GenSigTimeoutTime_DTCM" SG_ 2654339073 GenericFailSts_FD16_ECM 0;
BA_ "GenSigTimeoutTime_ECM" SG_ 2654339073 GenericFailSts_FD16_ECM 0;
BA_ "GenSigTimeoutTime_ELSDM" SG_ 2654339073 GenericFailSts_FD16_ECM 0;
BA_ "GenSigTimeoutTime_ESL" SG_ 2654339073 GenericFailSts_FD16_ECM 0;
BA_ "GenSigTimeoutTime_GNMM" SG_ 2654339073 GenericFailSts_FD16_ECM 0;
BA_ "GenSigTimeoutTime_HCP" SG_ 2654339073 GenericFailSts_FD16_ECM 0;
BA_ "GenSigTimeoutTime_IPC" SG_ 2654339073 GenericFailSts_FD16_ECM 0;
BA_ "GenSigTimeoutTime_RFHM" SG_ 2654339073 GenericFailSts_FD16_ECM 0;
BA_ "GenSigTimeoutTime_TCM" SG_ 2654339073 GenericFailSts_FD16_ECM 0;
BA_ "GenSigTimeoutTime_AGSM" SG_ 2654339073 WakeupSource_FD03_ECM 0;
BA_ "GenSigTimeoutTime_ASBS" SG_ 2654339073 WakeupSource_FD03_ECM 0;
BA_ "GenSigTimeoutTime_BCM" SG_ 2654339073 WakeupSource_FD03_ECM 0;
BA_ "GenSigTimeoutTime_BSM" SG_ 2654339073 WakeupSource_FD03_ECM 0;
BA_ "GenSigTimeoutTime_CADM" SG_ 2654339073 WakeupSource_FD03_ECM 0;
BA_ "GenSigTimeoutTime_DMSM" SG_ 2654339073 WakeupSource_FD03_ECM 0;
BA_ "GenSigTimeoutTime_DTCM" SG_ 2654339073 WakeupSource_FD03_ECM 0;
BA_ "GenSigTimeoutTime_ECM" SG_ 2654339073 WakeupSource_FD03_ECM 0;
BA_ "GenSigTimeoutTime_ELSDM" SG_ 2654339073 WakeupSource_FD03_ECM 0;
BA_ "GenSigTimeoutTime_ESL" SG_ 2654339073 WakeupSource_FD03_ECM 0;
BA_ "GenSigTimeoutTime_GNMM" SG_ 2654339073 WakeupSource_FD03_ECM 0;
BA_ "GenSigTimeoutTime_HCP" SG_ 2654339073 WakeupSource_FD03_ECM 0;
BA_ "GenSigTimeoutTime_IPC" SG_ 2654339073 WakeupSource_FD03_ECM 0;
BA_ "GenSigTimeoutTime_RFHM" SG_ 2654339073 WakeupSource_FD03_ECM 0;
BA_ "GenSigTimeoutTime_TCM" SG_ 2654339073 WakeupSource_FD03_ECM 0;
BA_ "GenSigTimeoutTime_AGSM" SG_ 2654339073 CurrentFailSts_FD03_ECM 0;
BA_ "GenSigTimeoutTime_ASBS" SG_ 2654339073 CurrentFailSts_FD03_ECM 0;
BA_ "GenSigTimeoutTime_BSM" SG_ 2654339073 CurrentFailSts_FD03_ECM 0;
BA_ "GenSigTimeoutTime_CADM" SG_ 2654339073 CurrentFailSts_FD03_ECM 0;
BA_ "GenSigTimeoutTime_DMSM" SG_ 2654339073 CurrentFailSts_FD03_ECM 0;
BA_ "GenSigTimeoutTime_DTCM" SG_ 2654339073 CurrentFailSts_FD03_ECM 0;
BA_ "GenSigTimeoutTime_ECM" SG_ 2654339073 CurrentFailSts_FD03_ECM 0;
BA_ "GenSigTimeoutTime_ELSDM" SG_ 2654339073 CurrentFailSts_FD03_ECM 0;
BA_ "GenSigTimeoutTime_ESL" SG_ 2654339073 CurrentFailSts_FD03_ECM 0;
BA_ "GenSigTimeoutTime_GNMM" SG_ 2654339073 CurrentFailSts_FD03_ECM 0;
BA_ "GenSigTimeoutTime_HCP" SG_ 2654339073 CurrentFailSts_FD03_ECM 0;
BA_ "GenSigTimeoutTime_IPC" SG_ 2654339073 CurrentFailSts_FD03_ECM 0;
BA_ "GenSigTimeoutTime_RFHM" SG_ 2654339073 CurrentFailSts_FD03_ECM 0;
BA_ "GenSigTimeoutTime_TCM" SG_ 2654339073 CurrentFailSts_FD03_ECM 0;
BA_ "GenSigTimeoutTime_AGSM" SG_ 2654339073 EOL_FD03_ECM 0;
BA_ "GenSigTimeoutTime_ASBS" SG_ 2654339073 EOL_FD03_ECM 0;
BA_ "GenSigTimeoutTime_BSM" SG_ 2654339073 EOL_FD03_ECM 0;
BA_ "GenSigTimeoutTime_CADM" SG_ 2654339073 EOL_FD03_ECM 0;
BA_ "GenSigTimeoutTime_DMSM" SG_ 2654339073 EOL_FD03_ECM 0;
BA_ "GenSigTimeoutTime_DTCM" SG_ 2654339073 EOL_FD03_ECM 0;
BA_ "GenSigTimeoutTime_ECM" SG_ 2654339073 EOL_FD03_ECM 0;
BA_ "GenSigTimeoutTime_ELSDM" SG_ 2654339073 EOL_FD03_ECM 0;
BA_ "GenSigTimeoutTime_ESL" SG_ 2654339073 EOL_FD03_ECM 0;
BA_ "GenSigTimeoutTime_GNMM" SG_ 2654339073 EOL_FD03_ECM 0;
BA_ "GenSigTimeoutTime_HCP" SG_ 2654339073 EOL_FD03_ECM 0;
BA_ "GenSigTimeoutTime_IPC" SG_ 2654339073 EOL_FD03_ECM 0;
BA_ "GenSigTimeoutTime_RFHM" SG_ 2654339073 EOL_FD03_ECM 0;
BA_ "GenSigTimeoutTime_TCM" SG_ 2654339073 EOL_FD03_ECM 0;
BA_ "GenSigTimeoutTime_AGSM" SG_ 2654339073 GenericFailSts_FD03_ECM 0;
BA_ "GenSigTimeoutTime_ASBS" SG_ 2654339073 GenericFailSts_FD03_ECM 0;
BA_ "GenSigTimeoutTime_BSM" SG_ 2654339073 GenericFailSts_FD03_ECM 0;
BA_ "GenSigTimeoutTime_CADM" SG_ 2654339073 GenericFailSts_FD03_ECM 0;
BA_ "GenSigTimeoutTime_DMSM" SG_ 2654339073 GenericFailSts_FD03_ECM 0;
BA_ "GenSigTimeoutTime_DTCM" SG_ 2654339073 GenericFailSts_FD03_ECM 0;
BA_ "GenSigTimeoutTime_ECM" SG_ 2654339073 GenericFailSts_FD03_ECM 0;
BA_ "GenSigTimeoutTime_ELSDM" SG_ 2654339073 GenericFailSts_FD03_ECM 0;
BA_ "GenSigTimeoutTime_ESL" SG_ 2654339073 GenericFailSts_FD03_ECM 0;
BA_ "GenSigTimeoutTime_GNMM" SG_ 2654339073 GenericFailSts_FD03_ECM 0;
BA_ "GenSigTimeoutTime_HCP" SG_ 2654339073 GenericFailSts_FD03_ECM 0;
BA_ "GenSigTimeoutTime_IPC" SG_ 2654339073 GenericFailSts_FD03_ECM 0;
BA_ "GenSigTimeoutTime_RFHM" SG_ 2654339073 GenericFailSts_FD03_ECM 0;
BA_ "GenSigTimeoutTime_TCM" SG_ 2654339073 GenericFailSts_FD03_ECM 0;
BA_ "GenSigTimeoutTime_ADCAM" SG_ 204 Rear_Axle_Regen_Capacity 0;
BA_ "GenSigTimeoutTime_EVCU2" SG_ 204 Rear_Axle_Regen_Capacity 0;
BA_ "GenSigTimeoutTime_VDCM" SG_ 204 Rear_Axle_Regen_Capacity 0;
BA_ "GenSigTimeoutTime_AGSM" SG_ 204 Rear_Axle_Regen_Capacity 0;
BA_ "GenSigTimeoutTime_BCM" SG_ 204 Rear_Axle_Regen_Capacity 0;
BA_ "GenSigTimeoutTime_DTCM" SG_ 204 Rear_Axle_Regen_Capacity 0;
BA_ "GenSigTimeoutTime_ECM" SG_ 204 Rear_Axle_Regen_Capacity 0;
BA_ "GenSigTimeoutTime_ESL" SG_ 204 Rear_Axle_Regen_Capacity 0;
BA_ "GenSigTimeoutTime_IPC" SG_ 204 Rear_Axle_Regen_Capacity 0;
BA_ "GenSigTimeoutTime_RFHM" SG_ 204 Rear_Axle_Regen_Capacity 0;
BA_ "GenSigTimeoutTime_SGW" SG_ 204 Rear_Axle_Regen_Capacity 0;
BA_ "GenSigTimeoutTime_TCM" SG_ 204 Rear_Axle_Regen_Capacity 0;
BA_ "GenSigTimeoutTime_ADCAM" SG_ 204 Rear_Axle_Est_Regen_Torq 0;
BA_ "GenSigTimeoutTime_EVCU2" SG_ 204 Rear_Axle_Est_Regen_Torq 0;
BA_ "GenSigTimeoutTime_VDCM" SG_ 204 Rear_Axle_Est_Regen_Torq 0;
BA_ "GenSigTimeoutTime_AGSM" SG_ 204 Rear_Axle_Est_Regen_Torq 0;
BA_ "GenSigTimeoutTime_BCM" SG_ 204 Rear_Axle_Est_Regen_Torq 0;
BA_ "GenSigTimeoutTime_DTCM" SG_ 204 Rear_Axle_Est_Regen_Torq 0;
BA_ "GenSigTimeoutTime_ECM" SG_ 204 Rear_Axle_Est_Regen_Torq 0;
BA_ "GenSigTimeoutTime_ESL" SG_ 204 Rear_Axle_Est_Regen_Torq 0;
BA_ "GenSigTimeoutTime_IPC" SG_ 204 Rear_Axle_Est_Regen_Torq 0;
BA_ "GenSigTimeoutTime_RFHM" SG_ 204 Rear_Axle_Est_Regen_Torq 0;
BA_ "GenSigTimeoutTime_SGW" SG_ 204 Rear_Axle_Est_Regen_Torq 0;
BA_ "GenSigTimeoutTime_TCM" SG_ 204 Rear_Axle_Est_Regen_Torq 0;
BA_ "GenSigTimeoutTime_ADCAM" SG_ 204 Front_Axle_Regen_Capacity 0;
BA_ "GenSigTimeoutTime_EVCU2" SG_ 204 Front_Axle_Regen_Capacity 0;
BA_ "GenSigTimeoutTime_VDCM" SG_ 204 Front_Axle_Regen_Capacity 0;
BA_ "GenSigTimeoutTime_AGSM" SG_ 204 Front_Axle_Regen_Capacity 0;
BA_ "GenSigTimeoutTime_BCM" SG_ 204 Front_Axle_Regen_Capacity 0;
BA_ "GenSigTimeoutTime_DTCM" SG_ 204 Front_Axle_Regen_Capacity 0;
BA_ "GenSigTimeoutTime_ECM" SG_ 204 Front_Axle_Regen_Capacity 0;
BA_ "GenSigTimeoutTime_ESL" SG_ 204 Front_Axle_Regen_Capacity 0;
BA_ "GenSigTimeoutTime_IPC" SG_ 204 Front_Axle_Regen_Capacity 0;
BA_ "GenSigTimeoutTime_RFHM" SG_ 204 Front_Axle_Regen_Capacity 0;
BA_ "GenSigTimeoutTime_SGW" SG_ 204 Front_Axle_Regen_Capacity 0;
BA_ "GenSigTimeoutTime_TCM" SG_ 204 Front_Axle_Regen_Capacity 0;
BA_ "GenSigTimeoutTime_ADCAM" SG_ 204 Front_Axle_Est_Regen_Torq 0;
BA_ "GenSigTimeoutTime_EVCU2" SG_ 204 Front_Axle_Est_Regen_Torq 0;
BA_ "GenSigTimeoutTime_VDCM" SG_ 204 Front_Axle_Est_Regen_Torq 0;
BA_ "GenSigTimeoutTime_AGSM" SG_ 204 Front_Axle_Est_Regen_Torq 0;
BA_ "GenSigTimeoutTime_BCM" SG_ 204 Front_Axle_Est_Regen_Torq 0;
BA_ "GenSigTimeoutTime_DTCM" SG_ 204 Front_Axle_Est_Regen_Torq 0;
BA_ "GenSigTimeoutTime_ECM" SG_ 204 Front_Axle_Est_Regen_Torq 0;
BA_ "GenSigTimeoutTime_ESL" SG_ 204 Front_Axle_Est_Regen_Torq 0;
BA_ "GenSigTimeoutTime_IPC" SG_ 204 Front_Axle_Est_Regen_Torq 0;
BA_ "GenSigTimeoutTime_RFHM" SG_ 204 Front_Axle_Est_Regen_Torq 0;
BA_ "GenSigTimeoutTime_SGW" SG_ 204 Front_Axle_Est_Regen_Torq 0;
BA_ "GenSigTimeoutTime_TCM" SG_ 204 Front_Axle_Est_Regen_Torq 0;
BA_ "GenSigTimeoutTime_ADCAM" SG_ 204 MaxRegen_Diff_Axle_Torq_Active 0;
BA_ "GenSigTimeoutTime_EVCU2" SG_ 204 MaxRegen_Diff_Axle_Torq_Active 0;
BA_ "GenSigTimeoutTime_VDCM" SG_ 204 MaxRegen_Diff_Axle_Torq_Active 0;
BA_ "GenSigTimeoutTime_AGSM" SG_ 204 MaxRegen_Diff_Axle_Torq_Active 0;
BA_ "GenSigTimeoutTime_BCM" SG_ 204 MaxRegen_Diff_Axle_Torq_Active 0;
BA_ "GenSigTimeoutTime_DTCM" SG_ 204 MaxRegen_Diff_Axle_Torq_Active 0;
BA_ "GenSigTimeoutTime_ECM" SG_ 204 MaxRegen_Diff_Axle_Torq_Active 0;
BA_ "GenSigTimeoutTime_ESL" SG_ 204 MaxRegen_Diff_Axle_Torq_Active 0;
BA_ "GenSigTimeoutTime_IPC" SG_ 204 MaxRegen_Diff_Axle_Torq_Active 0;
BA_ "GenSigTimeoutTime_RFHM" SG_ 204 MaxRegen_Diff_Axle_Torq_Active 0;
BA_ "GenSigTimeoutTime_SGW" SG_ 204 MaxRegen_Diff_Axle_Torq_Active 0;
BA_ "GenSigTimeoutTime_TCM" SG_ 204 MaxRegen_Diff_Axle_Torq_Active 0;
BA_ "GenSigTimeoutTime_ADCAM" SG_ 204 MaxRegen_Diff_Axle_Torq 0;
BA_ "GenSigTimeoutTime_EVCU2" SG_ 204 MaxRegen_Diff_Axle_Torq 0;
BA_ "GenSigTimeoutTime_VDCM" SG_ 204 MaxRegen_Diff_Axle_Torq 0;
BA_ "GenSigTimeoutTime_AGSM" SG_ 204 MaxRegen_Diff_Axle_Torq 0;
BA_ "GenSigTimeoutTime_BCM" SG_ 204 MaxRegen_Diff_Axle_Torq 0;
BA_ "GenSigTimeoutTime_DTCM" SG_ 204 MaxRegen_Diff_Axle_Torq 0;
BA_ "GenSigTimeoutTime_ECM" SG_ 204 MaxRegen_Diff_Axle_Torq 0;
BA_ "GenSigTimeoutTime_ESL" SG_ 204 MaxRegen_Diff_Axle_Torq 0;
BA_ "GenSigTimeoutTime_IPC" SG_ 204 MaxRegen_Diff_Axle_Torq 0;
BA_ "GenSigTimeoutTime_RFHM" SG_ 204 MaxRegen_Diff_Axle_Torq 0;
BA_ "GenSigTimeoutTime_SGW" SG_ 204 MaxRegen_Diff_Axle_Torq 0;
BA_ "GenSigTimeoutTime_TCM" SG_ 204 MaxRegen_Diff_Axle_Torq 0;
BA_ "GenSigTimeoutTime_ADCAM" SG_ 204 Rear_AxleTorque_Min 0;
BA_ "GenSigTimeoutTime_EVCU2" SG_ 204 Rear_AxleTorque_Min 0;
BA_ "GenSigTimeoutTime_VDCM" SG_ 204 Rear_AxleTorque_Min 0;
BA_ "GenSigStartValue" SG_ 204 Rear_AxleTorque_Min 32767;
BA_ "GenSigTimeoutTime_AGSM" SG_ 204 Rear_AxleTorque_Min 0;
BA_ "GenSigTimeoutTime_BCM" SG_ 204 Rear_AxleTorque_Min 0;
BA_ "GenSigTimeoutTime_DTCM" SG_ 204 Rear_AxleTorque_Min 0;
BA_ "GenSigTimeoutTime_ECM" SG_ 204 Rear_AxleTorque_Min 0;
BA_ "GenSigTimeoutTime_ESL" SG_ 204 Rear_AxleTorque_Min 0;
BA_ "GenSigTimeoutTime_IPC" SG_ 204 Rear_AxleTorque_Min 0;
BA_ "GenSigTimeoutTime_RFHM" SG_ 204 Rear_AxleTorque_Min 0;
BA_ "GenSigTimeoutTime_TCM" SG_ 204 Rear_AxleTorque_Min 0;
BA_ "GenSigTimeoutTime_ADCAM" SG_ 204 Rear_AxleTorque_Max 0;
BA_ "GenSigTimeoutTime_EVCU2" SG_ 204 Rear_AxleTorque_Max 0;
BA_ "GenSigTimeoutTime_VDCM" SG_ 204 Rear_AxleTorque_Max 0;
BA_ "GenSigStartValue" SG_ 204 Rear_AxleTorque_Max 32767;
BA_ "GenSigTimeoutTime_ESL" SG_ 2654486672 CBV_bit3_NMCoordinatorBit_1E384090 0;
BA_ "GenSigTimeoutTime_GNMM" SG_ 2654486672 CBV_bit3_NMCoordinatorBit_1E384090 0;
BA_ "GenSigTimeoutTime_HCP" SG_ 2654486672 CBV_bit3_NMCoordinatorBit_1E384090 0;
BA_ "GenSigTimeoutTime_IPC" SG_ 2654486672 CBV_bit3_NMCoordinatorBit_1E384090 0;
BA_ "GenSigTimeoutTime_RFHM" SG_ 2654486672 CBV_bit3_NMCoordinatorBit_1E384090 0;
BA_ "GenSigTimeoutTime_SGW" SG_ 2654486672 CBV_bit3_NMCoordinatorBit_1E384090 0;
BA_ "GenSigTimeoutTime_TCM" SG_ 2654486672 CBV_bit3_NMCoordinatorBit_1E384090 0;
BA_ "GenSigTimeoutTime_AGSM" SG_ 2654486672 CBV_bit4_ActiveWakeupBit_1E384090 0;
BA_ "GenSigTimeoutTime_ASBS" SG_ 2654486672 CBV_bit4_ActiveWakeupBit_1E384090 0;
BA_ "GenSigTimeoutTime_GNMM" SG_ 262 EngineSts_W 0;
BA_ "GenSigTimeoutTime_RFHM" SG_ 262 EngineSts_W 0;
BA_ "GenSigStartValue" SG_ 262 EngRPM_Tach 65535;
BA_ "GenSigTimeoutTime_AGSM" SG_ 262 EngRPM_Tach 0;
BA_ "GenSigTimeoutTime_ASBS" SG_ 262 EngRPM_Tach 0;
BA_ "GenSigTimeoutTime_BCM" SG_ 262 EngRPM_Tach 0;
BA_ "GenSigTimeoutTime_BSM" SG_ 262 EngRPM_Tach 0;
BA_ "GenSigTimeoutTime_CADM" SG_ 262 EngRPM_Tach 0;
BA_ "GenSigTimeoutTime_DMSM" SG_ 262 EngRPM_Tach 0;
BA_ "GenSigTimeoutTime_DTCM" SG_ 262 EngRPM_Tach 0;
BA_ "GenSigTimeoutTime_ECM" SG_ 262 EngRPM_Tach 0;
BA_ "GenSigTimeoutTime_ELSDM" SG_ 262 EngRPM_Tach 0;
BA_ "GenSigTimeoutTime_ESL" SG_ 262 EngRPM_Tach 0;
BA_ "GenSigTimeoutTime_GNMM" SG_ 262 EngRPM_Tach 0;
BA_ "GenSigTimeoutTime_HCP" SG_ 262 EngRPM_Tach 0;
BA_ "GenSigTimeoutTime_RFHM" SG_ 262 EngRPM_Tach 0;
BA_ "GenSigTimeoutTime_SGW" SG_ 262 EngRPM_Tach 0;
BA_ "GenSigTimeoutTime_TCM" SG_ 262 EngRPM_Tach 0;
BA_ "GenSigTimeoutTime_AGSM" SG_ 262 EngTrq_Enbl_Rq_TCM_W 0;
BA_ "GenSigTimeoutTime_ASBS" SG_ 262 EngTrq_Enbl_Rq_TCM_W 0;
BA_ "GenSigTimeoutTime_BSM" SG_ 262 EngTrq_Enbl_Rq_TCM_W 0;
BA_ "GenSigTimeoutTime_CADM" SG_ 262 EngTrq_Enbl_Rq_TCM_W 0;
BA_ "GenSigTimeoutTime_DMSM" SG_ 262 EngTrq_Enbl_Rq_TCM_W 0;
BA_ "GenSigTimeoutTime_DTCM" SG_ 262 EngTrq_Enbl_Rq_TCM_W 0;
BA_ "GenSigTimeoutTime_ECM" SG_ 262 EngTrq_Enbl_Rq_TCM_W 0;
BA_ "GenSigTimeoutTime_ELSDM" SG_ 262 EngTrq_Enbl_Rq_TCM_W 0;
BA_ "GenSigTimeoutTime_ESL" SG_ 262 EngTrq_Enbl_Rq_TCM_W 0;
BA_ "GenSigTimeoutTime_GNMM" SG_ 262 EngTrq_Enbl_Rq_TCM_W 0;
BA_ "GenSigTimeoutTime_IPC" SG_ 262 EngTrq_Enbl_Rq_TCM_W 0;
BA_ "GenSigTimeoutTime_RFHM" SG_ 262 EngTrq_Enbl_Rq_TCM_W 0;
BA_ "GenSigTimeoutTime_SGW" SG_ 262 EngTrq_Enbl_Rq_TCM_W 0;
BA_ "GenSigTimeoutTime_TCM" SG_ 262 EngTrq_Enbl_Rq_TCM_W 0;
BA_ "GenSigTimeoutTime_AGSM" SG_ 262 CRC_ENGINE2 0;
BA_ "GenSigTimeoutTime_ASBS" SG_ 262 CRC_ENGINE2 0;
BA_ "GenSigTimeoutTime_ECM" SG_ 262 CRC_ENGINE2 0;
BA_ "GenSigTimeoutTime_ELSDM" SG_ 262 CRC_ENGINE2 0;
BA_ "GenSigTimeoutTime_ESL" SG_ 262 CRC_ENGINE2 0;
BA_ "GenSigTimeoutTime_GNMM" SG_ 262 CRC_ENGINE2 0;
BA_ "GenSigTimeoutTime_IPC" SG_ 262 CRC_ENGINE2 0;
BA_ "GenSigTimeoutTime_RFHM" SG_ 262 CRC_ENGINE2 0;
BA_ "GenSigTimeoutTime_SGW" SG_ 262 CRC_ENGINE2 0;
BA_ "GenSigTimeoutTime_AGSM" SG_ 262 ECM_AllwEV_W 0;
BA_ "GenSigTimeoutTime_ASBS" SG_ 262 ECM_AllwEV_W 0;
BA_ "GenSigTimeoutTime_BCM" SG_ 262 ECM_AllwEV_W 0;
BA_ "GenSigTimeoutTime_BSM" SG_ 262 ECM_AllwEV_W 0;
BA_ "GenSigTimeoutTime_CADM" SG_ 262 ECM_AllwEV_W 0;
BA_ "GenSigTimeoutTime_DMSM" SG_ 262 ECM_AllwEV_W 0;
BA_ "GenSigTimeoutTime_DTCM" SG_ 262 ECM_AllwEV_W 0;
BA_ "GenSigTimeoutTime_ECM" SG_ 262 ECM_AllwEV_W 0;
BA_ "GenSigTimeoutTime_ELSDM" SG_ 262 ECM_AllwEV_W 0;
BA_ "GenSigTimeoutTime_ESL" SG_ 262 ECM_AllwEV_W 0;
BA_ "GenSigTimeoutTime_GNMM" SG_ 262 ECM_AllwEV_W 0;
BA_ "GenSigTimeoutTime_IPC" SG_ 262 ECM_AllwEV_W 0;
BA_ "GenSigTimeoutTime_RFHM" SG_ 262 ECM_AllwEV_W 0;
BA_ "GenSigTimeoutTime_SGW" SG_ 262 ECM_AllwEV_W 0;
BA_ "GenSigTimeoutTime_TCM" SG_ 262 ECM_AllwEV_W 0;
BA_ "GenSigTimeoutTime_AGSM" SG_ 262 ECM_IMMO_STAT_CANC_W 0;
BA_ "GenSigTimeoutTime_ASBS" SG_ 262 ECM_IMMO_STAT_CANC_W 0;
BA_ "GenSigTimeoutTime_BSM" SG_ 262 ECM_IMMO_STAT_CANC_W 0;
BA_ "GenSigTimeoutTime_CADM" SG_ 262 ECM_IMMO_STAT_CANC_W 0;
BA_ "GenSigTimeoutTime_DMSM" SG_ 262 ECM_IMMO_STAT_CANC_W 0;
BA_ "GenSigTimeoutTime_DTCM" SG_ 262 ECM_IMMO_STAT_CANC_W 0;
BA_ "GenSigTimeoutTime_ECM" SG_ 262 ECM_IMMO_STAT_CANC_W 0;
BA_ "GenSigTimeoutTime_ELSDM" SG_ 262 ECM_IMMO_STAT_CANC_W 0;
BA_ "GenSigTimeoutTime_ESL" SG_ 262 ECM_IMMO_STAT_CANC_W 0;
BA_ "GenSigTimeoutTime_GNMM" SG_ 262 ECM_IMMO_STAT_CANC_W 0;
BA_ "GenSigTimeoutTime_IPC" SG_ 262 ECM_IMMO_STAT_CANC_W 0;
VAL_ 2654339073 GenericFailSts_FD03_ECM 0 "No_Fail_Present" 1 "Fail_Present";
VAL_ 2654339073 EOL_FD03_ECM 0 "No_EOL_Programming" 1 "EOL_Programming";
VAL_ 2654339073 CurrentFailSts_FD03_ECM 0 "No_Fail_Present" 1 "Fail_Present";
VAL_ 262 TxAC_EMCC_rq_W 0 "False" 1 "True";
VAL_ 262 TRANS_CLU_SLIP_MODE_W 0 "NORMAL" 1 "MDS_RQ" 2 "IDFSO_RQ" 3 "AC_EN_DIS_RQ" 4 "IDFSO_ACTIVE" 5 "MDS_IDFSO_ACT" 7 "SNA";
VAL_ 262 StartRelayBCMCmd_W 0 "Not_Action" 1 "Action";
VAL_ 262 PowertrainPrplsnActv 0 "Off" 1 "Active";
VAL_ 262 LV12PwrFreeRq_W 0 "Level 1 or 2 Power free Mode NOT active" 1 "Level 1 or 2 Power free Mode Active";
VAL_ 262 KickDownRequest_W 0 "No_kd_request" 1 "Kd_request";
VAL_ 262 IntakeAirTemperature_W 255 "SNA";
VAL_ 262 GasPedalPositionFailSts_W 0 "Fail_not_present" 1 "Fail_present";
VAL_ 262 GasPedalPosition_W 255 "SNA";
VAL_ 262 GasPedalGradient_W 255 "SNA";
VAL_ 262 FeedbackASR_ESCReq_W 0 "TorqueReq_ASR_ESCValid" 1 "TorqueReq_ASR_ESCNot_Valid";
VAL_ 262 EVRDesiredSetpoint 255 "SNA";
VAL_ 262 ESS_ENG_ST_W 1 "ENS Stopped / ENS_STOPPED" 2 "ENS Request Start / ENS_RQ_ST" 3 "ENS Running / ENS_RUN" 4 "ENS Stop Pending / ENS_STOP_PEND" 5 "ENS Start protection / ENS_ST_PRTCT" 6 "ENS Start inhibit / ENS_ST_INH" 7 "ENS disabled / ENS_DSBL" 8 "ENS_IHB_LATCH" 9 "ENS Starting / ENS_Starting" 15 "SNA";
VAL_ 262 EngTrq_Enbl_Rq_TCM_W 0 "Not_Active" 1 "Active";
VAL_ 262 EngRPM_Tach 65535 "SNA";
VAL_ 262 EngineSts_W 0 "Engine_Off" 1 "Engine_Cranking" 2 "Engine_On" 3 "SNA";
VAL_ 262 EngineSpeedFailSts_W 0 "Fail_not_present" 1 "Fail_present";
VAL_ 262 EngineSpeed_W 16383 "SNA";
VAL_ 262 EngineIdleRefSpeed 4095 "SNA";
VAL_ 262 EngineFrictionTorque_W 511 "SNA";
VAL_ 262 ECM_LHOM_W 0 "Not_In_Limp_Home" 1 "In_Limp_Home";
VAL_ 262 ECM_LHOM_Trans_W 0 "Limp Home not Active" 1 "No Redundant Torque Req" 2 "Precise Torque +/-15%" 3 "Imprecise Torque";
VAL_ 262 ECM_IMMO_STAT_CANC_W 0 "IS" 1 "KILL" 2 "RUN" 3 "SNA";
VAL_ 262 ECM_AllwEV_W 0 "EV Not Allowed" 1 "EV Allowed";
VAL_ 262 CrankHold_W 0 "Not_Active" 1 "Active";
VAL_ 262 AlternatorFail_W 0 "Alternator_Fail" 1 "Alternator_Not_In_Fail";
VAL_ 258 VehicleSpeedVSOSig 8191 "SNA";
VAL_ 258 LongAccelerationFailSts_BSM 0 "Fail_Not_Present" 1 "Fail_Present";
VAL_ 258 LongAcceleration_BSM 4095 "SNA";
VAL_ 258 LatAccelerationFailSts_BSM 0 "Fail_Not_Present" 1 "Fail_Present";
VAL_ 258 LatAcceleration_BSM 4095 "SNA";
VAL_ 258 ImpendingSkid 0 "Impending_skid_false" 1 "Impending_skid_true";
VAL_ 258 ESP_Sys_Stat 0 "ABSERR_DIAG" 1 "NORM" 2 "HALF" 3 "ABGAS";
VAL_ 258 BrakePedalPressure 2047 "SNA";
VAL_ 258 BrakeInterventionSts 0 "No_active_brake_intervention" 1 "Active_brake_intervention";
VAL_ 258 BrakeBoostPressure 2047 "SNA";
VAL_ 1460 FOTA_Status 0 "No FOTA Event" 1 "Downloading Package from Backend" 2 "Passing Images to Big Target ECUs" 3 "Waiting for HMI Acceptance" 4 "Installing FOTA Updated" 5 "Successful FOTA Update" 6 "FOTA Failure Rollback Successful" 7 "FOTA Failure Complete" 8 "Build Vehicle Library" 9 "Check Campaign Availability" 10 "Check Download Conditions" 11 "Validate Vehicle Package" 12 "Double Check Manifest" 13 "Initiate Authenticated Diagnostic session" 14 "Ready_State" 15 "Rollback";
VAL_ 262 ECM_ParkSL_Status 0 "Initialization" 1 "ParkLk_Sol_DeEnergized" 2 "ParkLk_Sol_Energized" 3 "SNA";
VAL_ 258 Brk_Stat 0 "IDLE" 1 "BRAKING" 2 "NDEF2" 3 "SNA";
VAL_ 280 MRM_STATUS 0 "Not_Active" 1 "MRM_in_Process" 2 "Vehicle_Secure_Request" 3 "Vehicle_Securement_Complete" 4 "Canceled" 7 "SNA";
VAL_ 280 AEB_Systemsts 0 "FCW_Off" 1 "FCW_On_Only_Warning" 2 "FCW_On_Full";
VAL_ 280 ACC_Systemsts 0 "OFF" 1 "ACC_Enabled" 2 "ACC_Engaged" 3 "ACC_Engaged_BrakeOnly" 4 "ACC_Cancel" 5 "NCC_Enabled" 6 "NCC_Engaged" 7 "NCC_Cancel" 8 "HAS_BSoC" 9 "RRCC_Enabled_No_Set_Speed" 10 "RRCC_Enabled_With_Set_Speed" 11 "RRCC_Engaged" 12 "L3_Engaged" 13 "L3_Disengaged" 15 "SNA";
VAL_ 280 ACC_StopStart 0 "DEFAULT" 1 "AutoStop_Allowed" 2 "AutoStart_Allowed" 3 "SNA";
VAL_ 262 EngTrqTgt_SEM 8191 "SNA";
VAL_ 258 TotIntdTotalBrkTorq_FW 16383 "SNA";
VAL_ 2654339073 WakeupSource_FD03_ECM 0 "No_Wakeup";
VAL_ 2654339073 PreviousCanNMState_FD03_ECM 0 "Uninitialized State" 1 "Bus-Sleep State" 2 "Prepare-Bus State" 3 "Ready-Sleep State" 4 "Normal Operation State" 5 "Repeat Message State" 6 "Synchronize State" 7 "Offline State";
VAL_ 2654339073 CurrentCanNMState_FD03_ECM 0 "Uninitialized State" 1 "Bus-Sleep State" 2 "Prepare-Bus State" 3 "Ready-Sleep State" 4 "Normal Operation State" 5 "Repeat Message State" 6 "Synchronize State" 7 "Offline State";
VAL_ 258 CmndTotBrkFrictTorq_FW 16383 "SNA";
VAL_ 262 ESS_EBOOST_BRKHLD_STATUS 0 "Default_Hold_BSM" 1 "ImmediateRelease" 2 "PositiveGradeTorqueBlending" 3 "NegativeGradeTorqueBlending" 7 "SNA";
VAL_ 262 Engine_Stall_Detected 0 "No_Stall_Detected" 1 "Stall_Detected";
VAL_ 262 FullOFC_Actv 0 "Not_Active" 1 "Active";
VAL_ 2654486672 CBV_bit0_RepeatMessageRequestBit_1E384090 0 "Repeat_Message_State_not_requested" 1 "Repeat_Message_State_requested";
VAL_ 2654486672 CBV_bit3_NMCoordinatorBit_1E384090 0 "Start_of_synchronized_shutdown_is_not_requested_by_main_coordinator" 1 "Start_of_synchronized_shutdown_is_requested_by_main_coordinator";
VAL_ 2654486672 CBV_bit4_ActiveWakeupBit_1E384090 0 "PassiveWakeup" 1 "ActiveWakeup";
VAL_ 2654486672 CBV_bit6_PartialNtwInfBit_1E384090 0 "NM_PDU_contains_no_Partial_Network_request_information" 1 "NM_PDU_contains_Partial_Network_request_information";
VAL_ 1460 FOTA_Install_Type 0 "No FOTA" 1 "FOTA Now" 2 "FOTA Schedule" 3 "FOTA Cancelled";
VAL_ 205 TotalAxle_Min_Rq_BSM 0 "Not_Active" 1 "Active";
VAL_ 205 TotalAxle_Max_Rq_BSM 0 "Not_Active" 1 "Active";
VAL_ 205 DriverReq_AxleTrq_Enabled_BSM 0 "No_Req" 1 "ACC_NCC" 2 "SSC" 3 "PPPA" 4 "RRCC" 15 "SNA";
VAL_ 204 Rear_Axle_Regen_Capacity 16383 "SNA";
VAL_ 204 Rear_Axle_Est_Regen_Torq 16383 "SNA";
VAL_ 204 Front_Axle_Regen_Capacity 16383 "SNA";
VAL_ 204 Front_Axle_Est_Regen_Torq 16383 "SNA";
VAL_ 205 TotalAxle_Rq_BSM 65535 "SNA";
VAL_ 205 DriverRequested_AxleTrq_BSM 65535 "SNA";
VAL_ 204 Total_AxleTorque_Min 65535 "SNA";
VAL_ 204 Total_AxleTorque_Max 65535 "SNA";
VAL_ 204 Axle_TorqueStatic_D_TTC 65535 "SNA";
VAL_ 204 Axle_Torque_DrvReqMod 65535 "SNA";
VAL_ 204 Rear_AxleTorque_Min 65535 "SNA";
VAL_ 204 Rear_AxleTorque_Max 65535 "SNA";
VAL_ 204 MaxRegen_Diff_Axle_Torq_Active 0 "Not_Active" 1 "Active";
VAL_ 204 MaxRegen_Diff_Axle_Torq 32767 "SNA";
VAL_ 204 Front_AxleTorque_Min 65535 "SNA";
VAL_ 204 Front_AxleTorque_Max 65535 "SNA";
VAL_ 263 PowertrainPrplsnActv_PT 0 "Not_Active" 1 "Active";
VAL_ 263 GearEngagedForDisplay_PT 0 "Initialize" 1 "Gear_1st" 2 "Gear_2nd" 3 "Gear_3rd" 4 "Gear_4th" 5 "Gear_5th" 6 "Gear_6th" 7 "Gear_7th" 8 "Gear_8th" 9 "Gear_9th" 12 "Park" 13 "Neutral" 14 "Reverse" 15 "Drive" 16 "Low" 17 "Manual" 18 "Sport_Mode" 31 "SNA";
VAL_ 2654339073 WakeupSource_FD16_ECM 0 "No_Wakeup";
VAL_ 2654339073 PreviousCanNMState_FD16_ECM 0 "Uninitialized State" 1 "Bus-Sleep State" 2 "Prepare-Bus State" 3 "Ready-Sleep State" 4 "Normal Operation State" 5 "Repeat Message State" 6 "Synchronize State" 7 "Offline State";
VAL_ 2654339073 GenericFailSts_FD16_ECM 0 "No_Fail_Present" 1 "Fail_Present";
VAL_ 2654339073 EOL_FD16_ECM 0 "No_EOL_Programming" 1 "EOL_Programming";
VAL_ 2654339073 CurrentFailSts_FD16_ECM 0 "No_Fail_Present" 1 "Fail_Present";
VAL_ 2654339073 CurrentCanNMState_FD16_ECM 0 "Uninitialized State" 1 "Bus-Sleep State" 2 "Prepare-Bus State" 3 "Ready-Sleep State" 4 "Normal Operation State" 5 "Repeat Message State" 6 "Synchronize State" 7 "Offline State";
VAL_ 2654486592 CBV_bit4_ActiveWakeupBit_1E384040 0 "PassiveWakeup" 1 "ActiveWakeup";
VAL_ 2654486689 CBV_bit0_RepeatMessageRequestBit_1E3840A1 0 "Repeat_Msg_State_not_requested" 1 "Repeat_Msg_State_requested";
VAL_ 2654486689 CBV_bit3_NMCoordinatorBit_1E3840A1 0 "Synch_shutdown_not_requested" 1 "Synch_shutdown_requested";
VAL_ 2654486689 CBV_bit4_ActiveWakeupBit_1E3840A1 0 "PassiveWakeup" 1 "ActiveWakeup";
VAL_ 2654486689 CBV_bit6_PartialNtwInfBit_1E3840A1 0 "Partial_Network_info_contained" 1 "No_Partial_Network_info_contained";
VAL_ 476 ShiftLeverPositionReq 0 "No_Selection_Active_Or_Available" 1 "P" 2 "R" 3 "N" 4 "D" 5 "L" 6 "TIP_Autostick" 7 "Plus" 8 "Minus" 9 "Sport" 10 "Not_Used" 11 "Not_Used" 12 "Not_Used" 13 "Not_Used" 14 "Not_Used" 15 "SNA";
VAL_ 205 Not_OK_To_Race 0 "Not_OK" 1 "OK" 2 "AwE" 3 "AwA" 4 "Not_Level" 5 "Yaw_Limit_Exceeded" 6 "Max_Revs_Exceeded" 7 "Hardware_Protec";
VAL_ 577 QualifyDriveCycle 0 "Not_Realized" 1 "Realized";
VAL_ 262 EngFSO_TCM_Allw 0 "False" 1 "True";
VAL_ 2654339073 DES_FD16_ECM 0 "Error_Active_state" 1 "Error_passive_warning_state" 2 "Bus_off_state" 3 "Not_used";
VAL_ 2654339073 DES_FD03_ECM 0 "Error_Active_state" 1 "Error_passive_warning_state" 2 "Bus_off_state" 3 "Not_used";
SIG_GROUP_ 262 ENGINE_FD_2_Pkt 1 : TxAC_EMCC_rq_W TRANS_CLU_SLIP_MODE_W StartRelayBCMCmd_W PowertrainPrplsnActv MessageCounter_ENGINE2 LV12PwrFreeRq_W KickDownRequest_W IntakeAirTemperature_W GasPedalPositionFailSts_W GasPedalPosition_W GasPedalGradient_W FeedbackASR_ESCReq_W EVRDesiredSetpoint ESS_RqShftPark_W ESS_ENG_ST_W EngTrq_Enbl_Rq_TCM_W EngRPM_Tach EngineSts_W EngineSpeedFailSts_W EngineSpeed_W EngineIdleRefSpeed EngineFrictionTorque_W ECM_LHOM_W ECM_LHOM_Trans_W ECM_IMMO_STAT_CANC_W ECM_AllwEV_W CRC_ENGINE2 CrankHold_W AlternatorFail_W ECM_ParkSL_Status EngTrqTgt_SEM ESS_EBOOST_BRKHLD_STATUS Engine_Stall_Detected FullOFC_Actv FuelConsumption_GAG_3 EngFSO_TCM_Allw;
SIG_GROUP_ 258 BRAKE_FD_2_Pkt 1 : VehicleSpeedVSOSig MessageCounter_BRAKE2 LongAccelerationFailSts_BSM LongAcceleration_BSM LatAccelerationFailSts_BSM LatAcceleration_BSM ImpendingSkid ESP_Sys_Stat CRC_BRAKE2 BrakePedalPressure BrakeInterventionSts BrakeBoostPressure Brk_Stat TotIntdTotalBrkTorq_FW CmndTotBrkFrictTorq_FW;
SIG_GROUP_ 476 AGSM_FD_2_Pkt 1 : MessageCounter_AGSM2 CRC_AGSM2 ShiftLeverPositionReq;
SIG_GROUP_ 280 ADAS_FD_INFO_Pkt 1 : MessageCounter_ADAS_FD_INFO CRC_ADAS_FD_INFO MRM_STATUS AEB_Systemsts ACC_Systemsts ACC_StopStart;
SIG_GROUP_ 205 BRAKE_FD_6_Pkt 1 : CRC_BRAKE_FD_6 MessageCounter_BRAKE_FD_6 TotalAxle_Min_Rq_BSM TotalAxle_Max_Rq_BSM DriverReq_AxleTrq_Enabled_BSM TotalAxle_Rq_BSM DriverRequested_AxleTrq_BSM Not_OK_To_Race;
SIG_GROUP_ 204 AXLE_TORQUE_FD_1_Pkt 1 : MessageCounter_AXLE_TORQUE_FD_1 CRC_AXLE_TORQUE_FD_1 Rear_Axle_Regen_Capacity Rear_Axle_Est_Regen_Torq Front_Axle_Regen_Capacity Front_Axle_Est_Regen_Torq Total_AxleTorque_Min Total_AxleTorque_Max Axle_TorqueStatic_D_TTC Axle_Torque_DrvReqMod Rear_AxleTorque_Min Rear_AxleTorque_Max MaxRegen_Diff_Axle_Torq_Active MaxRegen_Diff_Axle_Torq Front_AxleTorque_Min Front_AxleTorque_Max;
